VERSION ""

NS_ :

BS_:

BU_: Tester GW APA LCDAR LAS FC BDC ADS ACC FR LCDAL FLC FRC HPP

BO_ 3221225472 VECTOR__INDEPENDENT_SIG_MSG: 0 Vector__XXX
 SG_ HU_CRCCheck_3C4 : 0|8@0+ (1,0) [0|255] "" Vector__XXX
 SG_ HU_RollingCounter_3C4 : 0|4@0+ (1,0) [0|15] "" Vector__XXX
 SG_ HU_RoadCurvature_40m : 0|10@0+ (1,0) [0|1023] "1/m" Vector__XXX
 SG_ HU_RoadCurvature_30m : 0|10@0+ (1,0) [0|1023] "1/m" Vector__XXX
 SG_ HU_RoadCurvature_20m : 0|10@0+ (1,0) [0|1023] "1/m" Vector__XXX
 SG_ HU_RoadCurvature_10m : 0|10@0+ (1,0) [0|1023] "1/m" Vector__XXX
 SG_ HU_Lane_Changtype : 0|2@0+ (1,0) [0|3] "" Vector__XXX
 SG_ HU_To_NumchangeOfLanes_Dist : 0|6@0+ (10,0) [0|600] "m" Vector__XXX
 SG_ HU_CRCCheck_3C6 : 0|8@0+ (1,0) [0|255] "" Vector__XXX
 SG_ HU_RollingCounter_3C6 : 0|4@0+ (1,0) [0|15] "" Vector__XXX
 SG_ HU_RoadCurvature_90m : 0|10@0+ (1,0) [0|1023] "1/m" Vector__XXX
 SG_ HU_RoadCurvature_80m : 0|10@0+ (1,0) [0|1023] "1/m" Vector__XXX
 SG_ HU_RoadCurvature_70m : 0|10@0+ (1,0) [0|1023] "1/m" Vector__XXX
 SG_ HU_RoadCurvature_60m : 0|10@0+ (1,0) [0|1023] "1/m" Vector__XXX
 SG_ HU_RoadCurvature_50m : 0|10@0+ (1,0) [0|1023] "1/m" Vector__XXX
 SG_ HU_BranchInfo : 0|2@0+ (1,0) [0|3] "" Vector__XXX
 SG_ GW_MFS_HODCalibratedStatus : 0|1@0+ (1,0) [0|1] "" Vector__XXX
 SG_ GW_MFS_HODLinStatus : 0|1@0+ (1,0) [0|1] "" Vector__XXX
 SG_ GW_MFS_HODAppStatus : 0|1@0+ (1,0) [0|1] "" Vector__XXX
 SG_ GW_MFS_HODSenserStatus : 0|1@0+ (1,0) [0|1] "" Vector__XXX
 SG_ GW_MFS_HODSystemStatus : 0|3@0+ (1,0) [0|7] "" Vector__XXX
 SG_ GW_MFS_handsoffAbilityDetect : 0|3@0+ (1,0) [0|7] "" Vector__XXX
 SG_ GW_MFS_handsoffDetectResult : 0|3@0+ (1,0) [0|7] "" Vector__XXX
 SG_ GW_MFS_RollingCounter_28C : 0|4@0+ (1,0) [0|15] "" Vector__XXX
 SG_ GW_MFS_DiagInfoSW_28C : 0|3@0+ (1,0) [0|7] "" Vector__XXX
 SG_ HU_CRCCheck_3C7 : 0|8@0+ (1,0) [0|255] "" Vector__XXX
 SG_ HU_RollingCounter_3C7 : 0|4@0+ (1,0) [0|15] "" Vector__XXX
 SG_ HU_MapMatchStatus : 0|2@0+ (1,0) [0|3] "" Vector__XXX
 SG_ HU_SlopeGradient_300m : 0|10@0+ (0.1,-51.1) [-51.1|51.1] "%" Vector__XXX
 SG_ HU_RoadCurvature_600m : 0|10@0+ (1,0) [0|1023] "1/m" Vector__XXX
 SG_ HU_RoadCurvature_400m : 0|10@0+ (1,0) [0|1023] "1/m" Vector__XXX
 SG_ HU_RoadCurvature_300m : 0|10@0+ (1,0) [0|1023] "1/m" Vector__XXX
 SG_ HU_RoadCurvature_100m : 0|10@0+ (1,0) [0|1023] "1/m" Vector__XXX
 SG_ IMS_JawOffsetValue : 0|4@0+ (1,0) [0|15] "cm" Vector__XXX
 SG_ IMS_BrowOffsetValue : 0|4@0+ (1,0) [0|15] "cm" Vector__XXX
 SG_ IMS_RollingCounter_360 : 0|4@0+ (1,0) [0|15] "" Vector__XXX
 SG_ IMS_CRCCheck_360 : 0|8@0+ (1,0) [0|255] "" Vector__XXX
 SG_ IMS_HeadDetectSts_Yaw : 0|8@0+ (1,-75) [-75|75] "deg" Vector__XXX
 SG_ IMS_HeadDetectSts_Roll : 0|8@0+ (1,-45) [-45|45] "deg" Vector__XXX
 SG_ IMS_HeadDetectSts_Pitch : 0|8@0+ (1,-25) [-25|45] "deg" Vector__XXX
 SG_ IMS_PhoneCallSts : 0|1@0+ (1,0) [0|1] "" Vector__XXX
 SG_ IMS_DriverEyesFovArea : 0|4@0+ (1,0) [0|15] "" Vector__XXX
 SG_ IMS_DriverEyeClosestatus : 0|3@0+ (1,0) [0|7] "" Vector__XXX
 SG_ IMS_DriverEyeConfidence : 0|8@0+ (1,0) [0|255] "%" Vector__XXX
 SG_ IMS_DriverEyeDetect : 0|2@0+ (1,0) [0|3] "" Vector__XXX
 SG_ IMS_RollingCounter_356 : 0|4@0+ (1,0) [0|15] "" Vector__XXX
 SG_ IMS_CRCCheck_356 : 0|8@0+ (1,0) [0|255] "" Vector__XXX
 SG_ IMS_IMSStatus : 0|3@0+ (1,0) [0|7] "" Vector__XXX
 SG_ IMS_EyeGazeStatus : 0|8@0+ (1,-75) [-75|75] "deg" Vector__XXX
 SG_ IMS_EyeDetectSatus : 0|8@0+ (1,0) [0|100] "%" Vector__XXX
 SG_ IMS_DrowsinessStatus : 0|3@0+ (1,0) [0|7] "" Vector__XXX
 SG_ IMS_DriverHeadDetect : 0|2@0+ (1,0) [0|3] "" Vector__XXX
 SG_ IMS_DistractionStatus : 0|2@0+ (1,0) [0|3] "" Vector__XXX
 SG_ HU_NavSpeedLimitType : 0|2@0+ (1,0) [0|3] "" Vector__XXX
 SG_ HU_CurveDistance : 0|6@0+ (10,0) [0|600] "m" Vector__XXX
 SG_ HU_EnterCurveInfo : 0|2@0+ (1,0) [0|3] "" Vector__XXX
 SG_ HU_EnterRampInfo : 0|2@0+ (1,0) [0|3] "" Vector__XXX
 SG_ HU_NavCountryCode : 0|8@0+ (1,0) [0|255] "" Vector__XXX
 SG_ HU_NavSpeedLimitUnits : 0|2@0+ (1,0) [0|3] "" Vector__XXX
 SG_ HU_SlopeDistance : 0|6@0+ (10,0) [0|600] "m" Vector__XXX
 SG_ HU_Byroad : 0|2@0+ (1,0) [0|3] "" Vector__XXX
 SG_ HU_RoadCurvatureFar : 0|10@0+ (1,0) [0|1023] "" Vector__XXX
 SG_ HU_RoadCurvature : 0|10@0+ (1,0) [0|1023] "" Vector__XXX
 SG_ HU_EnterSlopeInfo : 0|2@0+ (1,0) [0|3] "" Vector__XXX
 SG_ HU_SpeedLimitDistance : 0|6@0+ (10,0) [0|600] "m" Vector__XXX
 SG_ HU_CRCCheck_3C2 : 0|8@0+ (1,0) [0|255] "" Vector__XXX
 SG_ HU_RollingCounter_3C2 : 0|4@0+ (1,0) [0|15] "" Vector__XXX
 SG_ HU_MapDataUpdateStatus : 0|3@0+ (1,0) [0|7] "" Vector__XXX
 SG_ HU_Road_TrafficFlow : 0|3@0+ (1,0) [0|7] "" Vector__XXX
 SG_ HU_To_Branch_Dis : 0|6@0+ (10,0) [0|600] "m" Vector__XXX
 SG_ HU_To_TrafficAccident_Dis : 0|6@0+ (10,0) [0|600] "m" Vector__XXX
 SG_ HU_TrafficAccident_Info : 0|2@0+ (1,0) [0|3] "" Vector__XXX
 SG_ HU_To_Construction_Dis : 0|6@0+ (10,0) [0|600] "m" Vector__XXX
 SG_ HU_Construction_Info : 0|2@0+ (1,0) [0|3] "" Vector__XXX
 SG_ HU_FallingRockDi : 0|6@0+ (10,0) [0|600] "m" Vector__XXX
 SG_ HU_FallingRockInfo : 0|2@0+ (1,0) [0|3] "" Vector__XXX
 SG_ HU_LaneCnt : 0|3@0+ (1,0) [0|7] "" Vector__XXX
 SG_ HU_ForwardRoadType : 0|3@0+ (1,0) [0|7] "" Vector__XXX
 SG_ HU_RampSide : 0|2@0+ (1,0) [0|3] "" Vector__XXX

BO_ 775 ACC_307: 64 ACC
 SG_ ACC_CSLAEnableStatus : 245|2@0+ (1,0) [0|3] ""  LAS

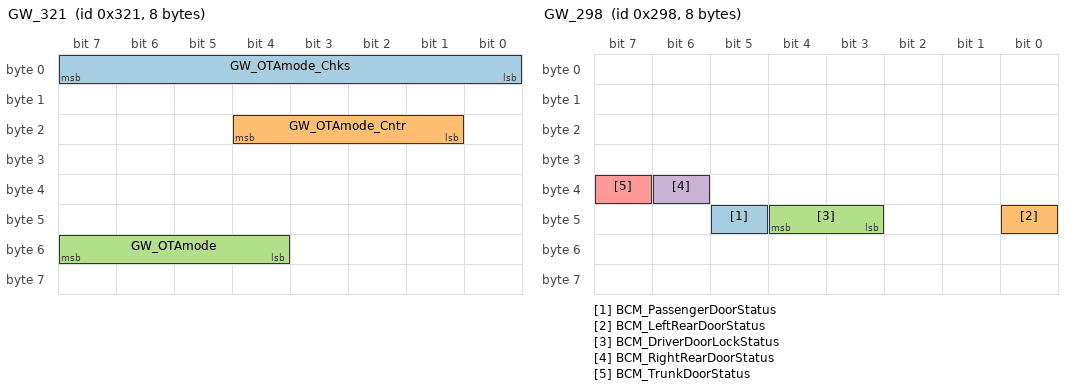
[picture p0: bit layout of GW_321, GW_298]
BO_ 801 GW_321: 8 GW
 SG_ GW_OTAmode_Chks : 7|8@0+ (1,0) [0|255] ""  LAS
 SG_ GW_OTAmode_Cntr : 20|4@0+ (1,0) [0|15] ""  LAS
 SG_ GW_OTAmode : 55|4@0+ (1,0) [0|15] ""  LAS

BO_ 664 GW_298: 8 GW
 SG_ BCM_PassengerDoorStatus : 45|1@0+ (1,0) [0|1] ""  LAS
 SG_ BCM_LeftRearDoorStatus : 40|1@0+ (1,0) [0|1] ""  LAS
 SG_ BCM_DriverDoorLockStatus : 44|2@0+ (1,0) [0|3] ""  LAS
 SG_ BCM_RightRearDoorStatus : 38|1@0+ (1,0) [0|1] ""  LAS
 SG_ BCM_TrunkDoorStatus : 39|1@0+ (1,0) [0|1] ""  LAS

BO_ 2015 DIAG_Function_Req: 8 Tester
 SG_ Functional_Diag_Rx : 7|8@0+ (1,0) [0|0] ""  LAS

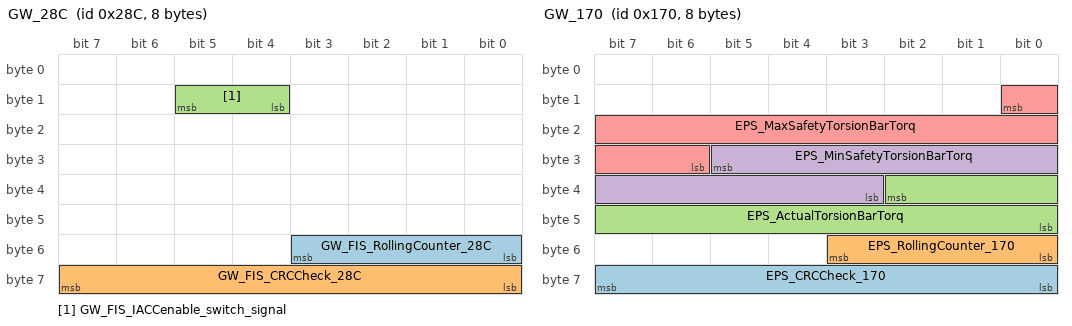
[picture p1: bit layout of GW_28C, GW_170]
BO_ 652 GW_28C: 8 GW
 SG_ GW_FIS_RollingCounter_28C : 51|4@0+ (1,0) [0|15] "0"  LAS
 SG_ GW_FIS_CRCCheck_28C : 63|8@0+ (1,0) [0|255] ""  LAS
 SG_ GW_FIS_IACCenable_switch_signal : 13|2@0+ (1,0) [0|3] ""  GW,BDC,ACC,FR,ADS,LAS

BO_ 864 GW_360: 0 GW

BO_ 854 GW_356: 0 GW

BO_ 368 GW_170: 8 GW
 SG_ EPS_CRCCheck_170 : 63|8@0+ (1,0) [0|255] ""  GW,BDC,ADS,ACC,FR,LAS
 SG_ EPS_RollingCounter_170 : 51|4@0+ (1,0) [0|15] ""  GW,BDC,ADS,ACC,FR,LAS
 SG_ EPS_ActualTorsionBarTorq : 34|11@0+ (0.02,-20.48) [-20.48|20.44] "Nm"  GW,BDC,ADS,ACC,FR,LAS
 SG_ EPS_MinSafetyTorsionBarTorq : 29|11@0+ (0.02,-20.48) [-20.48|20.44] "Nm"  GW,BDC,ADS,ACC,FR,LAS
 SG_ EPS_MaxSafetyTorsionBarTorq : 8|11@0+ (0.02,-20.48) [-20.48|20.44] "Nm"  GW,BDC,ADS,ACC,FR,LAS

BO_ 916 GW_394: 8 GW
 SG_ HU_ELKEnable : 1|2@0+ (1,0) [0|1] ""  GW,BDC,ADS,ACC,FR,LAS
 SG_ HU_TLAEnable : 9|2@0+ (1,0) [0|3] ""  GW,BDC,ADS,ACC,FR,LAS

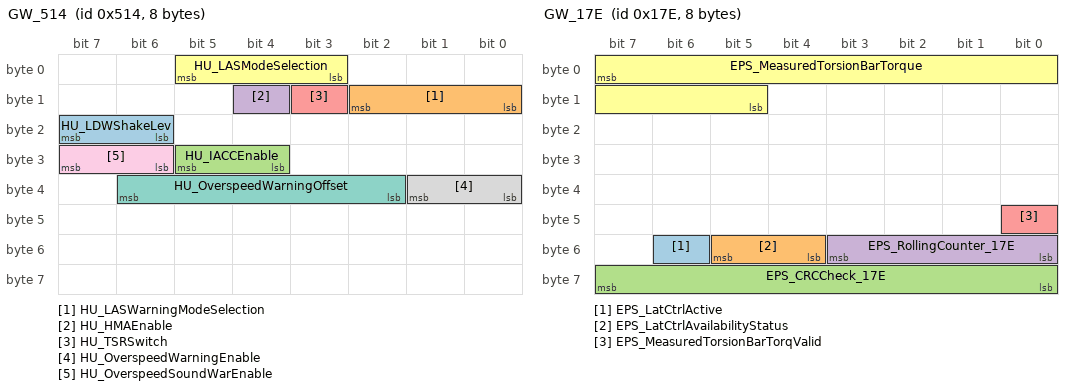
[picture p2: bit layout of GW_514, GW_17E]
BO_ 1300 GW_514: 8 GW
 SG_ HU_LDWShakeLev : 23|2@0+ (1,0) [0|3] ""  GW,BDC,ADS,ACC,FR,LAS
 SG_ HU_LASWarningModeSelection : 10|3@0+ (1,0) [0|7] ""  GW,BDC,APA,ADS,ACC,FR,LAS
 SG_ HU_IACCEnable : 29|2@0+ (1,0) [0|3] ""  GW,BDC,ADS,LAS,ACC,FR
 SG_ HU_HMAEnable : 12|1@0+ (1,0) [0|1] ""  GW,BDC,ADS,ACC,FR,LAS
 SG_ HU_TSRSwitch : 11|1@0+ (1,0) [0|1] ""  GW,BDC,LAS,ADS
 SG_ HU_LASModeSelection : 5|3@0+ (1,0) [0|7] ""  GW,BDC,ADS,ACC,FR,LAS
 SG_ HU_OverspeedWarningOffset : 38|5@0+ (1,-10) [-10|10] ""  GW,BDC,LAS,ADS
 SG_ HU_OverspeedWarningEnable : 33|2@0+ (1,0) [0|3] ""  GW,BDC,LAS
 SG_ HU_OverspeedSoundWarEnable : 31|2@0+ (1,0) [0|3] ""  GW,BDC,LAS,ADS

BO_ 382 GW_17E: 8 GW
 SG_ EPS_LatCtrlActive : 54|1@0+ (1,0) [0|1] ""  GW,BDC,ADS,ACC,FR,LAS
 SG_ EPS_LatCtrlAvailabilityStatus : 53|2@0+ (1,0) [0|3] ""  GW,BDC,ADS,ACC,FR,LAS
 SG_ EPS_CRCCheck_17E : 63|8@0+ (1,0) [0|255] ""  GW,BDC,ADS,ACC,FR,LAS
 SG_ EPS_RollingCounter_17E : 51|4@0+ (1,0) [0|15] ""  GW,BDC,ADS,ACC,FR,LAS
 SG_ EPS_MeasuredTorsionBarTorqValid : 40|1@0+ (1,0) [0|1] ""  GW,BDC,ADS,ACC,FR,LAS
 SG_ EPS_MeasuredTorsionBarTorque : 7|11@0+ (0.01,-10.23) [-10.23|10.23] "Nm"  GW,BDC,ADS,ACC,FR,LAS

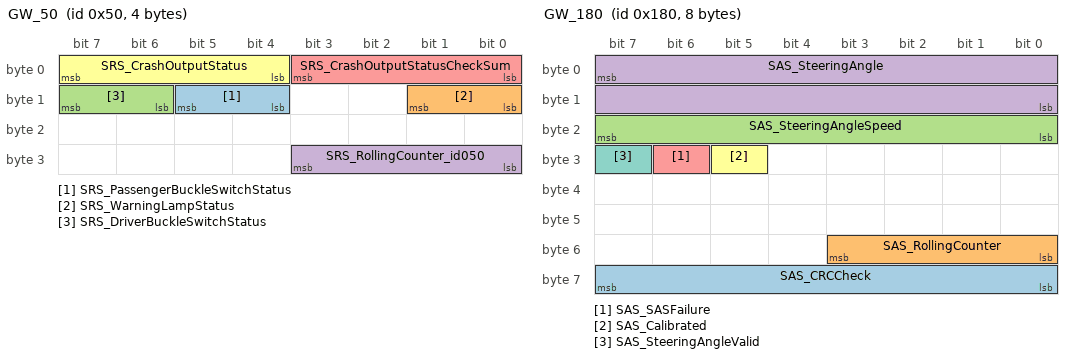
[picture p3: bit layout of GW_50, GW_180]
BO_ 80 GW_50: 4 GW
 SG_ SRS_PassengerBuckleSwitchStatus : 13|2@0+ (1,0) [0|3] ""  GW,BDC,APA,ADS,LAS,LCDAL,LCDAR
 SG_ SRS_WarningLampStatus : 9|2@0+ (1,0) [0|3] ""  GW,BDC,APA,ACC,FR,LAS,LCDAL,LCDAR,FLC,FRC,ADS
 SG_ SRS_DriverBuckleSwitchStatus : 15|2@0+ (1,0) [0|3] ""  GW,BDC,APA,ACC,FR,LAS,LCDAL,LCDAR,FLC,FRC,ADS
 SG_ SRS_RollingCounter_id050 : 27|4@0+ (1,0) [0|15] ""  GW,BDC,APA,ACC,FR,LAS,LCDAL,LCDAR,FLC,FRC,ADS
 SG_ SRS_CrashOutputStatusCheckSum : 3|4@0+ (1,0) [0|15] ""  GW,BDC,APA,ACC,FR,LAS,ADS
 SG_ SRS_CrashOutputStatus : 7|4@0+ (1,0) [0|15] ""  GW,BDC,APA,ACC,FR,LAS,ADS

BO_ 384 GW_180: 8 GW
 SG_ SAS_CRCCheck : 63|8@0+ (1,0) [0|255] ""  GW,BDC,APA,LCDAL,LCDAR,ADS,ACC,FR,LAS,HPP
 SG_ SAS_RollingCounter : 51|4@0+ (1,0) [0|15] ""  GW,BDC,APA,LCDAL,LCDAR,ADS,ACC,FR,LAS,HPP
 SG_ SAS_SteeringAngleSpeed : 23|8@0+ (4,0) [0|1016] "deg/s"  GW,BDC,APA,LCDAL,LCDAR,ADS,ACC,FR,LAS,HPP
 SG_ SAS_SteeringAngle : 7|16@0- (0.1,0) [-780|780] "degree"  GW,BDC,APA,LCDAL,LCDAR,ADS,ACC,FR,LAS,HPP
 SG_ SAS_SASFailure : 30|1@0+ (1,0) [0|1] ""  GW,BDC,APA,LCDAL,LCDAR,ADS,ACC,FR,LAS
 SG_ SAS_Calibrated : 29|1@0+ (1,0) [0|1] ""  GW,BDC,APA,LCDAL,LCDAR,ADS,ACC,FR,LAS
 SG_ SAS_SteeringAngleValid : 31|1@0+ (1,0) [0|1] ""  GW,BDC,APA,LCDAL,LCDAR,ADS,ACC,FR,LAS

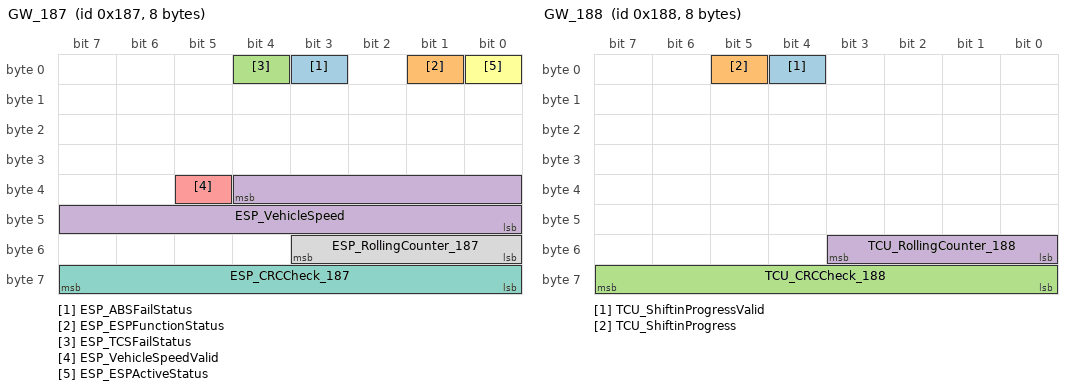
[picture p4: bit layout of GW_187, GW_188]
BO_ 391 GW_187: 8 GW
 SG_ ESP_ABSFailStatus : 3|1@0+ (1,0) [0|1] ""  GW,BDC,APA,ACC,FR,LAS,LCDAL,LCDAR,FLC,FRC,ADS
 SG_ ESP_ESPFunctionStatus : 1|1@0+ (1,0) [0|1] ""  GW,BDC,APA,ACC,FR,LAS,LCDAL,LCDAR,FLC,FRC,ADS
 SG_ ESP_TCSFailStatus : 4|1@0+ (1,0) [0|1] ""  GW,BDC,APA,ACC,FR,LAS,LCDAL,LCDAR,FLC,FRC,ADS
 SG_ ESP_VehicleSpeed : 36|13@0+ (0.05625,0) [0|360] "km/h"  GW,BDC,APA,ACC,FR,LAS,LCDAL,LCDAR,FLC,FRC,ADS,HPP
 SG_ ESP_VehicleSpeedValid : 37|1@0+ (1,0) [0|1] ""  GW,BDC,APA,ACC,FR,LAS,LCDAL,LCDAR,FLC,FRC,ADS,HPP
 SG_ ESP_ESPActiveStatus : 0|1@0+ (1,0) [0|1] ""  GW,BDC,APA,ACC,FR,LAS,LCDAL,LCDAR,FLC,FRC,ADS
 SG_ ESP_CRCCheck_187 : 63|8@0+ (1,0) [0|255] ""  GW,BDC,APA,ACC,FR,LAS,LCDAL,LCDAR,FLC,FRC,ADS,HPP
 SG_ ESP_RollingCounter_187 : 51|4@0+ (1,0) [0|15] ""  GW,BDC,APA,ACC,FR,LAS,LCDAL,LCDAR,FLC,FRC,ADS,HPP

BO_ 392 GW_188: 8 GW
 SG_ TCU_ShiftinProgressValid : 4|1@0+ (1,0) [0|1] ""  GW,BDC,ADS,ACC,FR,LAS
 SG_ TCU_ShiftinProgress : 5|1@0+ (1,0) [0|1] ""  GW,BDC,ADS,ACC,FR,LAS
 SG_ TCU_CRCCheck_188 : 63|8@0+ (1,0) [0|255] ""  GW,BDC,ADS,ACC,FR,LAS
 SG_ TCU_RollingCounter_188 : 51|4@0+ (1,0) [0|15] ""  GW,BDC,ADS,ACC,FR,LAS

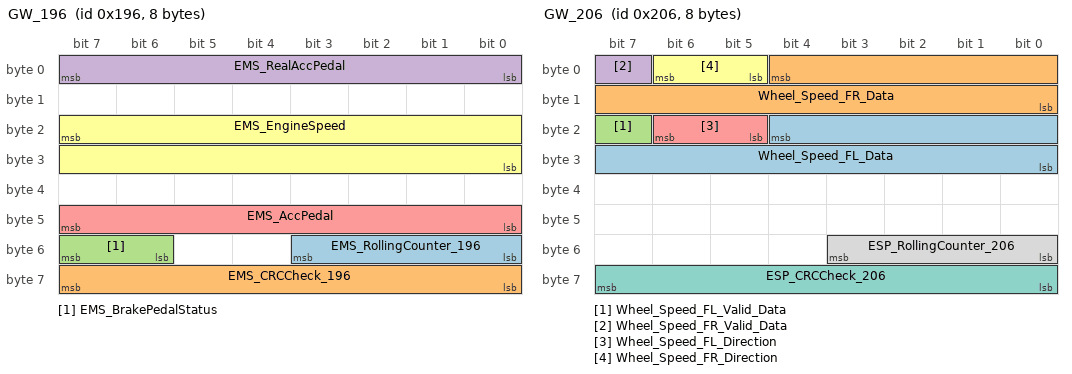
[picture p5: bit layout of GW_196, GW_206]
BO_ 406 GW_196: 8 GW
 SG_ EMS_RollingCounter_196 : 51|4@0+ (1,0) [0|15] ""  GW,BDC,APA,LCDAL,LCDAR,ADS,ACC,FR,FLC,FRC,LAS
 SG_ EMS_CRCCheck_196 : 63|8@0+ (1,0) [0|255] ""  GW,BDC,APA,LCDAL,LCDAR,ADS,ACC,FR,FLC,FRC,LAS
 SG_ EMS_BrakePedalStatus : 55|2@0+ (1,0) [0|3] ""  GW,BDC,APA,LCDAL,LCDAR,ADS,ACC,FR,FLC,FRC,LAS
 SG_ EMS_RealAccPedal : 7|8@0+ (0.392,0) [0|99.568] "%"  GW,BDC,APA,LCDAL,LCDAR,ADS,ACC,FR,FLC,FRC,LAS
 SG_ EMS_AccPedal : 47|8@0+ (0.392,0) [0|99.568] "%"  GW,BDC,APA,ADS,ACC,FR,LAS
 SG_ EMS_EngineSpeed : 23|16@0+ (0.25,0) [0|16383.5] "Rpm"  GW,BDC,APA,ADS,ACC,FR,LAS

BO_ 518 GW_206: 8 GW
 SG_ Wheel_Speed_FL_Data : 20|13@0+ (0.05625,0) [0|360] "km/h"  GW,BDC,APA,ACC,FR,LAS,LCDAL,LCDAR,FLC,FRC,ADS,HPP
 SG_ Wheel_Speed_FR_Data : 4|13@0+ (0.05625,0) [0|360] "km/h"  GW,BDC,APA,ACC,FR,LAS,LCDAL,LCDAR,FLC,FRC,ADS,HPP
 SG_ Wheel_Speed_FL_Valid_Data : 23|1@0+ (1,0) [0|1] ""  GW,BDC,APA,ACC,FR,LAS,LCDAL,LCDAR,FLC,FRC,ADS,HPP
 SG_ Wheel_Speed_FR_Valid_Data : 7|1@0+ (1,0) [0|1] ""  GW,BDC,APA,ACC,FR,LAS,LCDAL,LCDAR,FLC,FRC,ADS,HPP
 SG_ Wheel_Speed_FL_Direction : 22|2@0+ (1,0) [0|3] ""  GW,BDC,APA,ACC,FR,LAS,LCDAL,LCDAR,FLC,FRC,ADS
 SG_ Wheel_Speed_FR_Direction : 6|2@0+ (1,0) [0|3] ""  GW,BDC,APA,ACC,FR,LAS,LCDAL,LCDAR,FLC,FRC,ADS
 SG_ ESP_CRCCheck_206 : 63|8@0+ (1,0) [0|255] ""  GW,BDC,APA,ACC,FR,LAS,LCDAL,LCDAR,FLC,FRC,ADS,HPP
 SG_ ESP_RollingCounter_206 : 51|4@0+ (1,0) [0|15] ""  GW,BDC,APA,ACC,FR,LAS,LCDAL,LCDAR,FLC,FRC,ADS,HPP

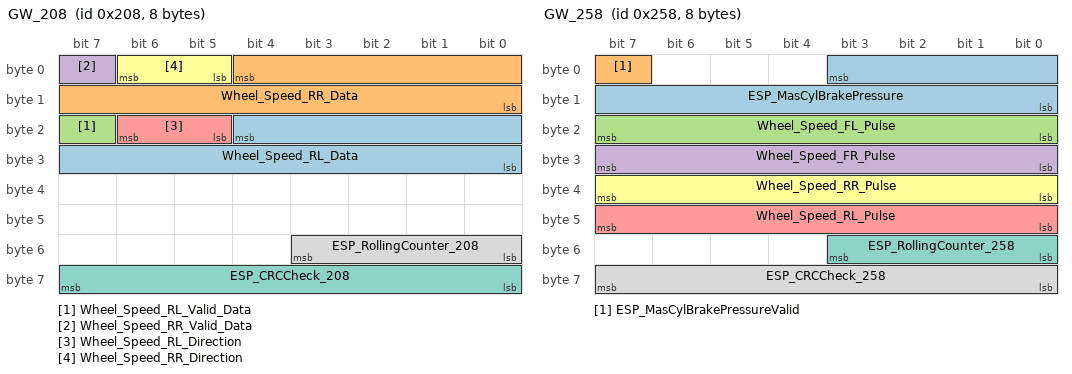
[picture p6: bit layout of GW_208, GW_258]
BO_ 520 GW_208: 8 GW
 SG_ Wheel_Speed_RL_Data : 20|13@0+ (0.05625,0) [0|360] "km/h"  GW,BDC,APA,ACC,FR,LAS,LCDAL,LCDAR,FLC,FRC,ADS,HPP
 SG_ Wheel_Speed_RR_Data : 4|13@0+ (0.05625,0) [0|360] "km/h"  GW,BDC,APA,ACC,FR,LAS,LCDAL,LCDAR,FLC,FRC,ADS,HPP
 SG_ Wheel_Speed_RL_Valid_Data : 23|1@0+ (1,0) [0|1] ""  GW,BDC,APA,ACC,FR,LAS,LCDAL,LCDAR,FLC,FRC,ADS,HPP
 SG_ Wheel_Speed_RR_Valid_Data : 7|1@0+ (1,0) [0|1] ""  GW,BDC,APA,ACC,FR,LAS,LCDAL,LCDAR,FLC,FRC,ADS,HPP
 SG_ Wheel_Speed_RL_Direction : 22|2@0+ (1,0) [0|3] ""  GW,BDC,APA,ACC,FR,LAS,LCDAL,LCDAR,FLC,FRC,ADS
 SG_ Wheel_Speed_RR_Direction : 6|2@0+ (1,0) [0|3] ""  GW,BDC,APA,ACC,FR,LAS,LCDAL,LCDAR,FLC,FRC,ADS
 SG_ ESP_CRCCheck_208 : 63|8@0+ (1,0) [0|255] ""  GW,BDC,APA,ACC,FR,LAS,LCDAL,LCDAR,FLC,FRC,ADS,HPP
 SG_ ESP_RollingCounter_208 : 51|4@0+ (1,0) [0|15] ""  GW,BDC,APA,ACC,FR,LAS,LCDAL,LCDAR,FLC,FRC,ADS,HPP

BO_ 600 GW_258: 8 GW
 SG_ ESP_MasCylBrakePressure : 3|12@0+ (0.1,0) [0|250] "Bar"  GW,BDC,APA,ACC,FR,LAS,LCDAL,LCDAR,FLC,FRC,ADS
 SG_ ESP_MasCylBrakePressureValid : 7|1@0+ (1,0) [0|1] ""  GW,BDC,APA,ACC,FR,LAS,LCDAL,LCDAR,FLC,FRC,ADS
 SG_ Wheel_Speed_FL_Pulse : 23|8@0+ (1,0) [0|254] ""  GW,BDC,APA,ACC,FR,LAS,LCDAL,LCDAR,FLC,FRC,ADS,HPP
 SG_ Wheel_Speed_FR_Pulse : 31|8@0+ (1,0) [0|254] ""  GW,BDC,APA,ACC,FR,LAS,LCDAL,LCDAR,FLC,FRC,ADS,HPP
 SG_ Wheel_Speed_RL_Pulse : 47|8@0+ (1,0) [0|254] ""  GW,BDC,APA,ACC,FR,LAS,LCDAL,LCDAR,FLC,FRC,ADS,HPP
 SG_ Wheel_Speed_RR_Pulse : 39|8@0+ (1,0) [0|254] ""  GW,BDC,APA,ACC,FR,LAS,LCDAL,LCDAR,FLC,FRC,ADS,HPP
 SG_ ESP_RollingCounter_258 : 51|4@0+ (1,0) [0|15] ""  GW,BDC,APA,ACC,FR,LAS,LCDAL,LCDAR,FLC,FRC,ADS,HPP
 SG_ ESP_CRCCheck_258 : 63|8@0+ (1,0) [0|255] ""  GW,BDC,APA,ACC,FR,LAS,LCDAL,LCDAR,FLC,FRC,ADS,HPP

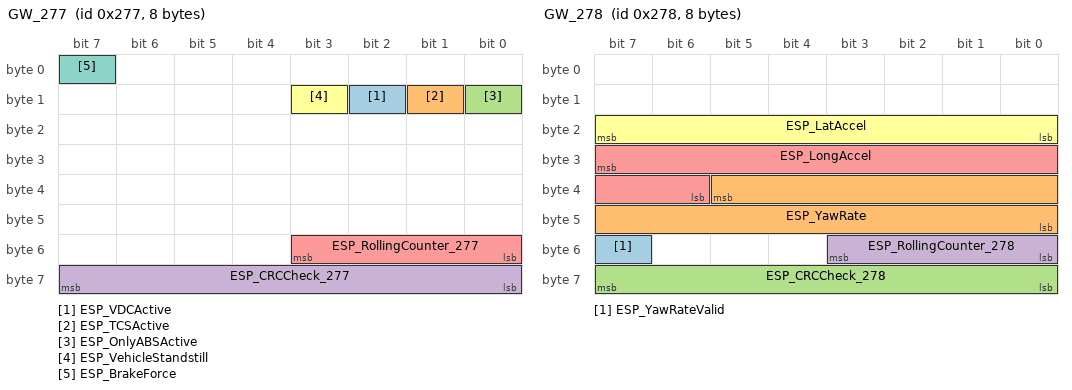
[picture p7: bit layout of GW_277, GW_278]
BO_ 631 GW_277: 8 GW
 SG_ ESP_VDCActive : 10|1@0+ (1,0) [0|1] ""  GW,BDC,ADS,ACC,FR,LCDAL,LCDAR,FLC,FRC,LAS
 SG_ ESP_TCSActive : 9|1@0+ (1,0) [0|1] ""  GW,BDC,ADS,ACC,FR,LCDAL,LCDAR,FLC,FRC,LAS
 SG_ ESP_OnlyABSActive : 8|1@0+ (1,0) [0|1] ""  GW,BDC,ADS,ACC,FR,LCDAL,LCDAR,FLC,FRC,LAS
 SG_ ESP_CRCCheck_277 : 63|8@0+ (1,0) [0|255] ""  GW,BDC,APA,ADS,ACC,FR,LAS,LCDAL,LCDAR,FLC,FRC
 SG_ ESP_RollingCounter_277 : 51|4@0+ (1,0) [0|15] ""  GW,BDC,APA,ADS,ACC,FR,LAS,LCDAL,LCDAR,FLC,FRC
 SG_ ESP_VehicleStandstill : 11|1@0+ (1,0) [0|1] ""  GW,BDC,APA,ADS,ACC,FR,LAS,LCDAL,LCDAR,FLC,FRC
 SG_ ESP_BrakeForce : 7|1@0+ (1,0) [0|1] ""  GW,BDC,ADS,ACC,FR,LCDAL,LCDAR,FLC,FRC,LAS,APA

BO_ 632 GW_278: 8 GW
 SG_ ESP_YawRateValid : 55|1@0+ (1,0) [0|1] ""  GW,BDC,APA,ACC,FR,LAS,LCDAL,LCDAR,FLC,FRC,ADS,HPP
 SG_ ESP_YawRate : 37|14@0+ (0.01,-81.91) [-81.91|81.91] "degree/s"  GW,BDC,APA,ACC,FR,LAS,LCDAL,LCDAR,FLC,FRC,ADS,HPP
 SG_ ESP_CRCCheck_278 : 63|8@0+ (1,0) [0|255] ""  GW,BDC,APA,ACC,FR,LAS,LCDAL,LCDAR,FLC,FRC,ADS,HPP
 SG_ ESP_RollingCounter_278 : 51|4@0+ (1,0) [0|15] ""  GW,BDC,APA,ACC,FR,LAS,LCDAL,LCDAR,FLC,FRC,ADS,HPP
 SG_ ESP_LongAccel : 31|10@0+ (0.03125,-16) [-16|15.90625] "m/s2"  GW,BDC,APA,ACC,FR,LAS,LCDAL,LCDAR,FLC,FRC,ADS,HPP
 SG_ ESP_LatAccel : 23|8@0+ (0.1,-12.7) [-12.7|12.7] "m/s2"  GW,BDC,APA,ACC,FR,LAS,LCDAL,LCDAR,FLC,FRC,ADS,HPP

BO_ 832 GW_340: 8 GW
 SG_ AC_FrBlowType : 2|3@0+ (1,0) [0|7] ""  GW,BDC,ADS,ACC,FR,LAS

BO_ 870 GW_366: 8 GW
 SG_ AC_EnvironmentalTemp : 23|8@0+ (0.5,-40) [-40|87] "degreeC"  GW,BDC,APA,ACC,FR,LAS,LCDAL,LCDAR,FLC,FRC,ADS
 SG_ AC_EnvironmentalTempVD : 8|1@0+ (1,0) [0|1] ""  GW,BDC,APA,ACC,FR,LAS,LCDAL,LCDAR,FLC,FRC,ADS

BO_ 903 GW_387: 8 GW
 SG_ BCM_RainfallLevel : 19|4@0+ (1,0) [0|15] ""  GW,BDC,ADS,ACC,FR,LAS,LCDAL,LCDAR,APA
 SG_ BCM_FrontWiperStatus : 25|2@0+ (1,0) [0|3] ""  GW,BDC,APA,ACC,FR,LAS,LCDAL,LCDAR,FLC,FRC,ADS

BO_ 912 GW_390: 8 GW
 SG_ BCM_SOH_LifePercent : 15|8@0+ (1,0) [0|100] "%"  GW,BDC,ADS,ACC,FR,LAS,LCDAL,LCDAR
 SG_ BCM_PMSLevel : 5|3@0+ (1,0) [0|7] ""  GW,BDC,ADS,ACC,FR,LAS,LCDAL,LCDAR

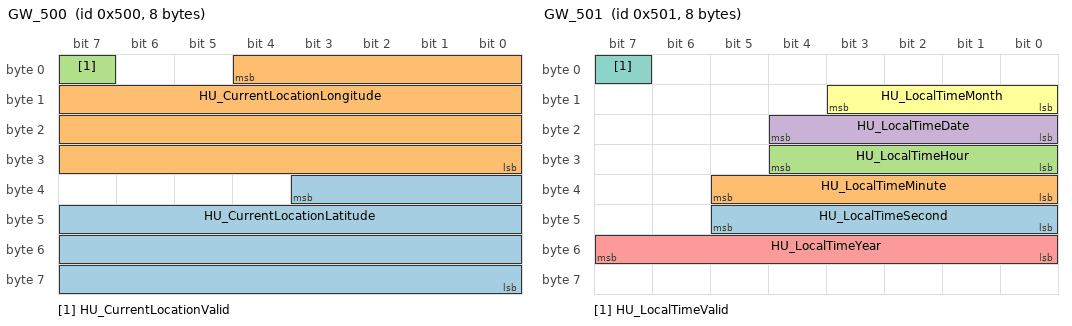
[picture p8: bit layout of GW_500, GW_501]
BO_ 1280 GW_500: 8 GW
 SG_ HU_CurrentLocationLatitude : 35|28@0+ (1E-006,-134.217727) [-90|90] "degree"  GW,BDC,APA,ADS,ACC,FR,LAS,LCDAL,LCDAR
 SG_ HU_CurrentLocationLongitude : 4|29@0+ (1E-006,-268.435455) [-180|180] "degree"  GW,BDC,APA,ADS,ACC,FR,LAS,LCDAL,LCDAR
 SG_ HU_CurrentLocationValid : 7|1@0+ (1,0) [0|1] ""  GW,BDC,APA,ADS,ACC,FR,LAS,LCDAL,LCDAR

BO_ 1281 GW_501: 8 GW
 SG_ HU_LocalTimeSecond : 45|6@0+ (1,0) [0|59] "second"  GW,BDC,APA,ACC,FR,LAS,LCDAL,LCDAR,FLC,FRC,ADS
 SG_ HU_LocalTimeMinute : 37|6@0+ (1,0) [0|59] "minute"  GW,BDC,APA,ACC,FR,LAS,LCDAL,LCDAR,FLC,FRC,ADS
 SG_ HU_LocalTimeHour : 28|5@0+ (1,0) [0|23] "hour"  GW,BDC,APA,ACC,FR,LAS,LCDAL,LCDAR,FLC,FRC,ADS
 SG_ HU_LocalTimeDate : 20|5@0+ (1,0) [1|31] "day"  GW,BDC,APA,ACC,FR,LAS,LCDAL,LCDAR,FLC,FRC,ADS
 SG_ HU_LocalTimeYear : 55|8@0+ (1,2013) [2013|2268] "year"  GW,BDC,APA,ACC,FR,LAS,LCDAL,LCDAR,FLC,FRC,ADS
 SG_ HU_LocalTimeMonth : 11|4@0+ (1,0) [1|12] "month"  GW,BDC,APA,ACC,FR,LAS,LCDAL,LCDAR,FLC,FRC,ADS
 SG_ HU_LocalTimeValid : 7|1@0+ (1,0) [0|1] ""  GW,BDC,APA,ACC,FR,LAS,LCDAL,LCDAR,FLC,FRC,ADS

BO_ 1328 GW_530: 8 GW
 SG_ IP_TotalOdometer : 23|24@0+ (0.1,0) [0|999999] "Km"  GW,BDC,ADS,LAS,ACC,FR,LCDAL,LCDAR,HPP,APA

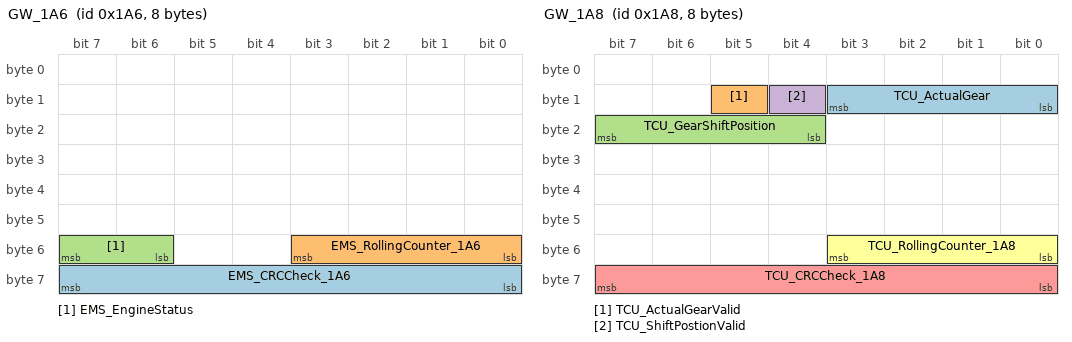
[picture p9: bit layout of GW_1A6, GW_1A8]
BO_ 422 GW_1A6: 8 GW
 SG_ EMS_CRCCheck_1A6 : 63|8@0+ (1,0) [0|255] ""  GW,BDC,APA,ADS,ACC,FR,LAS,LCDAL,LCDAR,FLC,FRC
 SG_ EMS_RollingCounter_1A6 : 51|4@0+ (1,0) [0|15] ""  GW,BDC,APA,ADS,ACC,FR,LAS,LCDAL,LCDAR,FLC,FRC
 SG_ EMS_EngineStatus : 55|2@0+ (1,0) [0|3] ""  GW,BDC,APA,ADS,ACC,FR,LAS,LCDAL,LCDAR,FLC,FRC

BO_ 424 GW_1A8: 8 GW
 SG_ TCU_ActualGear : 11|4@0+ (1,0) [0|15] ""  GW,BDC,APA,ADS,ACC,FR,LAS,LCDAL,LCDAR,FLC,FRC,HPP
 SG_ TCU_ActualGearValid : 13|1@0+ (1,0) [0|1] ""  GW,BDC,APA,ADS,ACC,FR,LAS,LCDAL,LCDAR,FLC,FRC,HPP
 SG_ TCU_GearShiftPosition : 23|4@0+ (1,0) [0|15] ""  GW,BDC,APA,ADS,ACC,FR,LAS,LCDAL,LCDAR,FLC,FRC,HPP
 SG_ TCU_ShiftPostionValid : 12|1@0+ (1,0) [0|1] ""  GW,BDC,APA,ADS,ACC,FR,LAS,LCDAL,LCDAR,FLC,FRC,HPP
 SG_ TCU_CRCCheck_1A8 : 63|8@0+ (1,0) [0|255] ""  GW,BDC,APA,ADS,ACC,FR,LAS,LCDAL,LCDAR,FLC,FRC,HPP
 SG_ TCU_RollingCounter_1A8 : 51|4@0+ (1,0) [0|15] ""  GW,BDC,APA,ADS,ACC,FR,LAS,LCDAL,LCDAR,FLC,FRC,HPP

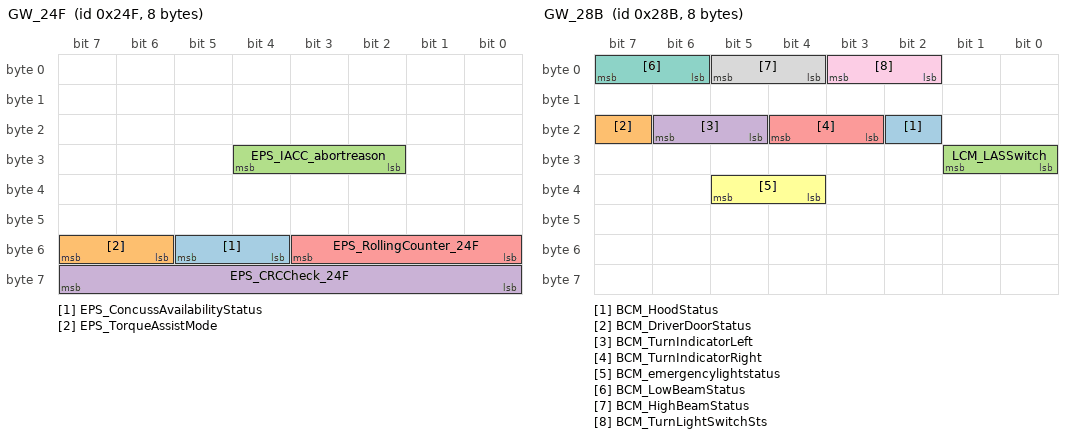
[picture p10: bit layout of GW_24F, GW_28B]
BO_ 591 GW_24F: 8 GW
 SG_ EPS_ConcussAvailabilityStatus : 53|2@0+ (1,0) [0|3] ""  GW,BDC,ADS,ACC,FR,LAS
 SG_ EPS_TorqueAssistMode : 55|2@0+ (1,0) [0|3] ""  GW,BDC,ADS,ACC,FR,LAS
 SG_ EPS_IACC_abortreason : 28|3@0+ (1,0) [0|7] ""  GW,BDC,APA,ADS,ACC,FR,LAS
 SG_ EPS_CRCCheck_24F : 63|8@0+ (1,0) [0|255] ""  GW,BDC,ADS,ACC,FR,LAS,APA
 SG_ EPS_RollingCounter_24F : 51|4@0+ (1,0) [0|15] ""  GW,BDC,ADS,ACC,FR,LAS,APA

BO_ 651 GW_28B: 8 GW
 SG_ BCM_HoodStatus : 18|1@0+ (1,0) [0|1] ""  LAS
 SG_ BCM_DriverDoorStatus : 23|1@0+ (1,0) [0|1] ""  LAS
 SG_ LCM_LASSwitch : 25|2@0+ (1,0) [0|3] ""  GW,BDC,APA,ADS,LAS
 SG_ BCM_TurnIndicatorLeft : 22|2@0+ (1,0) [0|3] ""  GW,BDC,APA,ADS,ACC,FR,LAS
 SG_ BCM_TurnIndicatorRight : 20|2@0+ (1,0) [0|3] ""  GW,BDC,APA,ADS,ACC,FR,LAS
 SG_ BCM_emergencylightstatus : 37|2@0+ (1,0) [0|3] ""  GW,BDC,APA,ADS,LAS,ACC
 SG_ BCM_LowBeamStatus : 7|2@0+ (1,0) [0|3] ""  GW,BDC,ADS,LAS,APA
 SG_ BCM_HighBeamStatus : 5|2@0+ (1,0) [0|3] ""  GW,BDC,ADS,LAS,APA
 SG_ BCM_TurnLightSwitchSts : 3|2@0+ (1,0) [0|3] ""  GW,BDC,APA,LCDAL,LCDAR,ADS,LAS,ACC,FR

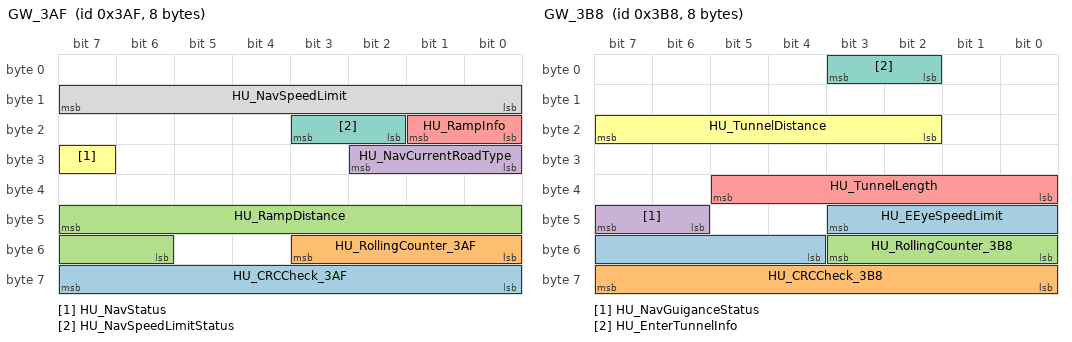
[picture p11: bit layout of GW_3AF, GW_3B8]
BO_ 943 GW_3AF: 8 GW
 SG_ HU_CRCCheck_3AF : 63|8@0+ (1,0) [0|255] ""  GW,BDC,ADS,LAS,ACC,FR
 SG_ HU_RollingCounter_3AF : 51|4@0+ (1,0) [0|15] ""  GW,BDC,ADS,LAS,ACC,FR
 SG_ HU_RampDistance : 47|10@0+ (10,0) [0|3000] "m"  GW,BDC,ADS,LAS,ACC,FR
 SG_ HU_NavCurrentRoadType : 26|3@0+ (1,0) [0|7] ""  GW,BDC,ADS,LAS,ACC,FR
 SG_ HU_RampInfo : 17|2@0+ (1,0) [0|3] ""  GW,BDC,ADS,LAS,ACC,FR
 SG_ HU_NavStatus : 31|1@0+ (1,0) [0|1] ""  GW,BDC,ADS,LAS,ACC,FR
 SG_ HU_NavSpeedLimitStatus : 19|2@0+ (1,0) [0|3] ""  GW,BDC,ADS,LAS
 SG_ HU_NavSpeedLimit : 15|8@0+ (1,0) [0|255] ""  GW,BDC,ADS,LAS,ACC,FR

BO_ 952 GW_3B8: 8 GW
 SG_ HU_EEyeSpeedLimit : 43|8@0+ (1,0) [0|255] ""  LAS
 SG_ HU_CRCCheck_3B8 : 63|8@0+ (1,0) [0|255] ""  GW,BDC,ADS,LAS,ACC,FR
 SG_ HU_RollingCounter_3B8 : 51|4@0+ (1,0) [0|15] ""  GW,BDC,ADS,LAS,ACC,FR
 SG_ HU_NavGuiganceStatus : 47|2@0+ (1,0) [0|3] ""  GW,BDC,ADS,LAS,ACC,FR
 SG_ HU_TunnelLength : 37|6@0+ (1,0) [0|63] "m"  GW,BDC,ADS,LAS,ACC,FR
 SG_ HU_TunnelDistance : 23|6@0+ (10,0) [0|600] "m"  GW,BDC,ADS,LAS,ACC,FR
 SG_ HU_EnterTunnelInfo : 3|2@0+ (1,0) [0|3] ""  GW,BDC,ADS,LAS,ACC,FR

BO_ 955 GW_3BB: 0 GW

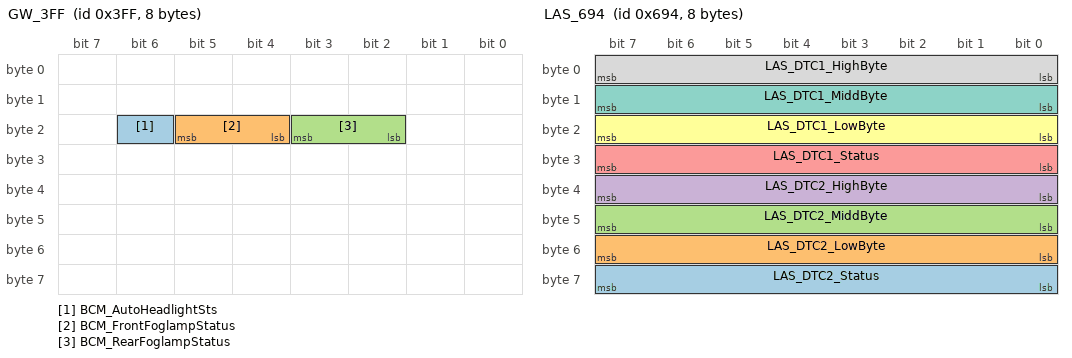
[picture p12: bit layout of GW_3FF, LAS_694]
BO_ 1023 GW_3FF: 8 GW
 SG_ BCM_AutoHeadlightSts : 22|1@0+ (1,0) [0|1] ""  GW,BDC,LAS,ADS
 SG_ BCM_FrontFoglampStatus : 21|2@0+ (1,0) [0|3] ""  GW,BDC,ADS,ACC,FR,LAS,APA
 SG_ BCM_RearFoglampStatus : 19|2@0+ (1,0) [0|3] ""  GW,BDC,ADS,ACC,FR,LAS,APA

BO_ 583 APA_247: 32 APA
 SG_ APA_APAOnOff : 6|1@0+ (1,0) [0|1] ""  APA,GW,BDC,ADS,ACC,LAS

BO_ 676 LCDAR_2A4: 64 LCDAR
 SG_ LCDAR_CRCCheck_2AF : 63|8@0+ (1,0) [0|255] ""  ADS,LCDAR,GW,BDC,LAS,FR,ACC
 SG_ LCDAR_RollingCounter_2AF : 51|4@0+ (1,0) [0|15] ""  ADS,LCDAR,GW,BDC,LAS,FR,ACC
 SG_ LCDAR_ELK_oAlert : 25|2@0+ (1,0) [0|3] ""  LCDAR,GW,BDC,ADS,LAS,FR,ACC
 SG_ LCDAR_ELK_oStatus : 27|2@0+ (1,0) [0|3] ""  LCDAL,LCDAR,ADS,GW,LAS,FR,ACC
 SG_ LCDAR_Left_ELK_oAlert : 29|2@0+ (1,0) [0|3] ""  LCDAL,LCDAR,ADS,GW,LAS,FR,ACC
 SG_ LCDAR_BSD_LCAStatus : 23|2@0+ (1,0) [0|3] ""  ADS,LCDAR,GW,BDC,LAS

BO_ 922 LAS_39A: 32 LAS
 SG_ LAS_TLAObjectType_HostLane : 212|3@0+ (1,0) [0|7] ""  ADS,BDC,GW
 SG_ LAS_TSRRightLaneStatus : 55|3@0+ (1,0) [0|7] ""  ADS,GW,BDC
 SG_ LAS_TSRLeftLaneStatus : 47|3@0+ (1,0) [0|7] ""  ADS,GW,BDC
 SG_ LAS_CRCCheck_3C0 : 191|8@0+ (1,0) [0|255] ""  ADS,GW,BDC
 SG_ LAS_RollingCounter_3C0 : 179|4@0+ (1,0) [0|15] ""  ADS,GW,BDC
 SG_ LAS_TSRRightLaneSpdLimit : 143|8@0+ (1,0) [0|255] ""  ADS,GW,BDC
 SG_ LAS_TSRLeftLaneSpdLimit : 135|8@0+ (1,0) [0|255] ""  ADS,GW,BDC
 SG_ LAS_CRCCheck_3D4 : 127|8@0+ (1,0) [0|255] ""  ADS,GW,BDC
 SG_ LAS_RollingCounter_3D4 : 115|4@0+ (1,0) [0|15] ""  ADS,GW,BDC
 SG_ LAS_TLAStopLine_HostLane : 111|8@0+ (1,0) [0|255] ""  ADS,GW,BDC
 SG_ LAS_TLADistance_HostLane : 103|8@0+ (1,0) [0|255] ""  ADS,GW,BDC
 SG_ LAS_TLACountDownTime_HostLane : 94|7@0+ (1,0) [0|127] ""  ADS,GW,BDC
 SG_ LAS_TSRMandatorySign : 70|4@0+ (1,0) [0|15] ""  ADS,ACC,GW,BDC
 SG_ LAS_TSRWarningSign : 83|4@0+ (1,0) [0|15] ""  ADS,ACC,GW,BDC
 SG_ LAS_TSRProhibitionSign : 66|5@0+ (1,0) [0|31] ""  ADS,ACC,GW,BDC
 SG_ LAS_CRCCheck_332 : 63|8@0+ (1,0) [0|255] ""  GW,BDC,ADS
 SG_ LAS_RollingCounter_332 : 51|4@0+ (1,0) [0|15] ""  GW,BDC,ADS
 SG_ LAS_OverspeedSoundWarningEnSt : 27|1@0+ (1,0) [0|1] ""  ADS,GW,BDC
 SG_ LAS_TSREnable : 30|1@0+ (1,0) [0|1] ""  ADS,GW,BDC
 SG_ LAS_HMAEnableStatus : 22|1@0+ (1,0) [0|1] ""  ADS,GW,BDC
 SG_ LAS_HMALightDistribution : 8|1@0+ (1,0) [0|1] ""  ADS,GW,BDC
 SG_ LAS_HMAStatus : 44|2@0+ (1,0) [0|3] ""  ADS,GW,BDC
 SG_ LAS_TSRHostSpdLimitUnits : 41|2@0+ (1,0) [0|3] ""  ADS,GW,BDC
 SG_ LAS_TSRHostSpdLimit : 39|8@0+ (1,0) [0|255] ""  ADS,GW,BDC
 SG_ LAS_TSRStatus : 26|3@0+ (1,0) [0|7] ""  ADS,GW,BDC
 SG_ LAS_FrontCameraCalibrationStatus : 20|2@0+ (1,0) [0|3] ""  ADS,GW,BDC
 SG_ LAS_FrontCameraFailureStatus : 17|2@0+ (1,0) [0|3] ""  ADS,GW,BDC
 SG_ LAS_OverspeedWarningOffset : 14|5@0+ (1,-10) [-10|10] "km/h"  ADS,GW,BDC
 SG_ LAS_OverspeedWarningEnableStatus : 15|1@0+ (1,0) [0|1] ""  ADS,GW,BDC
 SG_ LAS_OverspeedSoundWarning : 2|1@0+ (1,0) [0|1] ""  ADS,GW,BDC
 SG_ LAS_OverspeedVisualWarning : 5|1@0+ (1,0) [0|1] ""  ADS,GW,BDC
 SG_ LAS_CRCCheck_37D : 255|8@0+ (1,0) [0|255] ""  ADS,GW,BDC
 SG_ LAS_RollingCounter_37D : 243|4@0+ (1,0) [0|15] ""  ADS,GW,BDC
 SG_ LAS_TLAArrowDirection_RightLane : 236|3@0+ (1,0) [0|7] ""  ADS,GW,BDC
 SG_ LAS_TLAObjectType_RightLane : 239|3@0+ (1,0) [0|7] ""  ADS,GW,BDC
 SG_ LAS_TLAObjectStatus_RightLane : 247|2@0+ (1,0) [0|3] ""  ADS,GW,BDC
 SG_ LAS_TLAObjectColour_RightLane : 225|2@0+ (1,0) [0|3] ""  ADS,GW,BDC
 SG_ LAS_TLAObjectDetection_RightLane : 227|1@0+ (1,0) [0|1] ""  ADS,GW,BDC
 SG_ LAS_TLAArrowDirection_LeftLane : 216|3@0+ (1,0) [0|7] ""  ADS,GW,BDC
 SG_ LAS_TLAObjectType_LeftLane : 219|3@0+ (1,0) [0|7] ""  ADS,GW,BDC
 SG_ LAS_TLAObjectStatus_LeftLane : 245|2@0+ (1,0) [0|3] ""  ADS,GW,BDC
 SG_ LAS_TLAObjectColour_LeftLane : 221|2@0+ (1,0) [0|3] ""  ADS,GW,BDC
 SG_ LAS_TLAObjectDetection_LeftLane : 223|1@0+ (1,0) [0|1] ""  ADS,GW,BDC
 SG_ LAS_TLAArrowDirection_HostLane : 215|3@0+ (1,0) [0|7] ""  ADS,GW,BDC
 SG_ LAS_TLAObjectStatus_HostLane : 199|2@0+ (1,0) [0|3] ""  ADS,GW,BDC
 SG_ LAS_TLAObjectColour_HostLane : 204|2@0+ (1,0) [0|3] ""  ADS,GW,BDC
 SG_ LAS_TLAObjectDetection_HostLane : 200|1@0+ (1,0) [0|1] ""  ADS,GW,BDC
 SG_ LAS_TLAWarninglevel : 197|2@0+ (1,0) [0|3] ""  ADS,GW,BDC
 SG_ LAS_TLAStatus : 193|2@0+ (1,0) [0|3] ""  ADS,GW,BDC
 SG_ LAS_TLAEnable : 194|1@0+ (1,0) [0|1] ""  ADS,GW,BDC

BO_ 1684 LAS_694: 8 LAS
 SG_ LAS_DTC2_Status : 63|8@0+ (1,0) [0|255] ""  GW,BDC,ADS
 SG_ LAS_DTC2_LowByte : 55|8@0+ (1,0) [0|255] ""  GW,BDC,ADS
 SG_ LAS_DTC2_MiddByte : 47|8@0+ (1,0) [0|255] ""  GW,BDC,ADS
 SG_ LAS_DTC2_HighByte : 39|8@0+ (1,0) [0|255] ""  GW,BDC,ADS
 SG_ LAS_DTC1_Status : 31|8@0+ (1,0) [0|255] ""  GW,BDC,ADS
 SG_ LAS_DTC1_LowByte : 23|8@0+ (1,0) [0|255] ""  GW,BDC,ADS
 SG_ LAS_DTC1_MiddByte : 15|8@0+ (1,0) [0|255] ""  GW,BDC,ADS
 SG_ LAS_DTC1_HighByte : 7|8@0+ (1,0) [0|255] ""  GW,BDC,ADS

BO_ 999 GW_3E7: 8 GW
 SG_ BCM_Status_Temp : 51|2@0+ (1,0) [0|3] ""  GW,BDC,ADS,ACC,FR,LAS,LCDAL,LCDAR
 SG_ BCM_T_BATT : 39|8@0+ (1,-40) [-40|105] "C"  GW,BDC,ADS,ACC,FR,LAS,LCDAL,LCDAR

BO_ 1000 GW_3E8: 8 GW
 SG_ BCM_SOF_Q_STATE : 51|2@0+ (1,0) [0|3] ""  GW,BDC,ADS,ACC,FR,LAS,LCDAL,LCDAR
 SG_ BCM_SOF_Q : 15|8@0+ (0.5,0) [0|127] "Ah"  GW,BDC,ADS,ACC,FR,LAS,LCDAL,LCDAR

BO_ 790 FC_316: 64 FC
 SG_ LAS_RollingCounter_316 : 491|4@0+ (1,0) [0|15] ""  ADS
 SG_ LAS_CRCCheck_316 : 503|16@0+ (1,0) [0|65535] ""  ADS
 SG_ LAS_Line_03_MeasureType : 465|2@0+ (1,0) [0|2] ""  ADS
 SG_ LAS_Line_03_curvature_alteration : 371|12@0+ (3.8147E-006,-0.0078125) [-0.0078125|0.0078086965] "1/m2"  ADS
 SG_ LAS_Line_03__curve : 479|13@0+ (3.8147E-006,-0.015625) [-0.015625|0.0156212077] "1/m"  ADS
 SG_ LAS_Line_03_HeadingAngle : 351|13@0+ (0.000488281,-1.6) [-1.6|1.6] "rad"  ADS
 SG_ LAS_Line_03_dy : 462|12@0+ (0.015625,-32) [-32|31.984375] "m"  ADS
 SG_ LAS_Line_03_dx_End_std : 455|9@0+ (0.0078125,0) [0|3.992187] "m"  ADS
 SG_ LAS_Line_03__dx_End : 433|10@0+ (0.25,0) [0|255.75] "m"  ADS
 SG_ LAS_Line_03_dx_Start_std : 426|9@0+ (0.0078125,0) [0|3.9921875] "m"  ADS
 SG_ LAS_Line_03_dx_Start : 423|13@0+ (0.025,0) [0|204.775] "m"  ADS
 SG_ LAS_Line_03_Width : 415|8@0+ (0.01,0) [0|2.55] "m"  ADS
 SG_ LAS_Line_03_color : 402|3@0+ (1,0) [0|7] ""  ADS
 SG_ LAS_Line_03_Id : 399|8@0+ (1,0) [1|255] ""  ADS
 SG_ LAS_Line_03_TypeConfidence : 391|6@0+ (2,0) [0|100] "%"  ADS
 SG_ LAS_Line_03_Type : 407|5@0+ (1,0) [0|31] ""  ADS
 SG_ LAS_Line_02__exist_prob : 325|6@0+ (2,0) [0|100] "%"  ADS
 SG_ LAS_Line_02_MeasureType : 310|2@0+ (1,0) [0|2] ""  ADS
 SG_ LAS_Line_02_curvature_alteration : 307|12@0+ (3.8147E-006,-0.0078125) [-0.0078125|0.0078086965] "1/m2"  ADS
 SG_ LAS_Line_02__curve : 292|13@0+ (3.8147E-006,-0.015625) [-0.015625|0.0156212077] "1/m"  ADS
 SG_ LAS_Line_02_HeadingAngle : 335|13@0+ (0.000488281,-1.6) [-1.6|1.6] "rad"  ADS
 SG_ LAS_Line_02_dy : 270|12@0+ (0.015625,-32) [-32|31.984375] "m"  ADS
 SG_ LAS_Line_02_dx_End_std : 263|9@0+ (0.0078125,0) [0|3.992187] "m"  ADS
 SG_ LAS_Line_02__dx_End : 241|10@0+ (0.25,0) [0|255.75] "m"  ADS
 SG_ LAS_Line_02_dx_Start_std : 234|9@0+ (0.0078125,0) [0|3.9921875] "m"  ADS
 SG_ LAS_Line_02_dx_Start : 231|13@0+ (0.025,0) [0|204.775] "m"  ADS
 SG_ LAS_Line_02_Width : 223|8@0+ (0.01,0) [0|2.55] "m"  ADS
 SG_ LAS_Line_02_color : 210|3@0+ (1,0) [0|7] ""  ADS
 SG_ LAS_Line_02_Id : 207|8@0+ (1,0) [1|255] ""  ADS
 SG_ LAS_Line_02_TypeConfidence : 199|6@0+ (2,0) [0|100] "%"  ADS
 SG_ LAS_Line_02_Type : 215|5@0+ (1,0) [0|31] ""  ADS
 SG_ LAS_Line_01__exist_prob : 133|6@0+ (2,0) [0|100] "%"  ADS
 SG_ LAS_Line_01_MeasureType : 118|2@0+ (1,0) [0|2] ""  ADS
 SG_ LAS_Line_01_curvature_alteration : 115|12@0+ (3.8147E-006,-0.0078125) [-0.0078125|0.0078086965] "1/m2"  ADS
 SG_ LAS_Line_01__curve : 100|13@0+ (3.8147E-006,-0.015625) [-0.015625|0.0156212077] "1/m"  ADS
 SG_ LAS_Line_01_HeadingAngle : 143|13@0+ (0.000488281,-1.6) [-1.6|1.6] "rad"  ADS
 SG_ LAS_Line_01_dy : 78|12@0+ (0.015625,-32) [-32|31.984375] "m"  ADS
 SG_ LAS_Line_01_dx_End_std : 71|9@0+ (0.0078125,0) [0|3.992187] "m"  ADS
 SG_ LAS_Line_01__dx_End : 49|10@0+ (0.25,0) [0|255.75] "m"  ADS
 SG_ LAS_Line_01_dx_Start_std : 42|9@0+ (0.0078125,0) [0|3.9921875] "m"  ADS
 SG_ LAS_Line_01_dx_Start : 39|13@0+ (0.025,0) [0|204.775] "m"  ADS
 SG_ LAS_Line_01_Width : 31|8@0+ (0.01,0) [0|2.55] "m"  ADS
 SG_ LAS_Line_01_color : 18|3@0+ (1,0) [0|7] ""  ADS
 SG_ LAS_Line_01_Id : 15|8@0+ (1,0) [1|255] ""  ADS
 SG_ LAS_Line_01_TypeConfidence : 7|6@0+ (2,0) [0|100] "%"  ADS
 SG_ LAS_Line_01_Type : 23|5@0+ (1,0) [0|31] ""  ADS

BO_ 822 FC_336: 64 FC
 SG_ LAS_RollingCounter_336 : 491|4@0+ (1,0) [0|15] ""  ADS
 SG_ LAS_CRCCheck_336 : 503|16@0+ (1,0) [0|65535] ""  ADS
 SG_ LAS_Line_06__exist_prob : 333|6@0+ (2,0) [0|100] "%"  ADS
 SG_ LAS_Line_06_MeasureType : 465|2@0+ (1,0) [0|2] ""  ADS
 SG_ LAS_Line_06_curvature_alteration : 371|12@0+ (3.8147E-006,-0.0078125) [-0.0078125|0.0078086965] "1/m2"  ADS
 SG_ LAS_Line_06__curve : 479|13@0+ (3.8147E-006,-0.015625) [-0.015625|0.0156212077] "1/m"  ADS
 SG_ LAS_Line_06_HeadingAngle : 343|13@0+ (0.000488281,-1.6) [-1.6|1.6] "rad"  ADS
 SG_ LAS_Line_06_dy : 462|12@0+ (0.015625,-32) [-32|31.984375] "m"  ADS
 SG_ LAS_Line_06_dx_End_std : 455|9@0+ (0.0078125,0) [0|3.992187] "m"  ADS
 SG_ LAS_Line_06__dx_End : 433|10@0+ (0.25,0) [0|255.75] "m"  ADS
 SG_ LAS_Line_06_dx_Start_std : 426|9@0+ (0.0078125,0) [0|3.9921875] "m"  ADS
 SG_ LAS_Line_06_dx_Start : 423|13@0+ (0.025,0) [0|204.775] "m"  ADS
 SG_ LAS_Line_06_Width : 415|8@0+ (0.01,0) [0|2.55] "m"  ADS
 SG_ LAS_Line_06_color : 402|3@0+ (1,0) [0|7] ""  ADS
 SG_ LAS_Line_06_Id : 399|8@0+ (1,0) [1|255] ""  ADS
 SG_ LAS_Line_06_TypeConfidence : 391|6@0+ (2,0) [0|100] "%"  ADS
 SG_ LAS_Line_06_Type : 407|5@0+ (1,0) [0|31] ""  ADS
 SG_ LAS_Line_05__exist_prob : 325|6@0+ (2,0) [0|100] "%"  ADS
 SG_ LAS_Line_05_MeasureType : 310|2@0+ (1,0) [0|2] ""  ADS
 SG_ LAS_Line_05_curvature_alteration : 307|12@0+ (3.8147E-006,-0.0078125) [-0.0078125|0.0078086965] "1/m2"  ADS
 SG_ LAS_Line_05__curve : 292|13@0+ (3.8147E-006,-0.015625) [-0.015625|0.0156212077] "1/m"  ADS
 SG_ LAS_Line_05_HeadingAngle : 167|13@0+ (0.000488281,-1.6) [-1.6|1.6] "rad"  ADS
 SG_ LAS_Line_05_dy : 270|12@0+ (0.015625,-32) [-32|31.984375] "m"  ADS
 SG_ LAS_Line_05_dx_End_std : 263|9@0+ (0.0078125,0) [0|3.992187] "m"  ADS
 SG_ LAS_Line_05__dx_End : 241|10@0+ (0.25,0) [0|255.75] "m"  ADS
 SG_ LAS_Line_05_dx_Start_std : 234|9@0+ (0.0078125,0) [0|3.9921875] "m"  ADS
 SG_ LAS_Line_05_dx_Start : 231|13@0+ (0.025,0) [0|204.775] "m"  ADS
 SG_ LAS_Line_05_Width : 223|8@0+ (0.01,0) [0|2.55] "m"  ADS
 SG_ LAS_Line_05_color : 210|3@0+ (1,0) [0|7] ""  ADS
 SG_ LAS_Line_05_Id : 207|8@0+ (1,0) [1|255] ""  ADS
 SG_ LAS_Line_05_TypeConfidence : 199|6@0+ (2,0) [0|100] "%"  ADS
 SG_ LAS_Line_05_Type : 215|5@0+ (1,0) [0|31] ""  ADS
 SG_ LAS_Line_04__exist_prob : 133|6@0+ (2,0) [0|100] "%"  ADS
 SG_ LAS_Line_04_MeasureType : 118|2@0+ (1,0) [0|2] ""  ADS
 SG_ LAS_Line_04_curvature_alteration : 115|12@0+ (3.8147E-006,-0.0078125) [-0.0078125|0.0078086965] "1/m2"  ADS
 SG_ LAS_Line_04__curve : 100|13@0+ (3.8147E-006,-0.015625) [-0.015625|0.0156212077] "1/m"  ADS
 SG_ LAS_Line_04_HeadingAngle : 151|13@0+ (0.000488281,-1.6) [-1.6|1.6] "rad"  ADS
 SG_ LAS_Line_04_dy : 78|12@0+ (0.015625,-32) [-32|31.984375] "m"  ADS
 SG_ LAS_Line_04_dx_End_std : 71|9@0+ (0.0078125,0) [0|3.992187] "m"  ADS
 SG_ LAS_Line_04__dx_End : 49|10@0+ (0.25,0) [0|255.75] "m"  ADS
 SG_ LAS_Line_04_dx_Start_std : 42|9@0+ (0.0078125,0) [0|3.9921875] "m"  ADS
 SG_ LAS_Line_04_dx_Start : 39|13@0+ (0.025,0) [0|204.775] "m"  ADS
 SG_ LAS_Line_04_Width : 31|8@0+ (0.01,0) [0|2.55] "m"  ADS
 SG_ LAS_Line_04_color : 18|3@0+ (1,0) [0|7] ""  ADS
 SG_ LAS_Line_04_Id : 15|8@0+ (1,0) [1|255] ""  ADS
 SG_ LAS_Line_04_TypeConfidence : 7|6@0+ (2,0) [0|100] "%"  ADS
 SG_ LAS_Line_04_Type : 23|5@0+ (1,0) [0|31] ""  ADS
 SG_ LAS_Line_03__exist_prob : 141|6@0+ (2,0) [0|100] "%"  ADS

BO_ 962 GW_3C2: 8 GW
 SG_ HU_TollDis : 21|6@0+ (10,0) [0|600] "m"  GW,BDC,ADS,ACC,FR,LAS
 SG_ HU_TollInfo : 23|2@0+ (1,0) [0|3] ""  GW,BDC,ADS,ACC,FR,LAS

BO_ 1874 DIAG_Phy_Req: 64 Tester
 SG_ Phys_Diag_Rx : 7|64@0+ (1,0) [0|0] ""  LAS

BO_ 1882 DIAG_Response: 64 LAS
 SG_ Diag_Response : 7|64@0+ (1,0) [0|0] ""  Tester

BO_ 1891 DIAG_Phy_Req_CAN: 8 Tester
 SG_ Phys_Diag_Rx_CAN : 7|8@0+ (1,0) [0|0] ""  LAS

BO_ 1899 DIAG_Response_CAN: 8 LAS
 SG_ Diag_Response_CAN : 7|8@0+ (1,0) [0|0] ""  Tester

CM_ BO_ 3221225472 "This is a message for not used signals, created by Vector CANdb++ DBC OLE DB Provider.";
CM_ SG_ 3221225472 HU_CRCCheck_3C4 " ";
CM_ SG_ 3221225472 HU_RollingCounter_3C4 " ";
CM_ SG_ 3221225472 HU_RoadCurvature_40m " ";
CM_ SG_ 3221225472 HU_RoadCurvature_30m " ";
CM_ SG_ 3221225472 HU_RoadCurvature_20m " ";
CM_ SG_ 3221225472 HU_RoadCurvature_10m " ";
CM_ SG_ 3221225472 HU_Lane_Changtype " ";
CM_ SG_ 3221225472 HU_To_NumchangeOfLanes_Dist " ";
CM_ SG_ 3221225472 HU_CRCCheck_3C6 " ";
CM_ SG_ 3221225472 HU_RollingCounter_3C6 " ";
CM_ SG_ 3221225472 HU_RoadCurvature_90m " ";
CM_ SG_ 3221225472 HU_RoadCurvature_80m " ";
CM_ SG_ 3221225472 HU_RoadCurvature_70m " ";
CM_ SG_ 3221225472 HU_RoadCurvature_60m " ";
CM_ SG_ 3221225472 HU_RoadCurvature_50m " ";
CM_ SG_ 3221225472 HU_BranchInfo " ";
CM_ SG_ 3221225472 HU_CRCCheck_3C7 " ";
CM_ SG_ 3221225472 HU_RollingCounter_3C7 " ";
CM_ SG_ 3221225472 HU_MapMatchStatus " ";
CM_ SG_ 3221225472 HU_SlopeGradient_300m " ";
CM_ SG_ 3221225472 HU_RoadCurvature_600m " ";
CM_ SG_ 3221225472 HU_RoadCurvature_400m " ";
CM_ SG_ 3221225472 HU_RoadCurvature_300m " ";
CM_ SG_ 3221225472 HU_RoadCurvature_100m " ";
CM_ SG_ 3221225472 IMS_JawOffsetValue " ";
CM_ SG_ 3221225472 IMS_BrowOffsetValue " ";
CM_ SG_ 3221225472 IMS_HeadDetectSts_Yaw " ";
CM_ SG_ 3221225472 IMS_HeadDetectSts_Roll " ";
CM_ SG_ 3221225472 IMS_HeadDetectSts_Pitch " ";
CM_ SG_ 3221225472 IMS_PhoneCallSts " ";
CM_ SG_ 3221225472 IMS_IMSStatus " ";
CM_ SG_ 3221225472 IMS_EyeGazeStatus " ";
CM_ SG_ 3221225472 IMS_EyeDetectSatus "Below 10 is considered closed ";
CM_ SG_ 3221225472 IMS_DrowsinessStatus " ";
CM_ SG_ 3221225472 IMS_DriverHeadDetect " ";
CM_ SG_ 3221225472 IMS_DistractionStatus " ";
CM_ SG_ 3221225472 HU_CRCCheck_3C2 " ";
CM_ SG_ 3221225472 HU_RollingCounter_3C2 " ";
CM_ SG_ 3221225472 HU_MapDataUpdateStatus " ";
CM_ SG_ 3221225472 HU_Road_TrafficFlow " ";
CM_ SG_ 3221225472 HU_To_Branch_Dis " ";
CM_ SG_ 3221225472 HU_To_TrafficAccident_Dis " ";
CM_ SG_ 3221225472 HU_TrafficAccident_Info " ";
CM_ SG_ 3221225472 HU_To_Construction_Dis " ";
CM_ SG_ 3221225472 HU_Construction_Info " ";
CM_ SG_ 3221225472 HU_FallingRockDi " ";
CM_ SG_ 3221225472 HU_FallingRockInfo " ";
CM_ SG_ 3221225472 HU_LaneCnt " ";
CM_ SG_ 3221225472 HU_ForwardRoadType " ";
CM_ SG_ 3221225472 HU_RampSide " ";
CM_ BO_ 775 " ";
CM_ BO_ 801 " ";
CM_ BO_ 664 "The source end of L2 and above is EPSCAN, and the source end of L2 and below is PCAN ";
CM_ BO_ 2015 "DLC length is 8 to 64 CANFD message frame";
CM_ BO_ 652 "MFS_LIN_2 ";
CM_ BO_ 864 " ";
CM_ BO_ 854 " ";
CM_ BO_ 368 "The source end of L2 and above is EPSCAN, and the source end of L2 and below is PCAN ";
CM_ SG_ 368 EPS_CRCCheck_170 "10ms for platform, 8ms for CD569 special case ";
CM_ SG_ 368 EPS_RollingCounter_170 "10ms for platform, 8ms for CD569 special case ";
CM_ SG_ 368 EPS_ActualTorsionBarTorq "10ms for platform, 8ms for CD569 special case ";
CM_ SG_ 368 EPS_MinSafetyTorsionBarTorq "10ms for platform, 8ms for CD569 special case ";
CM_ SG_ 368 EPS_MaxSafetyTorsionBarTorq "10ms for platform, 8ms for CD569 special case ";
CM_ BO_ 916 " ";
CM_ SG_ 916 HU_ELKEnable " ";
CM_ SG_ 916 HU_TLAEnable " ";
CM_ BO_ 1300 " ";
CM_ SG_ 1300 HU_LDWShakeLev "513 (period) and 514 (event), most projects currently use 514 (event) message. ";
CM_ SG_ 1300 HU_LASWarningModeSelection "513 (period) and 514 (event), most projects currently use 514 (event) message. ";
CM_ SG_ 1300 HU_IACCEnable "513 (period) and 514 (event), most projects currently use 514 (event) message. ";
CM_ SG_ 1300 HU_HMAEnable "513 (period) and 514 (event), most projects currently use 514 (event) message. ";
CM_ SG_ 1300 HU_TSRSwitch "513 (period) and 514 (event), most projects currently use 514 (event) message. ";
CM_ SG_ 1300 HU_LASModeSelection "513 (period) and 514 (event), most projects currently use 514 (event) message. ";
CM_ SG_ 1300 HU_OverspeedWarningOffset "513 (period) and 514 (event), most projects currently use 514 (event) message. ";
CM_ SG_ 1300 HU_OverspeedWarningEnable "513 (period) and 514 (event), most projects currently use 514 (event) message. ";
CM_ SG_ 1300 HU_OverspeedSoundWarEnable "513 (period) and 514 (event), most projects currently use 514 (event) message. ";
CM_ BO_ 382 "The source end of L2 and above is EPSCAN, and the source end of L2 and below is PCAN";
CM_ SG_ 382 EPS_LatCtrlActive "Platform is 10ms, CD569 special case is 8ms";
CM_ SG_ 382 EPS_LatCtrlAvailabilityStatus "Platform is 10ms, CD569 special case is 8ms";
CM_ SG_ 382 EPS_CRCCheck_17E "Platform is 10ms, CD569 special case is 8ms";
CM_ SG_ 382 EPS_RollingCounter_17E "1.rolling counter 2.Platform is 10ms, CD569 special case is 8ms";
CM_ SG_ 382 EPS_MeasuredTorsionBarTorqValid "Platform is 10ms, CD569 special case is 8ms";
CM_ SG_ 382 EPS_MeasuredTorsionBarTorque "1. Formula: (Measured Torsion Bar Torque - 0x3FF)*0.01 2.Platform is 10ms, CD569 special case is 8ms";
CM_ BO_ 80 "Period when the collision output signal is triggered. Becomes 20ms, repeat 10 times";
CM_ SG_ 80 SRS_PassengerBuckleSwitchStatus "For PDM is configured projects:
(if PDM is configured, logical detection with PDM is required)
0x0: [Buckled] or [Unbuckled and passenger not occupied]
0x1: [Unbuckle and passenger occupied]
0x2: Not Used
0x3: Not Used
 ";
CM_ BO_ 391 " ";
CM_ SG_ 391 ESP_VehicleSpeed "TCU reception is dedicated to DCT ";
CM_ SG_ 391 ESP_VehicleSpeedValid "TCU reception is dedicated to DCT ";
CM_ SG_ 391 ESP_ESPActiveStatus "TCU reception is dedicated to DCT ";
CM_ SG_ 391 ESP_CRCCheck_187 "AT/DCT ";
CM_ SG_ 391 ESP_RollingCounter_187 "AT/DCT ";
CM_ BO_ 392 " ";
CM_ SG_ 392 TCU_ShiftinProgressValid "AT/DCT ";
CM_ SG_ 392 TCU_ShiftinProgress "AT/DCT ";
CM_ SG_ 392 TCU_CRCCheck_188 " ";
CM_ SG_ 392 TCU_RollingCounter_188 "AT/DCT
rollingcounter ";
CM_ BO_ 406 " ";
CM_ SG_ 406 EMS_CRCCheck_196 " ";
CM_ SG_ 406 EMS_BrakePedalStatus "Represents the true state of the driver depressing the brake pedal ";
CM_ BO_ 518 " ";
CM_ SG_ 518 ESP_CRCCheck_206 " ";
CM_ SG_ 518 ESP_RollingCounter_206 "rollingcounter ";
CM_ BO_ 520 " ";
CM_ SG_ 520 ESP_CRCCheck_208 " ";
CM_ SG_ 520 ESP_RollingCounter_208 "rollingcounter ";
CM_ BO_ 600 " ";
CM_ SG_ 600 ESP_MasCylBrakePressure "indicatedthepressureofbrakemastercylinder,butnotthepressureofbrake ";
CM_ SG_ 600 Wheel_Speed_FL_Pulse "All4wheelpulsesignalsaresentbyABSwithoutfiltering.Theriseedgeandfalledgearebothcountedinit,thewheelpulsemustbesequentialintheway0,1,2..254,0,4.. ";
CM_ SG_ 600 Wheel_Speed_FR_Pulse "All4wheelpulsesignalsaresentbyABSwithoutfiltering.Theriseedgeandfalledgearebothcountedinit,thewheelpulsemustbesequentialintheway0,1,2..254,0,3.. ";
CM_ SG_ 600 Wheel_Speed_RL_Pulse "All4wheelpulsesignalsaresentbyABSwithoutfiltering.Theriseedgeandfalledgearebothcountedinit,thewheelpulsemustbesequentialintheway0,1,2..254,0,2.. ";
CM_ SG_ 600 Wheel_Speed_RR_Pulse "All4wheelpulsesignalsaresentbyABSwithoutfiltering.Theriseedgeandfalledgearebothcountedinit,thewheelpulsemustbesequentialintheway0,1,2..254,0,1.. ";
CM_ SG_ 600 ESP_CRCCheck_258 " ";
CM_ BO_ 631 " ";
CM_ SG_ 631 ESP_CRCCheck_277 " ";
CM_ SG_ 631 ESP_RollingCounter_277 "rollingcounter ";
CM_ BO_ 632 " ";
CM_ SG_ 632 ESP_YawRate "Right positive left negative ";
CM_ SG_ 632 ESP_CRCCheck_278 " ";
CM_ SG_ 632 ESP_RollingCounter_278 "rollingcounter ";
CM_ SG_ 632 ESP_LongAccel "Right positive left negative ";
CM_ SG_ 632 ESP_LatAccel "Right positive left negative ";
CM_ BO_ 832 " ";
CM_ BO_ 870 " ";
CM_ BO_ 903 " ";
CM_ BO_ 912 " ";
CM_ SG_ 912 BCM_PMSLevel "Invalid value is DBC ";
CM_ BO_ 1280 " ";
CM_ BO_ 1281 " ";
CM_ BO_ 1328 " ";
CM_ SG_ 1328 IP_TotalOdometer "GW message forwarding ";
CM_ BO_ 422 " ";
CM_ SG_ 422 EMS_CRCCheck_1A6 " ";
CM_ BO_ 424 " ";
CM_ SG_ 424 TCU_ActualGear "AT/DCT ";
CM_ SG_ 424 TCU_ActualGearValid "AT/DCT ";
CM_ SG_ 424 TCU_GearShiftPosition "AT/DCT ";
CM_ SG_ 424 TCU_ShiftPostionValid "AT/DCT ";
CM_ SG_ 424 TCU_CRCCheck_1A8 " ";
CM_ SG_ 424 TCU_RollingCounter_1A8 "AT/DCT
rollingcounter ";
CM_ BO_ 591 "The source end of L2 and above is EPSCAN, and the source end of L2 and below is PCAN";
CM_ BO_ 651 " ";
CM_ BO_ 943 " ";
CM_ BO_ 952 " ";
CM_ BO_ 955 " ";
CM_ BO_ 1023 " ";
CM_ BO_ 583 " ";
CM_ BO_ 676 " ";
CM_ SG_ 676 LCDAR_CRCCheck_2AF " ";
CM_ SG_ 676 LCDAR_RollingCounter_2AF "rolling counter ";
CM_ SG_ 676 LCDAR_ELK_oAlert " ";
CM_ SG_ 676 LCDAR_ELK_oStatus " ";
CM_ SG_ 676 LCDAR_Left_ELK_oAlert " ";
CM_ BO_ 922 "The configuration of L2.9 and above is issued by ADS, and the configuration of L2.9 and below is issued by LAS";
CM_ SG_ 922 LAS_TLAObjectType_HostLane " ";
CM_ SG_ 922 LAS_TSRRightLaneStatus "GW message forwarding ";
CM_ SG_ 922 LAS_TSRLeftLaneStatus "GW message forwarding ";
CM_ SG_ 922 LAS_CRCCheck_3C0 "
 ";
CM_ SG_ 922 LAS_RollingCounter_3C0 "rolling counter ";
CM_ SG_ 922 LAS_TSRRightLaneSpdLimit "GW message forwarding
0x0=no speed limit detected;
0x1=SL5;
0x2=SL10;
..
0x32=SL160;
0x33~0x253= Reserved;
0x254=Unknown;
0x255=SLEND ";
CM_ SG_ 922 LAS_TSRLeftLaneSpdLimit "GW message forwarding
0x0=no speed limit detected;
0x1=SL5;
0x2=SL10;
..
0x32=SL160;
0x33~0x253= Reserved;
0x254=Unknown;
0x255=SLEND ";
CM_ SG_ 922 LAS_CRCCheck_3D4 "
 ";
CM_ SG_ 922 LAS_RollingCounter_3D4 "rolling counter ";
CM_ SG_ 922 LAS_TLAStopLine_HostLane " ";
CM_ SG_ 922 LAS_TLADistance_HostLane " ";
CM_ SG_ 922 LAS_TLACountDownTime_HostLane " ";
CM_ SG_ 922 LAS_TSRMandatorySign " ";
CM_ SG_ 922 LAS_TSRWarningSign " ";
CM_ SG_ 922 LAS_TSRProhibitionSign " ";
CM_ SG_ 922 LAS_CRCCheck_332 "
 ";
CM_ SG_ 922 LAS_RollingCounter_332 "rolling counter ";
CM_ SG_ 922 LAS_HMALightDistribution "GW message forwarding ";
CM_ SG_ 922 LAS_HMAStatus "GW message forwarding ";
CM_ SG_ 922 LAS_TSRHostSpdLimitUnits "GW message forwarding ";
CM_ SG_ 922 LAS_TSRStatus "GW message forwarding ";
CM_ SG_ 922 LAS_FrontCameraCalibrationStatus "When there is LAS, it is sent by LAS, and the rest is sent by APA or AVM.";
CM_ SG_ 922 LAS_FrontCameraFailureStatus "When there is LAS, it is sent by LAS, and the rest is sent by APA or AVM.";
CM_ SG_ 922 LAS_CRCCheck_37D " ";
CM_ SG_ 922 LAS_RollingCounter_37D "rolling counter ";
CM_ SG_ 922 LAS_TLAArrowDirection_RightLane " ";
CM_ SG_ 922 LAS_TLAObjectType_RightLane " ";
CM_ SG_ 922 LAS_TLAObjectStatus_RightLane " ";
CM_ SG_ 922 LAS_TLAObjectColour_RightLane " ";
CM_ SG_ 922 LAS_TLAObjectDetection_RightLane " ";
CM_ SG_ 922 LAS_TLAArrowDirection_LeftLane " ";
CM_ SG_ 922 LAS_TLAObjectType_LeftLane " ";
CM_ SG_ 922 LAS_TLAObjectStatus_LeftLane " ";
CM_ SG_ 922 LAS_TLAObjectColour_LeftLane " ";
CM_ SG_ 922 LAS_TLAObjectDetection_LeftLane " ";
CM_ SG_ 922 LAS_TLAArrowDirection_HostLane " ";
CM_ SG_ 922 LAS_TLAObjectStatus_HostLane " ";
CM_ SG_ 922 LAS_TLAObjectColour_HostLane " ";
CM_ SG_ 922 LAS_TLAObjectDetection_HostLane " ";
CM_ SG_ 922 LAS_TLAWarninglevel " ";
CM_ SG_ 922 LAS_TLAStatus " ";
CM_ SG_ 922 LAS_TLAEnable " ";
CM_ BO_ 1684 " ";
CM_ SG_ 1684 LAS_DTC2_Status "DTC upload ";
CM_ SG_ 1684 LAS_DTC2_LowByte "DTC upload ";
CM_ SG_ 1684 LAS_DTC2_MiddByte "DTC upload ";
CM_ SG_ 1684 LAS_DTC2_HighByte "DTC upload ";
CM_ SG_ 1684 LAS_DTC1_Status "DTC upload ";
CM_ SG_ 1684 LAS_DTC1_LowByte "DTC upload ";
CM_ SG_ 1684 LAS_DTC1_MiddByte "DTC upload ";
CM_ SG_ 1684 LAS_DTC1_HighByte "DTC upload ";
CM_ BO_ 999 " ";
CM_ SG_ 999 BCM_Status_Temp "GW message forwarding ";
CM_ SG_ 999 BCM_T_BATT "GW message forwarding ";
CM_ BO_ 1000 " ";
CM_ SG_ 1000 BCM_SOF_Q_STATE "GW message forwarding ";
CM_ SG_ 1000 BCM_SOF_Q "GW message forwarding ";
CM_ BO_ 790 " ";
CM_ SG_ 790 LAS_Line_03_curvature_alteration " ";
CM_ SG_ 790 LAS_Line_03__curve " ";
CM_ SG_ 790 LAS_Line_03_HeadingAngle " ";
CM_ SG_ 790 LAS_Line_03_dy " ";
CM_ SG_ 790 LAS_Line_03_dx_End_std " ";
CM_ SG_ 790 LAS_Line_03__dx_End " ";
CM_ SG_ 790 LAS_Line_03_dx_Start_std " ";
CM_ SG_ 790 LAS_Line_03_dx_Start " ";
CM_ SG_ 790 LAS_Line_03_Width " ";
CM_ SG_ 790 LAS_Line_03_color " ";
CM_ SG_ 790 LAS_Line_03_TypeConfidence " ";
CM_ SG_ 790 LAS_Line_03_Type " ";
CM_ SG_ 790 LAS_Line_02__exist_prob " ";
CM_ SG_ 790 LAS_Line_02_curvature_alteration " ";
CM_ SG_ 790 LAS_Line_02__curve " ";
CM_ SG_ 790 LAS_Line_02_HeadingAngle " ";
CM_ SG_ 790 LAS_Line_02_dy " ";
CM_ SG_ 790 LAS_Line_02_dx_End_std " ";
CM_ SG_ 790 LAS_Line_02__dx_End " ";
CM_ SG_ 790 LAS_Line_02_dx_Start_std " ";
CM_ SG_ 790 LAS_Line_02_dx_Start " ";
CM_ SG_ 790 LAS_Line_02_Width " ";
CM_ SG_ 790 LAS_Line_02_color " ";
CM_ SG_ 790 LAS_Line_02_TypeConfidence " ";
CM_ SG_ 790 LAS_Line_02_Type " ";
CM_ SG_ 790 LAS_Line_01__exist_prob " ";
CM_ SG_ 790 LAS_Line_01_curvature_alteration " ";
CM_ SG_ 790 LAS_Line_01__curve " ";
CM_ SG_ 790 LAS_Line_01_HeadingAngle " ";
CM_ SG_ 790 LAS_Line_01_dy " ";
CM_ SG_ 790 LAS_Line_01_dx_End_std " ";
CM_ SG_ 790 LAS_Line_01__dx_End " ";
CM_ SG_ 790 LAS_Line_01_dx_Start_std " ";
CM_ SG_ 790 LAS_Line_01_dx_Start " ";
CM_ SG_ 790 LAS_Line_01_Width " ";
CM_ SG_ 790 LAS_Line_01_color " ";
CM_ SG_ 790 LAS_Line_01_TypeConfidence " ";
CM_ SG_ 790 LAS_Line_01_Type " ";
CM_ BO_ 822 " ";
CM_ SG_ 822 LAS_Line_06__exist_prob " ";
CM_ SG_ 822 LAS_Line_06_curvature_alteration " ";
CM_ SG_ 822 LAS_Line_06__curve " ";
CM_ SG_ 822 LAS_Line_06_HeadingAngle " ";
CM_ SG_ 822 LAS_Line_06_dy " ";
CM_ SG_ 822 LAS_Line_06_dx_End_std " ";
CM_ SG_ 822 LAS_Line_06__dx_End " ";
CM_ SG_ 822 LAS_Line_06_dx_Start_std " ";
CM_ SG_ 822 LAS_Line_06_dx_Start " ";
CM_ SG_ 822 LAS_Line_06_Width " ";
CM_ SG_ 822 LAS_Line_06_color " ";
CM_ SG_ 822 LAS_Line_06_TypeConfidence " ";
CM_ SG_ 822 LAS_Line_06_Type " ";
CM_ SG_ 822 LAS_Line_05__exist_prob " ";
CM_ SG_ 822 LAS_Line_05_curvature_alteration " ";
CM_ SG_ 822 LAS_Line_05__curve " ";
CM_ SG_ 822 LAS_Line_05_HeadingAngle " ";
CM_ SG_ 822 LAS_Line_05_dy " ";
CM_ SG_ 822 LAS_Line_05_dx_End_std " ";
CM_ SG_ 822 LAS_Line_05__dx_End " ";
CM_ SG_ 822 LAS_Line_05_dx_Start_std " ";
CM_ SG_ 822 LAS_Line_05_dx_Start " ";
CM_ SG_ 822 LAS_Line_05_Width " ";
CM_ SG_ 822 LAS_Line_05_color " ";
CM_ SG_ 822 LAS_Line_05_TypeConfidence " ";
CM_ SG_ 822 LAS_Line_05_Type " ";
CM_ SG_ 822 LAS_Line_04__exist_prob " ";
CM_ SG_ 822 LAS_Line_04_curvature_alteration " ";
CM_ SG_ 822 LAS_Line_04__curve " ";
CM_ SG_ 822 LAS_Line_04_HeadingAngle " ";
CM_ SG_ 822 LAS_Line_04_dy " ";
CM_ SG_ 822 LAS_Line_04_dx_End_std " ";
CM_ SG_ 822 LAS_Line_04__dx_End " ";
CM_ SG_ 822 LAS_Line_04_dx_Start_std " ";
CM_ SG_ 822 LAS_Line_04_dx_Start " ";
CM_ SG_ 822 LAS_Line_04_Width " ";
CM_ SG_ 822 LAS_Line_04_color " ";
CM_ SG_ 822 LAS_Line_04_TypeConfidence " ";
CM_ SG_ 822 LAS_Line_04_Type " ";
CM_ SG_ 822 LAS_Line_03__exist_prob " ";
CM_ BO_ 962 " ";
CM_ SG_ 962 HU_TollDis " ";
CM_ SG_ 962 HU_TollInfo " ";
CM_ BO_ 1874 "DLC length is 8 to 64 CANFD message frame";
CM_ BO_ 1882 "DLC length is 8 to 64 CANFD message frame";
CM_ BO_ 1891 "CAN message frame ";
CM_ BO_ 1899 "CAN message frame ";
BA_DEF_ SG_  "GenSigStartValue" INT 0 0;
BA_DEF_ SG_  "GenSigInvalidValue" STRING ;
BA_DEF_ SG_  "GenSigCycleTime" INT 0 0;
BA_DEF_ SG_  "GenSigSendType" ENUM  "Cyclic","OnWrite","OnWriteWithRepetition","OnChange","OnChangeWithRepetition","IfActive","IfActiveWithRepetition","NoSigSendType","NotUsed","NotUsed","NotUsed","NotUsed","NotUsed";
BA_DEF_  "Baudrate" INT 0 1000000;
BA_DEF_  "NmType" STRING ;
BA_DEF_  "Manufacturer" STRING ;
BA_DEF_  "VersionYear" INT 2009 2210;
BA_DEF_  "VersionNumber" INT 0 65535;
BA_DEF_  "VersionMonth" INT 0 18;
BA_DEF_  "VersionDay" INT 0 49;
BA_DEF_ BU_  "NodeLayerModules" STRING ;
BA_DEF_ BU_  "ILUsed" ENUM  "No","Yes";
BA_DEF_  "GenNWMTalkNM" STRING ;
BA_DEF_  "GenNWMGotoMode_BusSleep" STRING ;
BA_DEF_  "GenNWMGotoMode_Awake" STRING ;
BA_DEF_  "GenNWMApCanWakeUp" STRING ;
BA_DEF_  "GenNWMApCanSleep" STRING ;
BA_DEF_  "GenNWMApCanOn" STRING ;
BA_DEF_  "GenNWMApCanOff" STRING ;
BA_DEF_  "GenNWMApCanNormal" STRING ;
BA_DEF_  "GenNWMApBusSleep" STRING ;
BA_DEF_ BO_  "GenMsgSendType" ENUM  "Cyclic","Event","NotUsed","NotUsed","NotUsed","Cyclic","NotUsed","IfActive","NoMsgSendType","NotUsed";
BA_DEF_ BO_  "GenMsgILSupport" ENUM  "No","Yes";
BA_DEF_ BO_  "GenMsgCycleTime" INT 0 65535;
BA_DEF_ BO_  "DiagState" ENUM  "No","Yes";
BA_DEF_ BO_  "DiagResponse" ENUM  "No","Yes";
BA_DEF_ BO_  "DiagRequest" ENUM  "No","Yes";
BA_DEF_ BO_  "CANFD_BRS" ENUM  "0","1";
BA_DEF_ BO_  "VFrameFormat" ENUM  "StandardCAN","ExtendedCAN","reserved","reserved","reserved","reserved","reserved","reserved","reserved","reserved","reserved","reserved","reserved","reserved","StandardCAN_FD","ExtendedCAN_FD";
BA_DEF_DEF_  "GenSigStartValue" 0;
BA_DEF_DEF_  "GenSigInvalidValue" "/";
BA_DEF_DEF_  "GenSigCycleTime" 0;
BA_DEF_DEF_  "GenSigSendType" "Cyclic";
BA_DEF_DEF_  "Baudrate" 500000;
BA_DEF_DEF_  "NmType" "";
BA_DEF_DEF_  "Manufacturer" "CHANA";
BA_DEF_DEF_  "VersionYear" 2010;
BA_DEF_DEF_  "VersionNumber" 0;
BA_DEF_DEF_  "VersionMonth" 11;
BA_DEF_DEF_  "VersionDay" 0;
BA_DEF_DEF_  "NodeLayerModules" "OSEKNM01.dll,CANoeILNLVector.dll";
BA_DEF_DEF_  "ILUsed" "Yes";
BA_DEF_DEF_  "GenNWMTalkNM" "TalkNM()";
BA_DEF_DEF_  "GenNWMGotoMode_BusSleep" "GotoMode_BusSleep()";
BA_DEF_DEF_  "GenNWMGotoMode_Awake" "GotoMode_Awake()";
BA_DEF_DEF_  "GenNWMApCanWakeUp" "apCanWakeUp()";
BA_DEF_DEF_  "GenNWMApCanSleep" "apCanSleep()";
BA_DEF_DEF_  "GenNWMApCanOn" "apCanOn()";
BA_DEF_DEF_  "GenNWMApCanOff" "apCanOff()";
BA_DEF_DEF_  "GenNWMApCanNormal" "apCanNormal()";
BA_DEF_DEF_  "GenNWMApBusSleep" "apBusSleep()";
BA_DEF_DEF_  "GenMsgSendType" "NoMsgSendType";
BA_DEF_DEF_  "GenMsgILSupport" "Yes";
BA_DEF_DEF_  "GenMsgCycleTime" 0;
BA_DEF_DEF_  "DiagState" "No";
BA_DEF_DEF_  "DiagResponse" "No";
BA_DEF_DEF_  "DiagRequest" "No";
BA_DEF_DEF_  "CANFD_BRS" "1";
BA_DEF_DEF_  "VFrameFormat" "StandardCAN";
BA_ "NmType" "OSEK";
BA_ "Baudrate" 2000000;
BA_ "VersionDay" 22;
BA_ "VersionMonth" 6;
BA_ "VersionNumber" 11;
BA_ "VersionYear" 2020;
BA_ "GenMsgSendType" BO_ 775 0;
BA_ "GenMsgCycleTime" BO_ 775 100;
BA_ "VFrameFormat" BO_ 775 14;
BA_ "GenMsgCycleTime" BO_ 801 100;
BA_ "GenMsgSendType" BO_ 801 0;
BA_ "VFrameFormat" BO_ 801 14;
BA_ "GenMsgSendType" BO_ 664 0;
BA_ "GenMsgCycleTime" BO_ 664 40;
BA_ "VFrameFormat" BO_ 664 14;
BA_ "DiagRequest" BO_ 2015 1;
BA_ "DiagState" BO_ 2015 1;
BA_ "GenMsgSendType" BO_ 652 0;
BA_ "GenMsgCycleTime" BO_ 652 40;
BA_ "VFrameFormat" BO_ 652 14;
BA_ "GenMsgSendType" BO_ 864 0;
BA_ "GenMsgCycleTime" BO_ 864 100;
BA_ "VFrameFormat" BO_ 864 14;
BA_ "GenMsgSendType" BO_ 854 0;
BA_ "GenMsgCycleTime" BO_ 854 100;
BA_ "VFrameFormat" BO_ 854 14;
BA_ "GenMsgSendType" BO_ 368 0;
BA_ "GenMsgCycleTime" BO_ 368 10;
BA_ "VFrameFormat" BO_ 368 14;
BA_ "GenMsgSendType" BO_ 916 0;
BA_ "GenMsgCycleTime" BO_ 916 100;
BA_ "VFrameFormat" BO_ 916 14;
BA_ "GenMsgSendType" BO_ 1300 1;
BA_ "VFrameFormat" BO_ 1300 14;
BA_ "GenMsgSendType" BO_ 382 0;
BA_ "GenMsgCycleTime" BO_ 382 10;
BA_ "VFrameFormat" BO_ 382 14;
BA_ "GenMsgSendType" BO_ 80 0;
BA_ "GenMsgCycleTime" BO_ 80 500;
BA_ "VFrameFormat" BO_ 80 14;
BA_ "GenMsgSendType" BO_ 384 0;
BA_ "GenMsgCycleTime" BO_ 384 10;
BA_ "VFrameFormat" BO_ 384 14;
BA_ "GenMsgSendType" BO_ 391 0;
BA_ "GenMsgCycleTime" BO_ 391 10;
BA_ "VFrameFormat" BO_ 391 14;
BA_ "GenMsgSendType" BO_ 392 0;
BA_ "GenMsgCycleTime" BO_ 392 10;
BA_ "VFrameFormat" BO_ 392 14;
BA_ "GenMsgSendType" BO_ 406 0;
BA_ "GenMsgCycleTime" BO_ 406 10;
BA_ "VFrameFormat" BO_ 406 14;
BA_ "GenMsgSendType" BO_ 518 0;
BA_ "GenMsgCycleTime" BO_ 518 20;
BA_ "VFrameFormat" BO_ 518 14;
BA_ "GenMsgSendType" BO_ 520 0;
BA_ "GenMsgCycleTime" BO_ 520 20;
BA_ "VFrameFormat" BO_ 520 14;
BA_ "GenMsgSendType" BO_ 600 0;
BA_ "GenMsgCycleTime" BO_ 600 20;
BA_ "VFrameFormat" BO_ 600 14;
BA_ "GenMsgSendType" BO_ 631 0;
BA_ "GenMsgCycleTime" BO_ 631 20;
BA_ "VFrameFormat" BO_ 631 14;
BA_ "GenMsgSendType" BO_ 632 0;
BA_ "GenMsgCycleTime" BO_ 632 20;
BA_ "VFrameFormat" BO_ 632 14;
BA_ "GenMsgSendType" BO_ 832 0;
BA_ "GenMsgCycleTime" BO_ 832 100;
BA_ "VFrameFormat" BO_ 832 14;
BA_ "GenMsgSendType" BO_ 870 0;
BA_ "GenMsgCycleTime" BO_ 870 100;
BA_ "VFrameFormat" BO_ 870 14;
BA_ "GenMsgSendType" BO_ 903 0;
BA_ "GenMsgCycleTime" BO_ 903 100;
BA_ "VFrameFormat" BO_ 903 14;
BA_ "GenMsgSendType" BO_ 912 0;
BA_ "GenMsgCycleTime" BO_ 912 500;
BA_ "VFrameFormat" BO_ 912 14;
BA_ "GenMsgSendType" BO_ 1280 0;
BA_ "GenMsgCycleTime" BO_ 1280 1000;
BA_ "VFrameFormat" BO_ 1280 14;
BA_ "GenMsgSendType" BO_ 1281 0;
BA_ "GenMsgCycleTime" BO_ 1281 1000;
BA_ "VFrameFormat" BO_ 1281 14;
BA_ "GenMsgSendType" BO_ 1328 0;
BA_ "GenMsgCycleTime" BO_ 1328 500;
BA_ "VFrameFormat" BO_ 1328 14;
BA_ "GenMsgSendType" BO_ 422 0;
BA_ "GenMsgCycleTime" BO_ 422 10;
BA_ "VFrameFormat" BO_ 422 14;
BA_ "GenMsgSendType" BO_ 424 0;
BA_ "GenMsgCycleTime" BO_ 424 10;
BA_ "VFrameFormat" BO_ 424 14;
BA_ "GenMsgSendType" BO_ 591 0;
BA_ "GenMsgCycleTime" BO_ 591 20;
BA_ "VFrameFormat" BO_ 591 14;
BA_ "GenMsgSendType" BO_ 651 0;
BA_ "GenMsgCycleTime" BO_ 651 40;
BA_ "VFrameFormat" BO_ 651 14;
BA_ "GenMsgSendType" BO_ 943 0;
BA_ "GenMsgCycleTime" BO_ 943 100;
BA_ "VFrameFormat" BO_ 943 14;
BA_ "GenMsgSendType" BO_ 952 0;
BA_ "GenMsgCycleTime" BO_ 952 100;
BA_ "VFrameFormat" BO_ 952 14;
BA_ "GenMsgSendType" BO_ 955 0;
BA_ "GenMsgCycleTime" BO_ 955 100;
BA_ "VFrameFormat" BO_ 955 14;
BA_ "GenMsgSendType" BO_ 1023 0;
BA_ "GenMsgCycleTime" BO_ 1023 100;
BA_ "VFrameFormat" BO_ 1023 14;
BA_ "GenMsgSendType" BO_ 583 0;
BA_ "GenMsgCycleTime" BO_ 583 20;
BA_ "VFrameFormat" BO_ 583 14;
BA_ "GenMsgSendType" BO_ 676 0;
BA_ "GenMsgCycleTime" BO_ 676 50;
BA_ "VFrameFormat" BO_ 676 14;
BA_ "GenMsgSendType" BO_ 922 0;
BA_ "GenMsgCycleTime" BO_ 922 100;
BA_ "VFrameFormat" BO_ 922 14;
BA_ "GenMsgSendType" BO_ 1684 0;
BA_ "GenMsgCycleTime" BO_ 1684 500;
BA_ "VFrameFormat" BO_ 1684 14;
BA_ "GenMsgSendType" BO_ 999 0;
BA_ "GenMsgCycleTime" BO_ 999 100;
BA_ "VFrameFormat" BO_ 999 14;
BA_ "GenMsgSendType" BO_ 1000 0;
BA_ "GenMsgCycleTime" BO_ 1000 100;
BA_ "VFrameFormat" BO_ 1000 14;
BA_ "GenMsgSendType" BO_ 790 0;
BA_ "GenMsgCycleTime" BO_ 790 100;
BA_ "VFrameFormat" BO_ 790 14;
BA_ "GenMsgSendType" BO_ 822 0;
BA_ "GenMsgCycleTime" BO_ 822 100;
BA_ "VFrameFormat" BO_ 822 14;
BA_ "GenMsgSendType" BO_ 962 0;
BA_ "GenMsgCycleTime" BO_ 962 100;
BA_ "VFrameFormat" BO_ 962 14;
BA_ "DiagRequest" BO_ 1874 1;
BA_ "DiagState" BO_ 1874 1;
BA_ "VFrameFormat" BO_ 1874 14;
BA_ "DiagResponse" BO_ 1882 1;
BA_ "DiagState" BO_ 1882 1;
BA_ "VFrameFormat" BO_ 1882 14;
BA_ "DiagRequest" BO_ 1891 1;
BA_ "DiagState" BO_ 1891 1;
BA_ "DiagResponse" BO_ 1899 1;
BA_ "DiagState" BO_ 1899 1;
BA_ "VFrameFormat" BO_ 1899 14;
BA_ "GenSigCycleTime" SG_ 3221225472 HU_CRCCheck_3C4 100;
BA_ "GenSigCycleTime" SG_ 3221225472 HU_RollingCounter_3C4 100;
BA_ "GenSigInvalidValue" SG_ 3221225472 HU_RoadCurvature_40m "1023";
BA_ "GenSigStartValue" SG_ 3221225472 HU_RoadCurvature_40m 511;
BA_ "GenSigCycleTime" SG_ 3221225472 HU_RoadCurvature_40m 100;
BA_ "GenSigInvalidValue" SG_ 3221225472 HU_RoadCurvature_30m "1023";
BA_ "GenSigStartValue" SG_ 3221225472 HU_RoadCurvature_30m 511;
BA_ "GenSigCycleTime" SG_ 3221225472 HU_RoadCurvature_30m 100;
BA_ "GenSigInvalidValue" SG_ 3221225472 HU_RoadCurvature_20m "1023";
BA_ "GenSigStartValue" SG_ 3221225472 HU_RoadCurvature_20m 511;
BA_ "GenSigCycleTime" SG_ 3221225472 HU_RoadCurvature_20m 100;
BA_ "GenSigInvalidValue" SG_ 3221225472 HU_RoadCurvature_10m "1023";
BA_ "GenSigStartValue" SG_ 3221225472 HU_RoadCurvature_10m 511;
BA_ "GenSigCycleTime" SG_ 3221225472 HU_RoadCurvature_10m 100;
BA_ "GenSigInvalidValue" SG_ 3221225472 HU_Lane_Changtype "3";
BA_ "GenSigStartValue" SG_ 3221225472 HU_Lane_Changtype 3;
BA_ "GenSigCycleTime" SG_ 3221225472 HU_Lane_Changtype 100;
BA_ "GenSigInvalidValue" SG_ 3221225472 HU_To_NumchangeOfLanes_Dist "63";
BA_ "GenSigStartValue" SG_ 3221225472 HU_To_NumchangeOfLanes_Dist 63;
BA_ "GenSigCycleTime" SG_ 3221225472 HU_To_NumchangeOfLanes_Dist 100;
BA_ "GenSigCycleTime" SG_ 3221225472 HU_CRCCheck_3C6 100;
BA_ "GenSigCycleTime" SG_ 3221225472 HU_RollingCounter_3C6 100;
BA_ "GenSigInvalidValue" SG_ 3221225472 HU_RoadCurvature_90m "1023";
BA_ "GenSigStartValue" SG_ 3221225472 HU_RoadCurvature_90m 511;
BA_ "GenSigCycleTime" SG_ 3221225472 HU_RoadCurvature_90m 100;
BA_ "GenSigInvalidValue" SG_ 3221225472 HU_RoadCurvature_80m "1023";
BA_ "GenSigStartValue" SG_ 3221225472 HU_RoadCurvature_80m 511;
BA_ "GenSigCycleTime" SG_ 3221225472 HU_RoadCurvature_80m 100;
BA_ "GenSigInvalidValue" SG_ 3221225472 HU_RoadCurvature_70m "1023";
BA_ "GenSigStartValue" SG_ 3221225472 HU_RoadCurvature_70m 511;
BA_ "GenSigCycleTime" SG_ 3221225472 HU_RoadCurvature_70m 100;
BA_ "GenSigInvalidValue" SG_ 3221225472 HU_RoadCurvature_60m "1023";
BA_ "GenSigStartValue" SG_ 3221225472 HU_RoadCurvature_60m 511;
BA_ "GenSigCycleTime" SG_ 3221225472 HU_RoadCurvature_60m 100;
BA_ "GenSigInvalidValue" SG_ 3221225472 HU_RoadCurvature_50m "1023";
BA_ "GenSigStartValue" SG_ 3221225472 HU_RoadCurvature_50m 511;
BA_ "GenSigCycleTime" SG_ 3221225472 HU_RoadCurvature_50m 100;
BA_ "GenSigInvalidValue" SG_ 3221225472 HU_BranchInfo "0";
BA_ "GenSigCycleTime" SG_ 3221225472 HU_BranchInfo 100;
BA_ "GenSigStartValue" SG_ 3221225472 GW_MFS_HODCalibratedStatus 1;
BA_ "GenSigCycleTime" SG_ 3221225472 GW_MFS_HODCalibratedStatus 40;
BA_ "GenSigCycleTime" SG_ 3221225472 GW_MFS_HODLinStatus 40;
BA_ "GenSigCycleTime" SG_ 3221225472 GW_MFS_HODAppStatus 40;
BA_ "GenSigCycleTime" SG_ 3221225472 GW_MFS_HODSenserStatus 40;
BA_ "GenSigCycleTime" SG_ 3221225472 GW_MFS_HODSystemStatus 40;
BA_ "GenSigCycleTime" SG_ 3221225472 GW_MFS_handsoffAbilityDetect 40;
BA_ "GenSigCycleTime" SG_ 3221225472 GW_MFS_handsoffDetectResult 40;
BA_ "GenSigCycleTime" SG_ 3221225472 GW_MFS_RollingCounter_28C 40;
BA_ "GenSigInvalidValue" SG_ 3221225472 GW_MFS_DiagInfoSW_28C "7";
BA_ "GenSigCycleTime" SG_ 3221225472 GW_MFS_DiagInfoSW_28C 40;
BA_ "GenSigCycleTime" SG_ 3221225472 HU_CRCCheck_3C7 100;
BA_ "GenSigCycleTime" SG_ 3221225472 HU_RollingCounter_3C7 100;
BA_ "GenSigInvalidValue" SG_ 3221225472 HU_MapMatchStatus "3";
BA_ "GenSigCycleTime" SG_ 3221225472 HU_MapMatchStatus 100;
BA_ "GenSigInvalidValue" SG_ 3221225472 HU_SlopeGradient_300m "1023";
BA_ "GenSigStartValue" SG_ 3221225472 HU_SlopeGradient_300m 1023;
BA_ "GenSigCycleTime" SG_ 3221225472 HU_SlopeGradient_300m 100;
BA_ "GenSigInvalidValue" SG_ 3221225472 HU_RoadCurvature_600m "1023";
BA_ "GenSigStartValue" SG_ 3221225472 HU_RoadCurvature_600m 511;
BA_ "GenSigCycleTime" SG_ 3221225472 HU_RoadCurvature_600m 100;
BA_ "GenSigInvalidValue" SG_ 3221225472 HU_RoadCurvature_400m "1023";
BA_ "GenSigStartValue" SG_ 3221225472 HU_RoadCurvature_400m 511;
BA_ "GenSigCycleTime" SG_ 3221225472 HU_RoadCurvature_400m 100;
BA_ "GenSigInvalidValue" SG_ 3221225472 HU_RoadCurvature_300m "1023";
BA_ "GenSigStartValue" SG_ 3221225472 HU_RoadCurvature_300m 511;
BA_ "GenSigCycleTime" SG_ 3221225472 HU_RoadCurvature_300m 100;
BA_ "GenSigInvalidValue" SG_ 3221225472 HU_RoadCurvature_100m "1023";
BA_ "GenSigStartValue" SG_ 3221225472 HU_RoadCurvature_100m 511;
BA_ "GenSigCycleTime" SG_ 3221225472 HU_RoadCurvature_100m 100;
BA_ "GenSigCycleTime" SG_ 3221225472 IMS_JawOffsetValue 100;
BA_ "GenSigCycleTime" SG_ 3221225472 IMS_BrowOffsetValue 100;
BA_ "GenSigCycleTime" SG_ 3221225472 IMS_RollingCounter_360 100;
BA_ "GenSigCycleTime" SG_ 3221225472 IMS_CRCCheck_360 100;
BA_ "GenSigInvalidValue" SG_ 3221225472 IMS_HeadDetectSts_Yaw "255";
BA_ "GenSigStartValue" SG_ 3221225472 IMS_HeadDetectSts_Yaw 255;
BA_ "GenSigCycleTime" SG_ 3221225472 IMS_HeadDetectSts_Yaw 100;
BA_ "GenSigInvalidValue" SG_ 3221225472 IMS_HeadDetectSts_Roll "255";
BA_ "GenSigStartValue" SG_ 3221225472 IMS_HeadDetectSts_Roll 255;
BA_ "GenSigCycleTime" SG_ 3221225472 IMS_HeadDetectSts_Roll 100;
BA_ "GenSigInvalidValue" SG_ 3221225472 IMS_HeadDetectSts_Pitch "255";
BA_ "GenSigStartValue" SG_ 3221225472 IMS_HeadDetectSts_Pitch 255;
BA_ "GenSigCycleTime" SG_ 3221225472 IMS_HeadDetectSts_Pitch 100;
BA_ "GenSigCycleTime" SG_ 3221225472 IMS_PhoneCallSts 100;
BA_ "GenSigInvalidValue" SG_ 3221225472 IMS_DriverEyesFovArea "15";
BA_ "GenSigCycleTime" SG_ 3221225472 IMS_DriverEyesFovArea 100;
BA_ "GenSigInvalidValue" SG_ 3221225472 IMS_DriverEyeClosestatus "7";
BA_ "GenSigStartValue" SG_ 3221225472 IMS_DriverEyeClosestatus 7;
BA_ "GenSigCycleTime" SG_ 3221225472 IMS_DriverEyeClosestatus 100;
BA_ "GenSigInvalidValue" SG_ 3221225472 IMS_DriverEyeConfidence "0";
BA_ "GenSigCycleTime" SG_ 3221225472 IMS_DriverEyeConfidence 100;
BA_ "GenSigInvalidValue" SG_ 3221225472 IMS_DriverEyeDetect "0";
BA_ "GenSigCycleTime" SG_ 3221225472 IMS_DriverEyeDetect 100;
BA_ "GenSigCycleTime" SG_ 3221225472 IMS_RollingCounter_356 100;
BA_ "GenSigCycleTime" SG_ 3221225472 IMS_CRCCheck_356 100;
BA_ "GenSigInvalidValue" SG_ 3221225472 IMS_IMSStatus "7";
BA_ "GenSigStartValue" SG_ 3221225472 IMS_IMSStatus 1;
BA_ "GenSigCycleTime" SG_ 3221225472 IMS_IMSStatus 100;
BA_ "GenSigInvalidValue" SG_ 3221225472 IMS_EyeGazeStatus "255";
BA_ "GenSigStartValue" SG_ 3221225472 IMS_EyeGazeStatus 255;
BA_ "GenSigCycleTime" SG_ 3221225472 IMS_EyeGazeStatus 100;
BA_ "GenSigInvalidValue" SG_ 3221225472 IMS_EyeDetectSatus "255";
BA_ "GenSigStartValue" SG_ 3221225472 IMS_EyeDetectSatus 255;
BA_ "GenSigCycleTime" SG_ 3221225472 IMS_EyeDetectSatus 100;
BA_ "GenSigInvalidValue" SG_ 3221225472 IMS_DrowsinessStatus "7";
BA_ "GenSigCycleTime" SG_ 3221225472 IMS_DrowsinessStatus 100;
BA_ "GenSigInvalidValue" SG_ 3221225472 IMS_DriverHeadDetect "0";
BA_ "GenSigCycleTime" SG_ 3221225472 IMS_DriverHeadDetect 100;
BA_ "GenSigInvalidValue" SG_ 3221225472 IMS_DistractionStatus "3";
BA_ "GenSigCycleTime" SG_ 3221225472 IMS_DistractionStatus 100;
BA_ "GenSigInvalidValue" SG_ 3221225472 HU_NavSpeedLimitType "0";
BA_ "GenSigCycleTime" SG_ 3221225472 HU_NavSpeedLimitType 100;
BA_ "GenSigInvalidValue" SG_ 3221225472 HU_CurveDistance "63";
BA_ "GenSigStartValue" SG_ 3221225472 HU_CurveDistance 63;
BA_ "GenSigCycleTime" SG_ 3221225472 HU_CurveDistance 100;
BA_ "GenSigInvalidValue" SG_ 3221225472 HU_EnterCurveInfo "0";
BA_ "GenSigCycleTime" SG_ 3221225472 HU_EnterCurveInfo 100;
BA_ "GenSigInvalidValue" SG_ 3221225472 HU_EnterRampInfo "0";
BA_ "GenSigCycleTime" SG_ 3221225472 HU_EnterRampInfo 100;
BA_ "GenSigInvalidValue" SG_ 3221225472 HU_NavCountryCode "0";
BA_ "GenSigCycleTime" SG_ 3221225472 HU_NavCountryCode 100;
BA_ "GenSigInvalidValue" SG_ 3221225472 HU_NavSpeedLimitUnits "0";
BA_ "GenSigCycleTime" SG_ 3221225472 HU_NavSpeedLimitUnits 100;
BA_ "GenSigInvalidValue" SG_ 3221225472 HU_SlopeDistance "63";
BA_ "GenSigStartValue" SG_ 3221225472 HU_SlopeDistance 63;
BA_ "GenSigCycleTime" SG_ 3221225472 HU_SlopeDistance 100;
BA_ "GenSigInvalidValue" SG_ 3221225472 HU_Byroad "3";
BA_ "GenSigCycleTime" SG_ 3221225472 HU_Byroad 100;
BA_ "GenSigInvalidValue" SG_ 3221225472 HU_RoadCurvatureFar "1023";
BA_ "GenSigStartValue" SG_ 3221225472 HU_RoadCurvatureFar 511;
BA_ "GenSigCycleTime" SG_ 3221225472 HU_RoadCurvatureFar 100;
BA_ "GenSigInvalidValue" SG_ 3221225472 HU_RoadCurvature "1023";
BA_ "GenSigStartValue" SG_ 3221225472 HU_RoadCurvature 511;
BA_ "GenSigCycleTime" SG_ 3221225472 HU_RoadCurvature 100;
BA_ "GenSigInvalidValue" SG_ 3221225472 HU_EnterSlopeInfo "0";
BA_ "GenSigCycleTime" SG_ 3221225472 HU_EnterSlopeInfo 100;
BA_ "GenSigInvalidValue" SG_ 3221225472 HU_SpeedLimitDistance "63";
BA_ "GenSigStartValue" SG_ 3221225472 HU_SpeedLimitDistance 63;
BA_ "GenSigCycleTime" SG_ 3221225472 HU_SpeedLimitDistance 100;
BA_ "GenSigCycleTime" SG_ 3221225472 HU_CRCCheck_3C2 100;
BA_ "GenSigCycleTime" SG_ 3221225472 HU_RollingCounter_3C2 100;
BA_ "GenSigInvalidValue" SG_ 3221225472 HU_MapDataUpdateStatus "7";
BA_ "GenSigCycleTime" SG_ 3221225472 HU_MapDataUpdateStatus 100;
BA_ "GenSigInvalidValue" SG_ 3221225472 HU_Road_TrafficFlow "7";
BA_ "GenSigCycleTime" SG_ 3221225472 HU_Road_TrafficFlow 100;
BA_ "GenSigInvalidValue" SG_ 3221225472 HU_To_Branch_Dis "63";
BA_ "GenSigStartValue" SG_ 3221225472 HU_To_Branch_Dis 63;
BA_ "GenSigCycleTime" SG_ 3221225472 HU_To_Branch_Dis 100;
BA_ "GenSigInvalidValue" SG_ 3221225472 HU_To_TrafficAccident_Dis "63";
BA_ "GenSigStartValue" SG_ 3221225472 HU_To_TrafficAccident_Dis 63;
BA_ "GenSigCycleTime" SG_ 3221225472 HU_To_TrafficAccident_Dis 100;
BA_ "GenSigInvalidValue" SG_ 3221225472 HU_TrafficAccident_Info "3";
BA_ "GenSigStartValue" SG_ 3221225472 HU_TrafficAccident_Info 3;
BA_ "GenSigCycleTime" SG_ 3221225472 HU_TrafficAccident_Info 100;
BA_ "GenSigInvalidValue" SG_ 3221225472 HU_To_Construction_Dis "63";
BA_ "GenSigStartValue" SG_ 3221225472 HU_To_Construction_Dis 63;
BA_ "GenSigCycleTime" SG_ 3221225472 HU_To_Construction_Dis 100;
BA_ "GenSigInvalidValue" SG_ 3221225472 HU_Construction_Info "3";
BA_ "GenSigStartValue" SG_ 3221225472 HU_Construction_Info 3;
BA_ "GenSigCycleTime" SG_ 3221225472 HU_Construction_Info 100;
BA_ "GenSigInvalidValue" SG_ 3221225472 HU_FallingRockDi "63";
BA_ "GenSigStartValue" SG_ 3221225472 HU_FallingRockDi 63;
BA_ "GenSigCycleTime" SG_ 3221225472 HU_FallingRockDi 100;
BA_ "GenSigInvalidValue" SG_ 3221225472 HU_FallingRockInfo "3";
BA_ "GenSigStartValue" SG_ 3221225472 HU_FallingRockInfo 3;
BA_ "GenSigCycleTime" SG_ 3221225472 HU_FallingRockInfo 100;
BA_ "GenSigInvalidValue" SG_ 3221225472 HU_LaneCnt "0";
BA_ "GenSigCycleTime" SG_ 3221225472 HU_LaneCnt 100;
BA_ "GenSigInvalidValue" SG_ 3221225472 HU_ForwardRoadType "0";
BA_ "GenSigCycleTime" SG_ 3221225472 HU_ForwardRoadType 100;
BA_ "GenSigInvalidValue" SG_ 3221225472 HU_RampSide "0";
BA_ "GenSigCycleTime" SG_ 3221225472 HU_RampSide 100;
BA_ "GenSigStartValue" SG_ 664 BCM_DriverDoorLockStatus 3;
BA_ "GenSigSendType" SG_ 2015 Functional_Diag_Rx 7;
BA_ "GenSigInvalidValue" SG_ 652 GW_FIS_IACCenable_switch_signal "3";
BA_ "GenSigCycleTime" SG_ 652 GW_FIS_IACCenable_switch_signal 40;
BA_ "GenSigCycleTime" SG_ 368 EPS_CRCCheck_170 10;
BA_ "GenSigCycleTime" SG_ 368 EPS_RollingCounter_170 10;
BA_ "GenSigInvalidValue" SG_ 368 EPS_ActualTorsionBarTorq "2047";
BA_ "GenSigStartValue" SG_ 368 EPS_ActualTorsionBarTorq 1024;
BA_ "GenSigCycleTime" SG_ 368 EPS_ActualTorsionBarTorq 10;
BA_ "GenSigInvalidValue" SG_ 368 EPS_MinSafetyTorsionBarTorq "2047";
BA_ "GenSigStartValue" SG_ 368 EPS_MinSafetyTorsionBarTorq 1024;
BA_ "GenSigCycleTime" SG_ 368 EPS_MinSafetyTorsionBarTorq 10;
BA_ "GenSigInvalidValue" SG_ 368 EPS_MaxSafetyTorsionBarTorq "2047";
BA_ "GenSigStartValue" SG_ 368 EPS_MaxSafetyTorsionBarTorq 1024;
BA_ "GenSigCycleTime" SG_ 368 EPS_MaxSafetyTorsionBarTorq 10;
BA_ "GenSigInvalidValue" SG_ 916 HU_ELKEnable "0";
BA_ "GenSigCycleTime" SG_ 916 HU_ELKEnable 100;
BA_ "GenSigInvalidValue" SG_ 916 HU_TLAEnable "0";
BA_ "GenSigCycleTime" SG_ 916 HU_TLAEnable 100;
BA_ "GenSigStartValue" SG_ 1300 HU_OverspeedWarningEnable 1;
BA_ "GenSigStartValue" SG_ 1300 HU_OverspeedSoundWarEnable 1;
BA_ "GenSigInvalidValue" SG_ 382 EPS_LatCtrlActive "0";
BA_ "GenSigCycleTime" SG_ 382 EPS_LatCtrlActive 10;
BA_ "GenSigInvalidValue" SG_ 382 EPS_LatCtrlAvailabilityStatus "2";
BA_ "GenSigCycleTime" SG_ 382 EPS_LatCtrlAvailabilityStatus 10;
BA_ "GenSigCycleTime" SG_ 382 EPS_CRCCheck_17E 10;
BA_ "GenSigCycleTime" SG_ 382 EPS_RollingCounter_17E 10;
BA_ "GenSigInvalidValue" SG_ 382 EPS_MeasuredTorsionBarTorqValid "1";
BA_ "GenSigCycleTime" SG_ 382 EPS_MeasuredTorsionBarTorqValid 10;
BA_ "GenSigInvalidValue" SG_ 382 EPS_MeasuredTorsionBarTorque "2047";
BA_ "GenSigCycleTime" SG_ 382 EPS_MeasuredTorsionBarTorque 10;
BA_ "GenSigCycleTime" SG_ 80 SRS_PassengerBuckleSwitchStatus 500;
BA_ "GenSigCycleTime" SG_ 80 SRS_WarningLampStatus 500;
BA_ "GenSigCycleTime" SG_ 80 SRS_DriverBuckleSwitchStatus 500;
BA_ "GenSigCycleTime" SG_ 80 SRS_RollingCounter_id050 500;
BA_ "GenSigCycleTime" SG_ 80 SRS_CrashOutputStatusCheckSum 500;
BA_ "GenSigCycleTime" SG_ 80 SRS_CrashOutputStatus 500;
BA_ "GenSigCycleTime" SG_ 384 SAS_CRCCheck 10;
BA_ "GenSigCycleTime" SG_ 384 SAS_RollingCounter 10;
BA_ "GenSigInvalidValue" SG_ 384 SAS_SteeringAngleSpeed "255";
BA_ "GenSigCycleTime" SG_ 384 SAS_SteeringAngleSpeed 10;
BA_ "GenSigInvalidValue" SG_ 384 SAS_SteeringAngle "32767";
BA_ "GenSigStartValue" SG_ 384 SAS_SteeringAngle 32767;
BA_ "GenSigCycleTime" SG_ 384 SAS_SteeringAngle 10;
BA_ "GenSigInvalidValue" SG_ 384 SAS_SASFailure "1";
BA_ "GenSigCycleTime" SG_ 384 SAS_SASFailure 10;
BA_ "GenSigCycleTime" SG_ 384 SAS_Calibrated 10;
BA_ "GenSigInvalidValue" SG_ 384 SAS_SteeringAngleValid "1";
BA_ "GenSigCycleTime" SG_ 384 SAS_SteeringAngleValid 10;
BA_ "GenSigCycleTime" SG_ 391 ESP_ABSFailStatus 10;
BA_ "GenSigStartValue" SG_ 391 ESP_ESPFunctionStatus 1;
BA_ "GenSigCycleTime" SG_ 391 ESP_ESPFunctionStatus 10;
BA_ "GenSigCycleTime" SG_ 391 ESP_TCSFailStatus 10;
BA_ "GenSigInvalidValue" SG_ 391 ESP_VehicleSpeed "8191";
BA_ "GenSigCycleTime" SG_ 391 ESP_VehicleSpeed 10;
BA_ "GenSigInvalidValue" SG_ 391 ESP_VehicleSpeedValid "1";
BA_ "GenSigCycleTime" SG_ 391 ESP_VehicleSpeedValid 10;
BA_ "GenSigCycleTime" SG_ 391 ESP_ESPActiveStatus 10;
BA_ "GenSigCycleTime" SG_ 391 ESP_CRCCheck_187 10;
BA_ "GenSigCycleTime" SG_ 391 ESP_RollingCounter_187 10;
BA_ "GenSigInvalidValue" SG_ 392 TCU_ShiftinProgressValid "1";
BA_ "GenSigCycleTime" SG_ 392 TCU_ShiftinProgressValid 10;
BA_ "GenSigCycleTime" SG_ 392 TCU_ShiftinProgress 10;
BA_ "GenSigCycleTime" SG_ 392 TCU_CRCCheck_188 10;
BA_ "GenSigCycleTime" SG_ 392 TCU_RollingCounter_188 10;
BA_ "GenSigCycleTime" SG_ 406 EMS_RollingCounter_196 10;
BA_ "GenSigCycleTime" SG_ 406 EMS_CRCCheck_196 10;
BA_ "GenSigInvalidValue" SG_ 406 EMS_BrakePedalStatus "3";
BA_ "GenSigCycleTime" SG_ 406 EMS_BrakePedalStatus 10;
BA_ "GenSigInvalidValue" SG_ 406 EMS_RealAccPedal "255";
BA_ "GenSigCycleTime" SG_ 406 EMS_RealAccPedal 10;
BA_ "GenSigInvalidValue" SG_ 406 EMS_AccPedal "255";
BA_ "GenSigCycleTime" SG_ 406 EMS_AccPedal 10;
BA_ "GenSigInvalidValue" SG_ 406 EMS_EngineSpeed "65535";
BA_ "GenSigCycleTime" SG_ 406 EMS_EngineSpeed 10;
BA_ "GenSigInvalidValue" SG_ 518 Wheel_Speed_FL_Data "8191";
BA_ "GenSigCycleTime" SG_ 518 Wheel_Speed_FL_Data 20;
BA_ "GenSigInvalidValue" SG_ 518 Wheel_Speed_FR_Data "8191";
BA_ "GenSigCycleTime" SG_ 518 Wheel_Speed_FR_Data 20;
BA_ "GenSigInvalidValue" SG_ 518 Wheel_Speed_FL_Valid_Data "1";
BA_ "GenSigCycleTime" SG_ 518 Wheel_Speed_FL_Valid_Data 20;
BA_ "GenSigInvalidValue" SG_ 518 Wheel_Speed_FR_Valid_Data "1";
BA_ "GenSigCycleTime" SG_ 518 Wheel_Speed_FR_Valid_Data 20;
BA_ "GenSigInvalidValue" SG_ 518 Wheel_Speed_FL_Direction "3";
BA_ "GenSigCycleTime" SG_ 518 Wheel_Speed_FL_Direction 20;
BA_ "GenSigInvalidValue" SG_ 518 Wheel_Speed_FR_Direction "3";
BA_ "GenSigCycleTime" SG_ 518 Wheel_Speed_FR_Direction 20;
BA_ "GenSigCycleTime" SG_ 518 ESP_CRCCheck_206 20;
BA_ "GenSigCycleTime" SG_ 518 ESP_RollingCounter_206 20;
BA_ "GenSigInvalidValue" SG_ 520 Wheel_Speed_RL_Data "8191";
BA_ "GenSigCycleTime" SG_ 520 Wheel_Speed_RL_Data 20;
BA_ "GenSigInvalidValue" SG_ 520 Wheel_Speed_RR_Data "8191";
BA_ "GenSigCycleTime" SG_ 520 Wheel_Speed_RR_Data 20;
BA_ "GenSigInvalidValue" SG_ 520 Wheel_Speed_RL_Valid_Data "1";
BA_ "GenSigCycleTime" SG_ 520 Wheel_Speed_RL_Valid_Data 20;
BA_ "GenSigInvalidValue" SG_ 520 Wheel_Speed_RR_Valid_Data "1";
BA_ "GenSigCycleTime" SG_ 520 Wheel_Speed_RR_Valid_Data 20;
BA_ "GenSigInvalidValue" SG_ 520 Wheel_Speed_RL_Direction "3";
BA_ "GenSigCycleTime" SG_ 520 Wheel_Speed_RL_Direction 20;
BA_ "GenSigCycleTime" SG_ 520 Wheel_Speed_RR_Direction 20;
BA_ "GenSigCycleTime" SG_ 520 ESP_CRCCheck_208 20;
BA_ "GenSigCycleTime" SG_ 520 ESP_RollingCounter_208 20;
BA_ "GenSigInvalidValue" SG_ 600 ESP_MasCylBrakePressure "4095";
BA_ "GenSigCycleTime" SG_ 600 ESP_MasCylBrakePressure 20;
BA_ "GenSigCycleTime" SG_ 600 ESP_MasCylBrakePressureValid 20;
BA_ "GenSigInvalidValue" SG_ 600 Wheel_Speed_FL_Pulse "255";
BA_ "GenSigCycleTime" SG_ 600 Wheel_Speed_FL_Pulse 20;
BA_ "GenSigInvalidValue" SG_ 600 Wheel_Speed_FR_Pulse "255";
BA_ "GenSigCycleTime" SG_ 600 Wheel_Speed_FR_Pulse 20;
BA_ "GenSigInvalidValue" SG_ 600 Wheel_Speed_RL_Pulse "255";
BA_ "GenSigCycleTime" SG_ 600 Wheel_Speed_RL_Pulse 20;
BA_ "GenSigInvalidValue" SG_ 600 Wheel_Speed_RR_Pulse "255";
BA_ "GenSigCycleTime" SG_ 600 Wheel_Speed_RR_Pulse 20;
BA_ "GenSigCycleTime" SG_ 600 ESP_RollingCounter_258 20;
BA_ "GenSigCycleTime" SG_ 600 ESP_CRCCheck_258 20;
BA_ "GenSigInvalidValue" SG_ 631 ESP_VDCActive "0";
BA_ "GenSigCycleTime" SG_ 631 ESP_VDCActive 20;
BA_ "GenSigInvalidValue" SG_ 631 ESP_TCSActive "0";
BA_ "GenSigCycleTime" SG_ 631 ESP_TCSActive 20;
BA_ "GenSigInvalidValue" SG_ 631 ESP_OnlyABSActive "0";
BA_ "GenSigCycleTime" SG_ 631 ESP_OnlyABSActive 20;
BA_ "GenSigCycleTime" SG_ 631 ESP_CRCCheck_277 20;
BA_ "GenSigCycleTime" SG_ 631 ESP_RollingCounter_277 20;
BA_ "GenSigCycleTime" SG_ 631 ESP_VehicleStandstill 20;
BA_ "GenSigCycleTime" SG_ 631 ESP_BrakeForce 20;
BA_ "GenSigCycleTime" SG_ 632 ESP_YawRateValid 20;
BA_ "GenSigInvalidValue" SG_ 632 ESP_YawRate "16383";
BA_ "GenSigCycleTime" SG_ 632 ESP_YawRate 20;
BA_ "GenSigCycleTime" SG_ 632 ESP_CRCCheck_278 20;
BA_ "GenSigCycleTime" SG_ 632 ESP_RollingCounter_278 20;
BA_ "GenSigInvalidValue" SG_ 632 ESP_LongAccel "1023";
BA_ "GenSigCycleTime" SG_ 632 ESP_LongAccel 20;
BA_ "GenSigInvalidValue" SG_ 632 ESP_LatAccel "255";
BA_ "GenSigCycleTime" SG_ 632 ESP_LatAccel 20;
BA_ "GenSigInvalidValue" SG_ 832 AC_FrBlowType "7";
BA_ "GenSigCycleTime" SG_ 832 AC_FrBlowType 100;
BA_ "GenSigInvalidValue" SG_ 870 AC_EnvironmentalTemp "255";
BA_ "GenSigStartValue" SG_ 870 AC_EnvironmentalTemp 255;
BA_ "GenSigCycleTime" SG_ 870 AC_EnvironmentalTemp 100;
BA_ "GenSigInvalidValue" SG_ 870 AC_EnvironmentalTempVD "1";
BA_ "GenSigCycleTime" SG_ 870 AC_EnvironmentalTempVD 100;
BA_ "GenSigInvalidValue" SG_ 903 BCM_RainfallLevel "15";
BA_ "GenSigStartValue" SG_ 903 BCM_RainfallLevel 14;
BA_ "GenSigCycleTime" SG_ 903 BCM_RainfallLevel 100;
BA_ "GenSigInvalidValue" SG_ 903 BCM_FrontWiperStatus "3";
BA_ "GenSigCycleTime" SG_ 903 BCM_FrontWiperStatus 100;
BA_ "GenSigInvalidValue" SG_ 912 BCM_SOH_LifePercent "255";
BA_ "GenSigStartValue" SG_ 912 BCM_SOH_LifePercent 255;
BA_ "GenSigCycleTime" SG_ 912 BCM_SOH_LifePercent 500;
BA_ "GenSigCycleTime" SG_ 912 BCM_PMSLevel 500;
BA_ "GenSigInvalidValue" SG_ 1280 HU_CurrentLocationLatitude "268435455";
BA_ "GenSigCycleTime" SG_ 1280 HU_CurrentLocationLatitude 1000;
BA_ "GenSigInvalidValue" SG_ 1280 HU_CurrentLocationLongitude "536870911";
BA_ "GenSigCycleTime" SG_ 1280 HU_CurrentLocationLongitude 1000;
BA_ "GenSigInvalidValue" SG_ 1280 HU_CurrentLocationValid "1";
BA_ "GenSigCycleTime" SG_ 1280 HU_CurrentLocationValid 1000;
BA_ "GenSigInvalidValue" SG_ 1281 HU_LocalTimeSecond "0";
BA_ "GenSigCycleTime" SG_ 1281 HU_LocalTimeSecond 1000;
BA_ "GenSigInvalidValue" SG_ 1281 HU_LocalTimeMinute "0";
BA_ "GenSigCycleTime" SG_ 1281 HU_LocalTimeMinute 1000;
BA_ "GenSigInvalidValue" SG_ 1281 HU_LocalTimeHour "0";
BA_ "GenSigCycleTime" SG_ 1281 HU_LocalTimeHour 1000;
BA_ "GenSigInvalidValue" SG_ 1281 HU_LocalTimeDate "1";
BA_ "GenSigStartValue" SG_ 1281 HU_LocalTimeDate 1;
BA_ "GenSigCycleTime" SG_ 1281 HU_LocalTimeDate 1000;
BA_ "GenSigInvalidValue" SG_ 1281 HU_LocalTimeYear "0";
BA_ "GenSigCycleTime" SG_ 1281 HU_LocalTimeYear 1000;
BA_ "GenSigInvalidValue" SG_ 1281 HU_LocalTimeMonth "1";
BA_ "GenSigStartValue" SG_ 1281 HU_LocalTimeMonth 1;
BA_ "GenSigCycleTime" SG_ 1281 HU_LocalTimeMonth 1000;
BA_ "GenSigInvalidValue" SG_ 1281 HU_LocalTimeValid "1";
BA_ "GenSigCycleTime" SG_ 1281 HU_LocalTimeValid 1000;
BA_ "GenSigInvalidValue" SG_ 1328 IP_TotalOdometer "16777215";
BA_ "GenSigCycleTime" SG_ 1328 IP_TotalOdometer 500;
BA_ "GenSigCycleTime" SG_ 422 EMS_CRCCheck_1A6 10;
BA_ "GenSigCycleTime" SG_ 422 EMS_RollingCounter_1A6 10;
BA_ "GenSigCycleTime" SG_ 422 EMS_EngineStatus 10;
BA_ "GenSigInvalidValue" SG_ 424 TCU_ActualGear "15";
BA_ "GenSigCycleTime" SG_ 424 TCU_ActualGear 10;
BA_ "GenSigInvalidValue" SG_ 424 TCU_ActualGearValid "1";
BA_ "GenSigCycleTime" SG_ 424 TCU_ActualGearValid 10;
BA_ "GenSigInvalidValue" SG_ 424 TCU_GearShiftPosition "15";
BA_ "GenSigStartValue" SG_ 424 TCU_GearShiftPosition 14;
BA_ "GenSigCycleTime" SG_ 424 TCU_GearShiftPosition 10;
BA_ "GenSigInvalidValue" SG_ 424 TCU_ShiftPostionValid "1";
BA_ "GenSigCycleTime" SG_ 424 TCU_ShiftPostionValid 10;
BA_ "GenSigCycleTime" SG_ 424 TCU_CRCCheck_1A8 10;
BA_ "GenSigCycleTime" SG_ 424 TCU_RollingCounter_1A8 10;
BA_ "GenSigInvalidValue" SG_ 591 EPS_ConcussAvailabilityStatus "2";
BA_ "GenSigCycleTime" SG_ 591 EPS_ConcussAvailabilityStatus 20;
BA_ "GenSigStartValue" SG_ 591 EPS_TorqueAssistMode 3;
BA_ "GenSigCycleTime" SG_ 591 EPS_TorqueAssistMode 20;
BA_ "GenSigCycleTime" SG_ 591 EPS_IACC_abortreason 20;
BA_ "GenSigCycleTime" SG_ 591 EPS_CRCCheck_24F 20;
BA_ "GenSigCycleTime" SG_ 591 EPS_RollingCounter_24F 20;
BA_ "GenSigInvalidValue" SG_ 651 LCM_LASSwitch "3";
BA_ "GenSigCycleTime" SG_ 651 LCM_LASSwitch 40;
BA_ "GenSigInvalidValue" SG_ 651 BCM_TurnIndicatorLeft "3";
BA_ "GenSigCycleTime" SG_ 651 BCM_TurnIndicatorLeft 40;
BA_ "GenSigInvalidValue" SG_ 651 BCM_TurnIndicatorRight "3";
BA_ "GenSigCycleTime" SG_ 651 BCM_TurnIndicatorRight 40;
BA_ "GenSigInvalidValue" SG_ 651 BCM_emergencylightstatus "3";
BA_ "GenSigCycleTime" SG_ 651 BCM_emergencylightstatus 40;
BA_ "GenSigInvalidValue" SG_ 651 BCM_LowBeamStatus "3";
BA_ "GenSigCycleTime" SG_ 651 BCM_LowBeamStatus 40;
BA_ "GenSigInvalidValue" SG_ 651 BCM_HighBeamStatus "3";
BA_ "GenSigCycleTime" SG_ 651 BCM_HighBeamStatus 40;
BA_ "GenSigInvalidValue" SG_ 651 BCM_TurnLightSwitchSts "3";
BA_ "GenSigCycleTime" SG_ 651 BCM_TurnLightSwitchSts 40;
BA_ "GenSigCycleTime" SG_ 943 HU_CRCCheck_3AF 100;
BA_ "GenSigCycleTime" SG_ 943 HU_RollingCounter_3AF 100;
BA_ "GenSigInvalidValue" SG_ 943 HU_RampDistance "63";
BA_ "GenSigStartValue" SG_ 943 HU_RampDistance 63;
BA_ "GenSigCycleTime" SG_ 943 HU_RampDistance 100;
BA_ "GenSigInvalidValue" SG_ 943 HU_NavCurrentRoadType "0";
BA_ "GenSigCycleTime" SG_ 943 HU_NavCurrentRoadType 100;
BA_ "GenSigInvalidValue" SG_ 943 HU_RampInfo "0";
BA_ "GenSigCycleTime" SG_ 943 HU_RampInfo 100;
BA_ "GenSigInvalidValue" SG_ 943 HU_NavStatus "1";
BA_ "GenSigCycleTime" SG_ 943 HU_NavStatus 100;
BA_ "GenSigInvalidValue" SG_ 943 HU_NavSpeedLimitStatus "1";
BA_ "GenSigCycleTime" SG_ 943 HU_NavSpeedLimitStatus 100;
BA_ "GenSigInvalidValue" SG_ 943 HU_NavSpeedLimit "255";
BA_ "GenSigStartValue" SG_ 943 HU_NavSpeedLimit 254;
BA_ "GenSigCycleTime" SG_ 943 HU_NavSpeedLimit 100;
BA_ "GenSigCycleTime" SG_ 952 HU_CRCCheck_3B8 100;
BA_ "GenSigCycleTime" SG_ 952 HU_RollingCounter_3B8 100;
BA_ "GenSigInvalidValue" SG_ 952 HU_NavGuiganceStatus "3";
BA_ "GenSigCycleTime" SG_ 952 HU_NavGuiganceStatus 100;
BA_ "GenSigInvalidValue" SG_ 952 HU_TunnelLength "63";
BA_ "GenSigStartValue" SG_ 952 HU_TunnelLength 63;
BA_ "GenSigCycleTime" SG_ 952 HU_TunnelLength 100;
BA_ "GenSigInvalidValue" SG_ 952 HU_TunnelDistance "63";
BA_ "GenSigStartValue" SG_ 952 HU_TunnelDistance 63;
BA_ "GenSigCycleTime" SG_ 952 HU_TunnelDistance 100;
BA_ "GenSigInvalidValue" SG_ 952 HU_EnterTunnelInfo "0";
BA_ "GenSigCycleTime" SG_ 952 HU_EnterTunnelInfo 100;
BA_ "GenSigInvalidValue" SG_ 1023 BCM_AutoHeadlightSts "0";
BA_ "GenSigCycleTime" SG_ 1023 BCM_AutoHeadlightSts 100;
BA_ "GenSigInvalidValue" SG_ 1023 BCM_FrontFoglampStatus "3";
BA_ "GenSigCycleTime" SG_ 1023 BCM_FrontFoglampStatus 100;
BA_ "GenSigInvalidValue" SG_ 1023 BCM_RearFoglampStatus "3";
BA_ "GenSigCycleTime" SG_ 1023 BCM_RearFoglampStatus 100;
BA_ "GenSigCycleTime" SG_ 583 APA_APAOnOff 20;
BA_ "GenSigCycleTime" SG_ 676 LCDAR_CRCCheck_2AF 50;
BA_ "GenSigCycleTime" SG_ 676 LCDAR_RollingCounter_2AF 50;
BA_ "GenSigCycleTime" SG_ 676 LCDAR_ELK_oAlert 50;
BA_ "GenSigInvalidValue" SG_ 676 LCDAR_ELK_oStatus "3";
BA_ "GenSigCycleTime" SG_ 676 LCDAR_ELK_oStatus 50;
BA_ "GenSigCycleTime" SG_ 676 LCDAR_Left_ELK_oAlert 50;
BA_ "GenSigInvalidValue" SG_ 676 LCDAR_BSD_LCAStatus "3";
BA_ "GenSigCycleTime" SG_ 676 LCDAR_BSD_LCAStatus 50;
BA_ "GenSigCycleTime" SG_ 922 LAS_TLAObjectType_HostLane 100;
BA_ "GenSigInvalidValue" SG_ 922 LAS_TSRRightLaneStatus "7";
BA_ "GenSigCycleTime" SG_ 922 LAS_TSRRightLaneStatus 100;
BA_ "GenSigInvalidValue" SG_ 922 LAS_TSRLeftLaneStatus "7";
BA_ "GenSigCycleTime" SG_ 922 LAS_TSRLeftLaneStatus 100;
BA_ "GenSigCycleTime" SG_ 922 LAS_CRCCheck_3C0 100;
BA_ "GenSigCycleTime" SG_ 922 LAS_RollingCounter_3C0 100;
BA_ "GenSigInvalidValue" SG_ 922 LAS_TSRRightLaneSpdLimit "254";
BA_ "GenSigCycleTime" SG_ 922 LAS_TSRRightLaneSpdLimit 100;
BA_ "GenSigInvalidValue" SG_ 922 LAS_TSRLeftLaneSpdLimit "254";
BA_ "GenSigCycleTime" SG_ 922 LAS_TSRLeftLaneSpdLimit 100;
BA_ "GenSigCycleTime" SG_ 922 LAS_CRCCheck_3D4 100;
BA_ "GenSigCycleTime" SG_ 922 LAS_RollingCounter_3D4 100;
BA_ "GenSigStartValue" SG_ 922 LAS_TLAStopLine_HostLane 255;
BA_ "GenSigCycleTime" SG_ 922 LAS_TLAStopLine_HostLane 100;
BA_ "GenSigStartValue" SG_ 922 LAS_TLADistance_HostLane 255;
BA_ "GenSigCycleTime" SG_ 922 LAS_TLADistance_HostLane 100;
BA_ "GenSigCycleTime" SG_ 922 LAS_TLACountDownTime_HostLane 100;
BA_ "GenSigCycleTime" SG_ 922 LAS_TSRMandatorySign 100;
BA_ "GenSigCycleTime" SG_ 922 LAS_TSRWarningSign 100;
BA_ "GenSigCycleTime" SG_ 922 LAS_TSRProhibitionSign 100;
BA_ "GenSigCycleTime" SG_ 922 LAS_CRCCheck_332 100;
BA_ "GenSigCycleTime" SG_ 922 LAS_RollingCounter_332 100;
BA_ "GenSigCycleTime" SG_ 922 LAS_OverspeedSoundWarningEnSt 100;
BA_ "GenSigCycleTime" SG_ 922 LAS_TSREnable 100;
BA_ "GenSigCycleTime" SG_ 922 LAS_HMAEnableStatus 100;
BA_ "GenSigCycleTime" SG_ 922 LAS_HMALightDistribution 100;
BA_ "GenSigInvalidValue" SG_ 922 LAS_HMAStatus "3";
BA_ "GenSigCycleTime" SG_ 922 LAS_HMAStatus 100;
BA_ "GenSigInvalidValue" SG_ 922 LAS_TSRHostSpdLimitUnits "0";
BA_ "GenSigCycleTime" SG_ 922 LAS_TSRHostSpdLimitUnits 100;
BA_ "GenSigInvalidValue" SG_ 922 LAS_TSRHostSpdLimit "254";
BA_ "GenSigCycleTime" SG_ 922 LAS_TSRHostSpdLimit 100;
BA_ "GenSigInvalidValue" SG_ 922 LAS_TSRStatus "7";
BA_ "GenSigCycleTime" SG_ 922 LAS_TSRStatus 100;
BA_ "GenSigInvalidValue" SG_ 922 LAS_FrontCameraCalibrationStatus "3";
BA_ "GenSigCycleTime" SG_ 922 LAS_FrontCameraCalibrationStatus 100;
BA_ "GenSigInvalidValue" SG_ 922 LAS_FrontCameraFailureStatus "3";
BA_ "GenSigCycleTime" SG_ 922 LAS_FrontCameraFailureStatus 100;
BA_ "GenSigStartValue" SG_ 922 LAS_OverspeedWarningOffset 10;
BA_ "GenSigCycleTime" SG_ 922 LAS_OverspeedWarningOffset 100;
BA_ "GenSigCycleTime" SG_ 922 LAS_OverspeedWarningEnableStatus 100;
BA_ "GenSigCycleTime" SG_ 922 LAS_OverspeedSoundWarning 100;
BA_ "GenSigCycleTime" SG_ 922 LAS_OverspeedVisualWarning 100;
BA_ "GenSigCycleTime" SG_ 922 LAS_CRCCheck_37D 100;
BA_ "GenSigCycleTime" SG_ 922 LAS_RollingCounter_37D 100;
BA_ "GenSigCycleTime" SG_ 922 LAS_TLAArrowDirection_RightLane 100;
BA_ "GenSigCycleTime" SG_ 922 LAS_TLAObjectType_RightLane 100;
BA_ "GenSigCycleTime" SG_ 922 LAS_TLAObjectStatus_RightLane 100;
BA_ "GenSigCycleTime" SG_ 922 LAS_TLAObjectColour_RightLane 100;
BA_ "GenSigCycleTime" SG_ 922 LAS_TLAObjectDetection_RightLane 100;
BA_ "GenSigCycleTime" SG_ 922 LAS_TLAArrowDirection_LeftLane 100;
BA_ "GenSigCycleTime" SG_ 922 LAS_TLAObjectType_LeftLane 100;
BA_ "GenSigCycleTime" SG_ 922 LAS_TLAObjectStatus_LeftLane 100;
BA_ "GenSigCycleTime" SG_ 922 LAS_TLAObjectColour_LeftLane 100;
BA_ "GenSigCycleTime" SG_ 922 LAS_TLAObjectDetection_LeftLane 100;
BA_ "GenSigCycleTime" SG_ 922 LAS_TLAArrowDirection_HostLane 100;
BA_ "GenSigCycleTime" SG_ 922 LAS_TLAObjectStatus_HostLane 100;
BA_ "GenSigCycleTime" SG_ 922 LAS_TLAObjectColour_HostLane 100;
BA_ "GenSigCycleTime" SG_ 922 LAS_TLAObjectDetection_HostLane 100;
BA_ "GenSigCycleTime" SG_ 922 LAS_TLAWarninglevel 100;
BA_ "GenSigInvalidValue" SG_ 922 LAS_TLAStatus "3";
BA_ "GenSigCycleTime" SG_ 922 LAS_TLAStatus 100;
BA_ "GenSigCycleTime" SG_ 922 LAS_TLAEnable 100;
BA_ "GenSigCycleTime" SG_ 1684 LAS_DTC2_Status 500;
BA_ "GenSigCycleTime" SG_ 1684 LAS_DTC2_LowByte 500;
BA_ "GenSigCycleTime" SG_ 1684 LAS_DTC2_MiddByte 500;
BA_ "GenSigCycleTime" SG_ 1684 LAS_DTC2_HighByte 500;
BA_ "GenSigCycleTime" SG_ 1684 LAS_DTC1_Status 500;
BA_ "GenSigCycleTime" SG_ 1684 LAS_DTC1_LowByte 500;
BA_ "GenSigCycleTime" SG_ 1684 LAS_DTC1_MiddByte 500;
BA_ "GenSigCycleTime" SG_ 1684 LAS_DTC1_HighByte 500;
BA_ "GenSigInvalidValue" SG_ 999 BCM_Status_Temp "0";
BA_ "GenSigCycleTime" SG_ 999 BCM_Status_Temp 100;
BA_ "GenSigInvalidValue" SG_ 999 BCM_T_BATT "255";
BA_ "GenSigStartValue" SG_ 999 BCM_T_BATT 255;
BA_ "GenSigCycleTime" SG_ 999 BCM_T_BATT 100;
BA_ "GenSigInvalidValue" SG_ 1000 BCM_SOF_Q_STATE "3";
BA_ "GenSigStartValue" SG_ 1000 BCM_SOF_Q_STATE 3;
BA_ "GenSigCycleTime" SG_ 1000 BCM_SOF_Q_STATE 100;
BA_ "GenSigInvalidValue" SG_ 1000 BCM_SOF_Q "255";
BA_ "GenSigStartValue" SG_ 1000 BCM_SOF_Q 255;
BA_ "GenSigCycleTime" SG_ 1000 BCM_SOF_Q 100;
BA_ "GenSigCycleTime" SG_ 790 LAS_RollingCounter_316 100;
BA_ "GenSigCycleTime" SG_ 790 LAS_CRCCheck_316 100;
BA_ "GenSigCycleTime" SG_ 790 LAS_Line_03_MeasureType 100;
BA_ "GenSigStartValue" SG_ 790 LAS_Line_03_curvature_alteration 2048;
BA_ "GenSigCycleTime" SG_ 790 LAS_Line_03_curvature_alteration 100;
BA_ "GenSigStartValue" SG_ 790 LAS_Line_03__curve 4096;
BA_ "GenSigCycleTime" SG_ 790 LAS_Line_03__curve 100;
BA_ "GenSigStartValue" SG_ 790 LAS_Line_03_HeadingAngle 3277;
BA_ "GenSigCycleTime" SG_ 790 LAS_Line_03_HeadingAngle 100;
BA_ "GenSigCycleTime" SG_ 790 LAS_Line_03_dy 100;
BA_ "GenSigCycleTime" SG_ 790 LAS_Line_03_dx_End_std 100;
BA_ "GenSigCycleTime" SG_ 790 LAS_Line_03__dx_End 100;
BA_ "GenSigCycleTime" SG_ 790 LAS_Line_03_dx_Start_std 100;
BA_ "GenSigCycleTime" SG_ 790 LAS_Line_03_dx_Start 100;
BA_ "GenSigCycleTime" SG_ 790 LAS_Line_03_Width 100;
BA_ "GenSigCycleTime" SG_ 790 LAS_Line_03_color 100;
BA_ "GenSigStartValue" SG_ 790 LAS_Line_03_Id 1;
BA_ "GenSigCycleTime" SG_ 790 LAS_Line_03_Id 100;
BA_ "GenSigCycleTime" SG_ 790 LAS_Line_03_TypeConfidence 100;
BA_ "GenSigCycleTime" SG_ 790 LAS_Line_03_Type 100;
BA_ "GenSigCycleTime" SG_ 790 LAS_Line_02__exist_prob 100;
BA_ "GenSigCycleTime" SG_ 790 LAS_Line_02_MeasureType 100;
BA_ "GenSigStartValue" SG_ 790 LAS_Line_02_curvature_alteration 2048;
BA_ "GenSigCycleTime" SG_ 790 LAS_Line_02_curvature_alteration 100;
BA_ "GenSigStartValue" SG_ 790 LAS_Line_02__curve 4096;
BA_ "GenSigCycleTime" SG_ 790 LAS_Line_02__curve 100;
BA_ "GenSigStartValue" SG_ 790 LAS_Line_02_HeadingAngle 3277;
BA_ "GenSigCycleTime" SG_ 790 LAS_Line_02_HeadingAngle 100;
BA_ "GenSigCycleTime" SG_ 790 LAS_Line_02_dy 100;
BA_ "GenSigCycleTime" SG_ 790 LAS_Line_02_dx_End_std 100;
BA_ "GenSigCycleTime" SG_ 790 LAS_Line_02__dx_End 100;
BA_ "GenSigCycleTime" SG_ 790 LAS_Line_02_dx_Start_std 100;
BA_ "GenSigCycleTime" SG_ 790 LAS_Line_02_dx_Start 100;
BA_ "GenSigCycleTime" SG_ 790 LAS_Line_02_Width 100;
BA_ "GenSigCycleTime" SG_ 790 LAS_Line_02_color 100;
BA_ "GenSigStartValue" SG_ 790 LAS_Line_02_Id 1;
BA_ "GenSigCycleTime" SG_ 790 LAS_Line_02_Id 100;
BA_ "GenSigCycleTime" SG_ 790 LAS_Line_02_TypeConfidence 100;
BA_ "GenSigCycleTime" SG_ 790 LAS_Line_02_Type 100;
BA_ "GenSigCycleTime" SG_ 790 LAS_Line_01__exist_prob 100;
BA_ "GenSigCycleTime" SG_ 790 LAS_Line_01_MeasureType 100;
BA_ "GenSigStartValue" SG_ 790 LAS_Line_01_curvature_alteration 2048;
BA_ "GenSigCycleTime" SG_ 790 LAS_Line_01_curvature_alteration 100;
BA_ "GenSigStartValue" SG_ 790 LAS_Line_01__curve 4096;
BA_ "GenSigCycleTime" SG_ 790 LAS_Line_01__curve 100;
BA_ "GenSigStartValue" SG_ 790 LAS_Line_01_HeadingAngle 3277;
BA_ "GenSigCycleTime" SG_ 790 LAS_Line_01_HeadingAngle 100;
BA_ "GenSigCycleTime" SG_ 790 LAS_Line_01_dy 100;
BA_ "GenSigCycleTime" SG_ 790 LAS_Line_01_dx_End_std 100;
BA_ "GenSigCycleTime" SG_ 790 LAS_Line_01__dx_End 100;
BA_ "GenSigCycleTime" SG_ 790 LAS_Line_01_dx_Start_std 100;
BA_ "GenSigCycleTime" SG_ 790 LAS_Line_01_dx_Start 100;
BA_ "GenSigCycleTime" SG_ 790 LAS_Line_01_Width 100;
BA_ "GenSigCycleTime" SG_ 790 LAS_Line_01_color 100;
BA_ "GenSigStartValue" SG_ 790 LAS_Line_01_Id 1;
BA_ "GenSigCycleTime" SG_ 790 LAS_Line_01_Id 100;
BA_ "GenSigCycleTime" SG_ 790 LAS_Line_01_TypeConfidence 100;
BA_ "GenSigCycleTime" SG_ 790 LAS_Line_01_Type 100;
BA_ "GenSigCycleTime" SG_ 822 LAS_RollingCounter_336 100;
BA_ "GenSigCycleTime" SG_ 822 LAS_CRCCheck_336 100;
BA_ "GenSigCycleTime" SG_ 822 LAS_Line_06__exist_prob 100;
BA_ "GenSigCycleTime" SG_ 822 LAS_Line_06_MeasureType 100;
BA_ "GenSigStartValue" SG_ 822 LAS_Line_06_curvature_alteration 2048;
BA_ "GenSigCycleTime" SG_ 822 LAS_Line_06_curvature_alteration 100;
BA_ "GenSigStartValue" SG_ 822 LAS_Line_06__curve 4096;
BA_ "GenSigCycleTime" SG_ 822 LAS_Line_06__curve 100;
BA_ "GenSigStartValue" SG_ 822 LAS_Line_06_HeadingAngle 3277;
BA_ "GenSigCycleTime" SG_ 822 LAS_Line_06_HeadingAngle 100;
BA_ "GenSigCycleTime" SG_ 822 LAS_Line_06_dy 100;
BA_ "GenSigCycleTime" SG_ 822 LAS_Line_06_dx_End_std 100;
BA_ "GenSigCycleTime" SG_ 822 LAS_Line_06__dx_End 100;
BA_ "GenSigCycleTime" SG_ 822 LAS_Line_06_dx_Start_std 100;
BA_ "GenSigCycleTime" SG_ 822 LAS_Line_06_dx_Start 100;
BA_ "GenSigCycleTime" SG_ 822 LAS_Line_06_Width 100;
BA_ "GenSigCycleTime" SG_ 822 LAS_Line_06_color 100;
BA_ "GenSigStartValue" SG_ 822 LAS_Line_06_Id 1;
BA_ "GenSigCycleTime" SG_ 822 LAS_Line_06_Id 100;
BA_ "GenSigCycleTime" SG_ 822 LAS_Line_06_TypeConfidence 100;
BA_ "GenSigCycleTime" SG_ 822 LAS_Line_06_Type 100;
BA_ "GenSigCycleTime" SG_ 822 LAS_Line_05__exist_prob 100;
BA_ "GenSigCycleTime" SG_ 822 LAS_Line_05_MeasureType 100;
BA_ "GenSigStartValue" SG_ 822 LAS_Line_05_curvature_alteration 2048;
BA_ "GenSigCycleTime" SG_ 822 LAS_Line_05_curvature_alteration 100;
BA_ "GenSigStartValue" SG_ 822 LAS_Line_05__curve 4096;
BA_ "GenSigCycleTime" SG_ 822 LAS_Line_05__curve 100;
BA_ "GenSigStartValue" SG_ 822 LAS_Line_05_HeadingAngle 3277;
BA_ "GenSigCycleTime" SG_ 822 LAS_Line_05_HeadingAngle 100;
BA_ "GenSigCycleTime" SG_ 822 LAS_Line_05_dy 100;
BA_ "GenSigCycleTime" SG_ 822 LAS_Line_05_dx_End_std 100;
BA_ "GenSigCycleTime" SG_ 822 LAS_Line_05__dx_End 100;
BA_ "GenSigCycleTime" SG_ 822 LAS_Line_05_dx_Start_std 100;
BA_ "GenSigCycleTime" SG_ 822 LAS_Line_05_dx_Start 100;
BA_ "GenSigCycleTime" SG_ 822 LAS_Line_05_Width 100;
BA_ "GenSigCycleTime" SG_ 822 LAS_Line_05_color 100;
BA_ "GenSigStartValue" SG_ 822 LAS_Line_05_Id 1;
BA_ "GenSigCycleTime" SG_ 822 LAS_Line_05_Id 100;
BA_ "GenSigCycleTime" SG_ 822 LAS_Line_05_TypeConfidence 100;
BA_ "GenSigCycleTime" SG_ 822 LAS_Line_05_Type 100;
BA_ "GenSigCycleTime" SG_ 822 LAS_Line_04__exist_prob 100;
BA_ "GenSigCycleTime" SG_ 822 LAS_Line_04_MeasureType 100;
BA_ "GenSigStartValue" SG_ 822 LAS_Line_04_curvature_alteration 2048;
BA_ "GenSigCycleTime" SG_ 822 LAS_Line_04_curvature_alteration 100;
BA_ "GenSigStartValue" SG_ 822 LAS_Line_04__curve 4096;
BA_ "GenSigCycleTime" SG_ 822 LAS_Line_04__curve 100;
BA_ "GenSigStartValue" SG_ 822 LAS_Line_04_HeadingAngle 3277;
BA_ "GenSigCycleTime" SG_ 822 LAS_Line_04_HeadingAngle 100;
BA_ "GenSigCycleTime" SG_ 822 LAS_Line_04_dy 100;
BA_ "GenSigCycleTime" SG_ 822 LAS_Line_04_dx_End_std 100;
BA_ "GenSigCycleTime" SG_ 822 LAS_Line_04__dx_End 100;
BA_ "GenSigCycleTime" SG_ 822 LAS_Line_04_dx_Start_std 100;
BA_ "GenSigCycleTime" SG_ 822 LAS_Line_04_dx_Start 100;
BA_ "GenSigCycleTime" SG_ 822 LAS_Line_04_Width 100;
BA_ "GenSigCycleTime" SG_ 822 LAS_Line_04_color 100;
BA_ "GenSigStartValue" SG_ 822 LAS_Line_04_Id 1;
BA_ "GenSigCycleTime" SG_ 822 LAS_Line_04_Id 100;
BA_ "GenSigCycleTime" SG_ 822 LAS_Line_04_TypeConfidence 100;
BA_ "GenSigCycleTime" SG_ 822 LAS_Line_04_Type 100;
BA_ "GenSigCycleTime" SG_ 822 LAS_Line_03__exist_prob 100;
BA_ "GenSigInvalidValue" SG_ 962 HU_TollDis "63";
BA_ "GenSigStartValue" SG_ 962 HU_TollDis 63;
BA_ "GenSigCycleTime" SG_ 962 HU_TollDis 100;
BA_ "GenSigInvalidValue" SG_ 962 HU_TollInfo "3";
BA_ "GenSigStartValue" SG_ 962 HU_TollInfo 3;
BA_ "GenSigCycleTime" SG_ 962 HU_TollInfo 100;
BA_ "GenSigSendType" SG_ 1874 Phys_Diag_Rx 7;
BA_ "GenSigSendType" SG_ 1882 Diag_Response 7;
BA_ "GenSigSendType" SG_ 1891 Phys_Diag_Rx_CAN 7;
BA_ "GenSigSendType" SG_ 1899 Diag_Response_CAN 7;
VAL_ 3221225472 HU_RoadCurvature_40m 0 " -0.16192 ~ -0.00001,negative number represents curve to left" 8191 " 0,represents straight" 512 " 0.00001 ~ 0.16192,positive number represents curve to right" 1791 " unknown" ;
VAL_ 3221225472 HU_RoadCurvature_30m 0 " -0.16192 ~ -0.00001,negative number represents curve to left" 8191 " 0,represents straight" 512 " 0.00001 ~ 0.16192,positive number represents curve to right" 1535 " unknown" ;
VAL_ 3221225472 HU_RoadCurvature_20m 0 " -0.16192 ~ -0.00001,negative number represents curve to left" 8191 " 0,represents straight" 512 " 0.00001 ~ 0.16192,positive number represents curve to right" 1279 " unknown" ;
VAL_ 3221225472 HU_RoadCurvature_10m 0 " -0.16192 ~ -0.00001,negative number represents curve to left" 8191 " 0,represents straight" 512 " 0.00001 ~ 0.16192,positive number represents curve to right" 1023 " unknown" ;
VAL_ 3221225472 HU_Lane_Changtype 0 "NO change" 1 "Merge" 2 "Separate" 3 "invalid" ;
VAL_ 3221225472 HU_To_NumchangeOfLanes_Dist 0 " 0~600m" 61 "Out of Range" 62 "reserved" 63 "unknown" ;
VAL_ 3221225472 HU_RoadCurvature_90m 0 " -0.16192 ~ -0.00001,negative number represents curve to left" 8191 " 0,represents straight" 512 " 0.00001 ~ 0.16192,positive number represents curve to right" 4607 " unknown" ;
VAL_ 3221225472 HU_RoadCurvature_80m 0 " -0.16192 ~ -0.00001,negative number represents curve to left" 8191 " 0,represents straight" 512 " 0.00001 ~ 0.16192,positive number represents curve to right" 4351 " unknown" ;
VAL_ 3221225472 HU_RoadCurvature_70m 0 " -0.16192 ~ -0.00001,negative number represents curve to left" 8191 " 0,represents straight" 512 " 0.00001 ~ 0.16192,positive number represents curve to right" 2559 " unknown" ;
VAL_ 3221225472 HU_RoadCurvature_60m 0 " -0.16192 ~ -0.00001,negative number represents curve to left" 8191 " 0,represents straight" 512 " 0.00001 ~ 0.16192,positive number represents curve to right" 2303 " unknown" ;
VAL_ 3221225472 HU_RoadCurvature_50m 0 " -0.16192 ~ -0.00001,negative number represents curve to left" 8191 " 0,represents straight" 512 " 0.00001 ~ 0.16192,positive number represents curve to right" 2047 " unknown" ;
VAL_ 3221225472 HU_BranchInfo 0 "unknown" 1 "There is a branch, but car does not pass through" 2 "There is a branch, and car passes through" 3 "Reserved" ;
VAL_ 3221225472 GW_MFS_HODCalibratedStatus 0 "Not Calibrated" 1 "Calibrated" ;
VAL_ 3221225472 GW_MFS_HODLinStatus 0 "no fault" 1 "fault" ;
VAL_ 3221225472 GW_MFS_HODAppStatus 0 "no fault" 1 "fault" ;
VAL_ 3221225472 GW_MFS_HODSenserStatus 0 "no fault" 1 "fault" ;
VAL_ 3221225472 GW_MFS_HODSystemStatus 0 "no fault" 1 "fault" 2 "block" 3 "reserved" ;
VAL_ 3221225472 GW_MFS_handsoffAbilityDetect 0 " hands off" 1 " hands on without takeover ability" 2 " hands on with takeover ability" 3 " unkown" 4 "reserved" ;
VAL_ 3221225472 GW_MFS_handsoffDetectResult 0 "no Touch" 1 "Left Wheel Touch" 2 "Right Wheel Touch" 3 "Rear Wheel Touch" 4 "Left Wheel Grip" 5 "Right Wheel Grip" 6 "Both side touch" 7 " Both side Grip" ;
VAL_ 3221225472 GW_MFS_DiagInfoSW_28C 0 "Reset" 1 "Variant information error" 2 "Power supply is higher than 16V" 3 "Power supply is lower than 9V" 4 "reversed" 7 "invalid" ;
VAL_ 3221225472 HU_MapMatchStatus 0 "Successl" 1 "Fail" 2 "Reserved" 3 "Invalid" ;
VAL_ 3221225472 HU_SlopeGradient_300m 1023 " unknown" ;
VAL_ 3221225472 HU_RoadCurvature_600m 0 " -0.16192 ~ -0.00001,negative number represents curve to left" 8191 " 0,represents straight" 512 " 0.00001 ~ 0.16192,positive number represents curve to right" 5631 " unknown" ;
VAL_ 3221225472 HU_RoadCurvature_400m 0 " -0.16192 ~ -0.00001,negative number represents curve to left" 8191 " 0,represents straight" 512 " 0.00001 ~ 0.16192,positive number represents curve to right" 5375 " unknown" ;
VAL_ 3221225472 HU_RoadCurvature_300m 0 " -0.16192 ~ -0.00001,negative number represents curve to left" 8191 " 0,represents straight" 512 " 0.00001 ~ 0.16192,positive number represents curve to right" 5119 " unknown" ;
VAL_ 3221225472 HU_RoadCurvature_100m 0 " -0.16192 ~ -0.00001,negative number represents curve to left" 8191 " 0,represents straight" 512 " 0.00001 ~ 0.16192,positive number represents curve to right" 4863 " unknown" ;
VAL_ 3221225472 IMS_JawOffsetValue 0 " 0cm" 1 "1cm~15cm" ;
VAL_ 3221225472 IMS_BrowOffsetValue 0 " 0cm" 1 "1cm~15cm" ;
VAL_ 3221225472 IMS_HeadDetectSts_Yaw 0 "-75~75" 152 "Reserved" 255 "invalid" ;
VAL_ 3221225472 IMS_HeadDetectSts_Roll 0 "-45~45" 92 "Reserved" 255 "invalid" ;
VAL_ 3221225472 IMS_HeadDetectSts_Pitch 0 "-25~45" 72 "Reserved" 255 "invalid" ;
VAL_ 3221225472 IMS_PhoneCallSts 0 " Not In Phone Call" 1 " In Phone Call" ;
VAL_ 3221225472 IMS_DriverEyesFovArea 0 "driver forward" 1 "left outside mirror" 2 "right outside mirror" 3 " inside mirror" 4 " front passenger forward" 5 " HU area " 6 "IP area" 7 " gear area" 8 " below IP" 9 " driver door" 10 " front passenger" 11 " driver door window" 12 "up forward" 13 " front passenger door window" 14 " other" 15 "invalid" ;
VAL_ 3221225472 IMS_DriverEyeClosestatus 0 " both eyes close" 1 "left eye close" 2 " right ?eye close" 3 "both eyes open" 4 " Reserved" 7 " Invalid" ;
VAL_ 3221225472 IMS_DriverEyeConfidence 0 "0~100%" 101 "Reserved" 255 "invalid" ;
VAL_ 3221225472 IMS_DriverEyeDetect 0 "Invalid" 1 "Not detected" 2 "detected" 3 "Reserved" ;
VAL_ 3221225472 IMS_IMSStatus 0 " Off" 1 " Standby" 2 " Active" 3 " Camera Blocked" 4 " Failure" 5 " Reserved" 7 " Invalid" ;
VAL_ 3221225472 IMS_EyeGazeStatus 0 "-75~75" 152 "Reserved" 255 "invalid" ;
VAL_ 3221225472 IMS_EyeDetectSatus 0 "0~100%" 101 "Reserved" 255 "invalid   " ;
VAL_ 3221225472 IMS_DrowsinessStatus 0 " Awake" 1 " Slightly Drowsy" 2 " Drowsy" 3 "Microsleep" 4 " Reserved" 5 " Unavailable" 6 "Unknown" 7 " Invalid" ;
VAL_ 3221225472 IMS_DriverHeadDetect 0 "Invalid" 1 "Not detected" 2 "detected" 3 "Reserved" ;
VAL_ 3221225472 IMS_DistractionStatus 0 " Not Distracted" 1 " Distracted" 2 "Unknown" 3 " Invalid" ;
VAL_ 3221225472 HU_NavSpeedLimitType 0 "Unknown" 1 "Speed-Limit Sign" 2 "Road Camera" 3 "Interval Velocity" ;
VAL_ 3221225472 HU_CurveDistance 0 " 0~600m" 61 "Out of Range" 62 "reserved" 63 "unknown" ;
VAL_ 3221225472 HU_EnterCurveInfo 0 " unknown" 1 "Curved entrance" 2 "In a curve" 3 "Corner exit" ;
VAL_ 3221225472 HU_EnterRampInfo 0 "Unknown" 1 "Ramp entrance" 2 "On the ramp" 3 "Ramp exit" ;
VAL_ 3221225472 HU_NavSpeedLimitUnits 3 "reserved" 2 "unit mph" 1 "unit kph" 0 "unknown." ;
VAL_ 3221225472 HU_SlopeDistance 0 " 0~600m" 61 "Out of Range" 62 "reserved" 63 "unknown" ;
VAL_ 3221225472 HU_Byroad 0 "unknown" 1 "There is a byroad" 2 "No byroad" 3 "reserved" ;
VAL_ 3221225472 HU_RoadCurvatureFar 0 " -0.16192 ~ -0.00001, negative number represents curve to left" 8191 " 0,0 represents straight" 512 " 0.00001 ~ 0.16192,positive number represents curve to right" 1023 " unknown" ;
VAL_ 3221225472 HU_RoadCurvature 0 " -0.16192 ~ -0.00001,negative number represents curve to left" 8191 " 0,0 represents straight" 512 " 0.00001 ~ 0.16192,positive number represents curve to right" 1023 " unknown" ;
VAL_ 3221225472 HU_EnterSlopeInfo 0 "unknown" 1 "Ramp entrance" 2 "In the ramp" 3 "Ramp exit" ;
VAL_ 3221225472 HU_SpeedLimitDistance 0 " 0~600m" 61 "Out of Range" 62 "reserved" 63 "unknown" ;
VAL_ 3221225472 HU_MapDataUpdateStatus 0 "Not updated" 1 "Updated within 1 month" 2 "Updated within 3 months" 3 "Updated within 6 months" 4 "Updated within 1 year" 5 " reserved" 7 "Invalid" ;
VAL_ 3221225472 HU_Road_TrafficFlow 0 "unknown" 1 "Unblocked" 2 "go slowly" 3 " congestion" 4 "severe congestion" 5 "no traffic flow" 6 "reserved" 7 "invalid" ;
VAL_ 3221225472 HU_To_Branch_Dis 0 " 0~600m" 61 "Out of Range" 62 "reserved" 63 "unknown" ;
VAL_ 3221225472 HU_To_TrafficAccident_Dis 0 " 0~600m" 61 "Out of Range" 62 "reserved" 63 "unknown" ;
VAL_ 3221225472 HU_TrafficAccident_Info 0 "No traffic accident" 1 "There is a traffic accident" 2 "Reserved" 3 "invalid" ;
VAL_ 3221225472 HU_To_Construction_Dis 0 " 0~600m" 61 "Out of Range" 62 "reserved" 63 "unknown" ;
VAL_ 3221225472 HU_Construction_Info 0 "No construction" 1 "There is construction" 2 "Reserved" 3 "invalid" ;
VAL_ 3221225472 HU_FallingRockDi 0 " 0~600m" 61 "Out of Range" 62 "reserved" 63 "unknown" ;
VAL_ 3221225472 HU_FallingRockInfo 0 "Path without rocks" 1 "Path has rocks" 2 "Reserved" 3 "invalid" ;
VAL_ 3221225472 HU_LaneCnt 0 "unknown" 1 "0x1-0x5=Number of current road lanes" 6 "Greater than or equal to 6" 7 "Single-way driving in reverse direction" ;
VAL_ 3221225472 HU_ForwardRoadType 0 "Road Type Unknown: Small road, Walking Street" 1 "Road Type Class 1: Secondary Roads" 2 "Road Type Class 2: Mainly Road in City" 3 "Road Type Class 3: Mainly Road in City, Normal Province Road, Mainly street" 4 "Road Type Class 4: Province Road, Mainly Road " 5 "Road Type Class 5: Highway, National Road, Speed road" 6 "Reserved" ;
VAL_ 3221225472 HU_RampSide 0 "Unknown" 1 "Left Road" 2 "Right Road" 3 "Invalid" ;
VAL_ 775 ACC_CSLAEnableStatus 3 "invalid" 2 "Road Camera" 1 "All Speed-Limit" 0 "OFF" ;
VAL_ 801 GW_OTAmode 15 "Reserved" 14 "Reserved" 13 "Reserved" 12 "Reserved" 11 "Reserved" 10 "Reserved" 9 "Reserved" 8 "Reserved" 7 "OTA mode 7" 6 "OTA mode 6" 5 "OTA mode 5" 4 "OTA mode 4" 3 "OTA mode 3" 2 "OTA mode 2" 1 "OTA mode 1" 0 "OTA inactive" ;
VAL_ 664 BCM_PassengerDoorStatus 1 "Open" 0 "Close" ;
VAL_ 664 BCM_LeftRearDoorStatus 1 "Open" 0 "Close" ;
VAL_ 664 BCM_DriverDoorLockStatus 3 "Error" 2 "Not used" 1 "Unlock" 0 "Lock" ;
VAL_ 664 BCM_RightRearDoorStatus 1 "Open" 0 "Close" ;
VAL_ 664 BCM_TrunkDoorStatus 1 "Open" 0 "Close" ;
VAL_ 652 GW_FIS_IACCenable_switch_signal 0 "Button not pressed" 1 "Key press" 2 "Fake button" 3 "Error" ;
VAL_ 368 EPS_ActualTorsionBarTorq 2047 "" ;
VAL_ 368 EPS_MinSafetyTorsionBarTorq 2047 "" ;
VAL_ 368 EPS_MaxSafetyTorsionBarTorq 2047 "" ;
VAL_ 916 HU_ELKEnable 0 "Inactive" 1 "OFF" 2 "ON" 3 "Reserved" ;
VAL_ 916 HU_TLAEnable 0 "Inactive" 1 "OFF" 2 "ON" 3 "Reserved" ;
VAL_ 1300 HU_LDWShakeLev 0 "inactive" 1 "low" 2 "normal" 3 "high" ;
VAL_ 1300 HU_LASWarningModeSelection 0 "inactive" 1 "visual" 2 "sound" 3 "vibration" 4 "sound and vibration" 5 "Reserved" ;
VAL_ 1300 HU_IACCEnable 0 "Inactive" 1 "Off" 2 "On" 3 "Reserved" ;
VAL_ 1300 HU_HMAEnable 0 "off" 1 "on" ;
VAL_ 1300 HU_TSRSwitch 0 "off" 1 "on" ;
VAL_ 1300 HU_LASModeSelection 0 "Inactive" 1 "LDW" 2 "LKA" 3 "LCS" 4 "Reserved" 7 "OFF" ;
VAL_ 1300 HU_OverspeedWarningOffset 0 "" 21 "Reserved" 31 "Invalid." ;
VAL_ 1300 HU_OverspeedWarningEnable 0 "Inactive" 1 "OFF" 2 "ON" 3 "Reserved" ;
VAL_ 1300 HU_OverspeedSoundWarEnable 0 "Inactive" 1 "Off" 2 "On" 3 " Reserved" ;
VAL_ 382 EPS_LatCtrlActive 0 "Not Actived" 1 "Actived" ;
VAL_ 382 EPS_LatCtrlAvailabilityStatus 0 "not Availability " 1 "Availability" 2 "failure" 3 "reserved" ;
VAL_ 382 EPS_MeasuredTorsionBarTorqValid 0 "Available" 1 "unavailable" ;
VAL_ 382 EPS_MeasuredTorsionBarTorque 1023 "" ;
VAL_ 80 SRS_PassengerBuckleSwitchStatus 0 "Buckled" 1 "Unbuckle" 2 "Not Used" 3 "Not Used" ;
VAL_ 80 SRS_WarningLampStatus 0 "Lamp off" 1 "Lamp on" 2 "Lamp Flashing" 3 "Not Used" ;
VAL_ 80 SRS_DriverBuckleSwitchStatus 0 "Buckled" 1 "Unbuckle" 2 "Not Used" 3 "Not Used" ;
VAL_ 80 SRS_CrashOutputStatusCheckSum 0 "(SRS_CrashOutputStatus) XOR 0xF" ;
VAL_ 80 SRS_CrashOutputStatus 0 "No Crash" 1 "crash " 2 "Not Used" ;
VAL_ 384 SAS_SASFailure 0 "No Failure" 1 "Failure" ;
VAL_ 384 SAS_Calibrated 0 "Calibrated" 1 " Not Calibrated" ;
VAL_ 384 SAS_SteeringAngleValid 0 "Valid " 1 "Invalid" ;
VAL_ 391 ESP_ABSFailStatus 0 "Noerror" 1 "Error" ;
VAL_ 391 ESP_ESPFunctionStatus 0 "OFF" 1 "ON" ;
VAL_ 391 ESP_TCSFailStatus 0 "Noerror" 1 "Error" ;
VAL_ 391 ESP_VehicleSpeed 0 "0~360km/h" 6401 "Reserved" 8191 "Invalid APA2.0 receive" ;
VAL_ 391 ESP_VehicleSpeedValid 0 "Valid" 1 "NotValid" ;
VAL_ 391 ESP_ESPActiveStatus 0 "NotActive" 1 "Active" ;
VAL_ 392 TCU_ShiftinProgressValid 0 "Valid" 1 "Invalid" ;
VAL_ 392 TCU_ShiftinProgress 0 "Noshift" 1 "Shift" ;
VAL_ 406 EMS_BrakePedalStatus 0 "NotPressed" 1 "Pressed" 2 "Reserved" 3 "Error" ;
VAL_ 406 EMS_EngineSpeed 0 "0~16383.5Rmp" 65535 "Invalid" ;
VAL_ 518 Wheel_Speed_FL_Valid_Data 0 "Valid" 1 "NotValid" ;
VAL_ 518 Wheel_Speed_FR_Valid_Data 0 "Valid" 1 "NotValid" ;
VAL_ 518 Wheel_Speed_FL_Direction 0 "Forward" 1 "backward" 2 "Standstill" 3 "Invalid" ;
VAL_ 518 Wheel_Speed_FR_Direction 0 "Forward" 1 "backward" 2 "Standstill" 3 "Invalid" ;
VAL_ 520 Wheel_Speed_RL_Valid_Data 0 "Valid" 1 "NotValid" ;
VAL_ 520 Wheel_Speed_RR_Valid_Data 0 "Valid" 1 "NotValid" ;
VAL_ 520 Wheel_Speed_RL_Direction 0 "Forward" 1 "backward" 2 "Standstill" 3 "Invalid" ;
VAL_ 520 Wheel_Speed_RR_Direction 0 "Forward" 1 "" 2 "Standstill" 3 "Invalid" ;
VAL_ 600 ESP_MasCylBrakePressureValid 0 "Valid" 1 "Invalid" ;
VAL_ 631 ESP_VDCActive 0 "NotActive" 1 "Active" ;
VAL_ 631 ESP_TCSActive 0 "NotActive" 1 "Active" ;
VAL_ 631 ESP_OnlyABSActive 0 "NotActive" 1 "Active" ;
VAL_ 631 ESP_VehicleStandstill 0 "notstandstill" 1 "standstill" ;
VAL_ 631 ESP_BrakeForce 0 "nobrakeforce" 1 "havebrakeforce" ;
VAL_ 632 ESP_YawRateValid 0 "Valid" 1 "Invalid" ;
VAL_ 832 AC_FrBlowType 0 "blow face" 1 "blow face/blow feet" 2 "blow feet" 3 "blow fee/defroster" 4 "defroster" 5 "Reserved" 7 "Invalid." ;
VAL_ 870 AC_EnvironmentalTemp 0 "-40~87" 255 "Invalid" ;
VAL_ 870 AC_EnvironmentalTempVD 0 "Valid" 1 "Invalid" ;
VAL_ 903 BCM_RainfallLevel 0 "No rain" 1 "Level 1" 2 "Level 2" 3 "Level 3" 4 "Level 4" 5 "Level 5?" 6 "Level 6" 7 "Level 7" 8 "Level 8" 9 "Level 9" 10 "Level 10" 11 "Level 11" 12 "Level 12" 13 "level 13" 14 "init value" 15 "Invalid value" ;
VAL_ 903 BCM_FrontWiperStatus 0 "OFF" 1 "Low" 2 "High" 3 "Error" ;
VAL_ 912 BCM_SOH_LifePercent 0 "%0-100%" 101 "Reserved" 255 "invalid" ;
VAL_ 912 BCM_PMSLevel 0 "Normal battery" 1 "Low battery" 2 "Too much power consumption" 3 "Reserved" ;
VAL_ 1280 HU_CurrentLocationLatitude 134217727 "" ;
VAL_ 1280 HU_CurrentLocationLongitude 268435455 "" ;
VAL_ 1280 HU_CurrentLocationValid 0 "Valid" 1 "Not Valid" ;
VAL_ 1281 HU_LocalTimeValid 0 "Valid" 1 "Not Valid" ;
VAL_ 422 EMS_EngineStatus 0 "Stop" 1 "Crank" 2 "Running" 3 "Reserved" ;
VAL_ 424 TCU_ActualGear 0 "Neutral" 1 "1stgear" 2 "2ndgear" 3 "3rdgear" 4 "4tgear" 5 "5tgear" 6 "6tgear" 7 "7tgear" 8 "8tgear" 9 "Reverse" 10 "Parking" 11 "Reserved" 12 "Reserved" 13 "Reserved" 14 "Reserved" 15 "Invalid" ;
VAL_ 424 TCU_ActualGearValid 0 "Valid" 1 "Invalid" ;
VAL_ 424 TCU_GearShiftPosition 0 "Parking" 1 "Reverse" 2 "Neutral" 3 "D" 4 "D3" 5 "D2" 6 "L" 7 "M_or_S" 8 "Reserved" 9 "Reserved" 10 "Reserved" 11 "Reserved" 12 "Reserved" 13 "Reserved" 14 "Unreliable" 15 "Invalid" ;
VAL_ 424 TCU_ShiftPostionValid 0 "Valid" 1 "Invalid" ;
VAL_ 591 EPS_ConcussAvailabilityStatus 0 "Concuss Availability" 1 "Concuss Active " 2 "EPS Concuss failure " 3 "reserved" ;
VAL_ 591 EPS_TorqueAssistMode 0 "Normal" 1 "light" 2 "heavy" 3 "unknow" ;
VAL_ 591 EPS_IACC_abortreason 0 "NO_DRIVING_INTERUPTION" 1 "DRIVER_RECOVERY(Over ride)" 2 "VEHICLE_SPEED ERROR" 3 "REQUEST ERROR" 4 "DAE_THERMAL_SECURITY" 5 "OTHER_DEFAULT" 6 "ADAS message Error (CD569 project 0x6=Reserved)" ;
VAL_ 651 BCM_HoodStatus 1 "Open" 0 "Close" ;
VAL_ 651 BCM_DriverDoorStatus 1 "Open" 0 "Close" ;
VAL_ 651 LCM_LASSwitch 0 "Not Push" 1 "Push" 2 "Reserved" 3 "Fault" ;
VAL_ 651 BCM_TurnIndicatorLeft 0 "OFF" 1 "ON" 2 "Not used" 3 "Error" ;
VAL_ 651 BCM_TurnIndicatorRight 0 "OFF" 1 "ON" 2 "Not used" 3 "Error" ;
VAL_ 651 BCM_emergencylightstatus 0 "OFF" 1 "ON" 2 "Not used" 3 "Error" ;
VAL_ 651 BCM_LowBeamStatus 0 "OFF" 1 "ON" 2 "Not used" 3 "Reserved" ;
VAL_ 651 BCM_HighBeamStatus 0 "OFF" 1 "ON" 2 "Not used" 3 "Reserved" ;
VAL_ 651 BCM_TurnLightSwitchSts 0 "Not Actived" 1 "Left Actived" 2 "Right Actived" 3 "Invalid" ;
VAL_ 943 HU_RampDistance 0 " 0~3000m" 301 "reserved" 1022 "Out of Range" 1023 "unknown" ;
VAL_ 943 HU_NavCurrentRoadType 0 "Road Type Unknown: Small road, Walking Street" 1 "Road Type Class 1: Secondary Roads" 2 "Road Type Class 2: Mainly Road in City" 3 "Road Type Class 3: Mainly Road in City, Normal Province Road, Mainly street" 4 "Road Type Class 4: Province Road, Mainly Road " 5 "Road Type Class 5: Highway, National Road, Speed road" 6 "Reserved" ;
VAL_ 943 HU_RampInfo 0 "Unknown" 1 "There is a ramp, but the car does not leave the high speed" 2 "The car enters the high speed through the ramp" 3 "The car exits the highway through the ramp" ;
VAL_ 943 HU_NavStatus 0 "Normal" 1 "Error" ;
VAL_ 943 HU_NavSpeedLimitStatus 3 "reserved" 2 "reserved" 1 "invalid" 0 "valid" ;
VAL_ 943 HU_NavSpeedLimit 0 "Unlimited" 1 "SL 5" 2 "SL 10" 32 "SL 160" 254 "Unknown" 255 "Invalid" ;
VAL_ 952 HU_NavGuiganceStatus 0 "No navigation guidance path" 1 "With navigation guide path" 2 "Reserved" 3 "Reserved" ;
VAL_ 952 HU_TunnelLength 0 " 0~600m" 61 "Out of Range" 62 "reserved" 63 "unknown" ;
VAL_ 952 HU_TunnelDistance 0 " 0~600m" 61 "Out of Range" 62 "reserved" 63 "unknown" ;
VAL_ 952 HU_EnterTunnelInfo 0 " unknown" 1 "Tunnel entrance" 2 "In the tunnel" 3 "Tunnel exit" ;
VAL_ 1023 BCM_AutoHeadlightSts 0 "Not Actived" 1 "Actived" ;
VAL_ 1023 BCM_FrontFoglampStatus 0 "OFF" 1 "ON" 2 "Not used" 3 "Reserved" ;
VAL_ 1023 BCM_RearFoglampStatus 0 "OFF" 1 "ON" 2 "Not used" 3 "Error" ;
VAL_ 583 APA_APAOnOff 0 "OFF" 1 "ON" ;
VAL_ 676 LCDAR_ELK_oAlert 0 "No warning" 1 "level 1" 2 "level 2" 3 "Reserved" ;
VAL_ 676 LCDAR_ELK_oStatus 0 "OFF" 1 "Inactive" 2 "Active" 3 "Failure" ;
VAL_ 676 LCDAR_Left_ELK_oAlert 0 "No warning" 1 "level 1" 2 "level 2" 3 "Reserved" ;
VAL_ 676 LCDAR_BSD_LCAStatus 0 "OFF" 1 "Inactive" 2 "Active" 3 "Failure" ;
VAL_ 922 LAS_TLAObjectType_HostLane 7 "Reserved" 6 "Reserved" 0 "no display" 1 "Round" 2 "Arrow" 3 "Turn Round" 4 "X-type" 5 "Arrow+Trun" ;
VAL_ 922 LAS_TSRRightLaneStatus 0 " off" 1 " fusion mode" 2 " vision only mode" 3 " navigation only mode" 4 " reserved" 5 " reserved" 6 " reserved" 7 " Invalid" ;
VAL_ 922 LAS_TSRLeftLaneStatus 0 " off" 1 " fusion mode" 2 " vision only mode" 3 " navigation only mode" 4 " reserved" 5 " reserved" 6 " reserved" 7 " Invalid" ;
VAL_ 922 LAS_TSRRightLaneSpdLimit 0 "no speed limit detected" 1 "SL5" 2 "SL10" 3 "SL15" 4 "SL20" 5 "SL25" 6 "SL30" 7 "SL35" 8 "SL40" 9 "SL45" 10 "SL50" 11 "SL55" 12 "SL60" 13 "SL65" 14 "SL70" 15 "SL75" 16 "SL80" 17 "SL85" 18 "SL90" 19 "SL95" 20 "SL100" 21 "SL105" 22 "SL110" 23 "SL115" 24 "SL120" 25 "SL125" 26 "SL130" 27 "SL135" 28 "SL140" 29 "SL145" 30 "SL150" 31 "SL155" 32 "SL160" 33 " Reserved" 254 " Unlimited" 255 " SLEND" ;
VAL_ 922 LAS_TSRLeftLaneSpdLimit 0 "no speed limit detected" 1 "SL5" 2 "SL10" 3 "SL15" 4 "SL20" 5 "SL25" 6 "SL30" 7 "SL35" 8 "SL40" 9 "SL45" 10 "SL50" 11 "SL55" 12 "SL60" 13 "SL65" 14 "SL70" 15 "SL75" 16 "SL80" 17 "SL85" 18 "SL90" 19 "SL95" 20 "SL100" 21 "SL105" 22 "SL110" 23 "SL115" 24 "SL120" 25 "SL125" 26 "SL130" 27 "SL135" 28 "SL140" 29 "SL145" 30 "SL150" 31 "SL155" 32 "SL160" 33 " Reserved" 254 " Unlimited" 255 " SLEND" ;
VAL_ 922 LAS_TLAStopLine_HostLane 0 "0-250m" 251 "Reserved" 255 "Out of Range" ;
VAL_ 922 LAS_TLADistance_HostLane 0 "0-250m" 251 "Reserved" 255 "Out of Range" ;
VAL_ 922 LAS_TLACountDownTime_HostLane 0 "no display" 1 "1-120s countdown" 121 "reserved" 127 "out of range" ;
VAL_ 922 LAS_TSRMandatorySign 0 "no display" 1 "One way (straight)" 2 "walk" 3 "Trunk first" 4 "Car first" 5 "Crosswalk" 6 "Bus lane" 7 "reserved" ;
VAL_ 922 LAS_TSRWarningSign 0 "no display" 1 "Reverse detour" 2 "Continuous detour" 3 "Beware of pedestrians" 4 "Attention children" 5 "Slippery" 6 "tunnel" 7 "stroll" 8 "construction" 9 "reserved" ;
VAL_ 922 LAS_TSRProhibitionSign 0 "no display" 1 "No access" 2 "No entry" 3 "Prohibition of motor vehicles" 4 "No left turn" 5 "No right turn" 6 " No Straight" 7 "o U-turn" 8 "Overtaking is prohibited" 9 "Overtaking is prohibited" 10 "Temporary or long-term parking is prohibited" 11 "Long-term parking is prohibited Parking " 12 " No honking" 13 "Parking yield" 14 "Slow down yield" 15 "Traffic yield" 16 "reserved" ;
VAL_ 922 LAS_OverspeedSoundWarningEnSt 0 "Off" 1 "On" ;
VAL_ 922 LAS_TSREnable 0 "off" 1 "on" ;
VAL_ 922 LAS_HMAEnableStatus 0 "off" 1 "on" ;
VAL_ 922 LAS_HMALightDistribution 0 " High beam not recommended" 1 " High beam recommended" ;
VAL_ 922 LAS_HMAStatus 0 " Off" 1 " Standby" 2 " Active" 3 " Failure" ;
VAL_ 922 LAS_TSRHostSpdLimitUnits 0 "no display" 1 "unit kph" 2 "unit mph" 3 "reserved" ;
VAL_ 922 LAS_TSRHostSpdLimit 0 "no speed limit detected" 1 "SL5" 2 "SL10" 3 "SL15" 4 "SL20" 5 "SL25" 6 "SL30" 7 "SL35" 8 "SL40" 9 "SL45" 10 "SL50" 11 "SL55" 12 "SL60" 13 "SL65" 14 "SL70" 15 "SL75" 16 "SL80" 17 "SL85" 18 "SL90" 19 "SL95" 20 "SL100" 21 "SL105" 22 "SL110" 23 "SL115" 24 "SL120" 25 "SL125" 26 "SL130" 27 "SL135" 28 "SL140" 29 "SL145" 30 "SL150" 31 "SL155" 32 "SL160" 33 " Reserved" 254 " Unlimited" 255 " SLEND" ;
VAL_ 922 LAS_TSRStatus 0 " off" 1 " fusion mode" 2 " vision only mode" 3 " navigation only mode" 4 " reserved" 5 " reserved" 6 " reserved" 7 " Invalid" ;
VAL_ 922 LAS_FrontCameraCalibrationStatus 0 " Calibration is ok" 1 " Calibration In Process" 2 " Calibration never done" 3 "  Calibration Failed" ;
VAL_ 922 LAS_FrontCameraFailureStatus 0 "No Error" 1 "camera blocked" 2 "temporary failure" 3 "permanent failure" ;
VAL_ 922 LAS_OverspeedWarningOffset 0 "" 21 "Reserved" 31 "Invalid." ;
VAL_ 922 LAS_OverspeedWarningEnableStatus 0 "OFF" 1 "ON" ;
VAL_ 922 LAS_OverspeedSoundWarning 0 " No Warning" 1 " Warning" ;
VAL_ 922 LAS_OverspeedVisualWarning 0 " No Warning" 1 " Warning" ;
VAL_ 922 LAS_TLAArrowDirection_RightLane 0 "no display" 1 "Forward" 2 "Left" 3 " Forward +Left" 4 "Right" 5 " Forward +Right" 6 "Right+Left" 7 "Left+ Forward +Right" ;
VAL_ 922 LAS_TLAObjectType_RightLane 7 "reserved" 6 "reserved" 0 "No Display" 1 "Round" 2 "Arrow" 3 "Turn Round" 4 "X type" 5 "Arrow Trun" ;
VAL_ 922 LAS_TLAObjectStatus_RightLane 0 "no display" 1 "Lighting" 2 "Flashing" 3 " Disappear" ;
VAL_ 922 LAS_TLAObjectColour_RightLane 0 "no display" 1 "Red" 2 "Yellow" 3 "Green" ;
VAL_ 922 LAS_TLAObjectDetection_RightLane 0 "Not Detected" 1 "Detected" ;
VAL_ 922 LAS_TLAArrowDirection_LeftLane 0 "no display" 1 "Forward" 2 "Left" 3 " Forward +Left" 4 "Right" 5 " Forward +Right" 6 "Right+Left" 7 "Left+ Forward +Right" ;
VAL_ 922 LAS_TLAObjectType_LeftLane 7 "reserved" 6 "reserved" 0 "no display" 1 "Round" 2 "Arrow" 3 "Turn Round" 4 "X-type" 5 "Arrow_Trun" ;
VAL_ 922 LAS_TLAObjectStatus_LeftLane 0 "no display" 1 "Lighting" 2 "Flashing" 3 " Disappear" ;
VAL_ 922 LAS_TLAObjectColour_LeftLane 0 "no display" 1 "Red" 2 "Yellow" 3 "Green" ;
VAL_ 922 LAS_TLAObjectDetection_LeftLane 0 "Not Detected" 1 "Detected" ;
VAL_ 922 LAS_TLAArrowDirection_HostLane 0 "no display" 1 "Forward" 2 "Left" 3 " Forward +Left" 4 "Right" 5 " Forward +Right" 6 "Right+Left" 7 "Left+ Forward +Right" ;
VAL_ 922 LAS_TLAObjectStatus_HostLane 0 "no display" 1 "Lighting" 2 "Flashing" 3 " Disappear" ;
VAL_ 922 LAS_TLAObjectColour_HostLane 0 "no display" 1 "Red" 2 "Yellow" 3 "Green" ;
VAL_ 922 LAS_TLAObjectDetection_HostLane 0 "Not Detected" 1 "Detected" ;
VAL_ 922 LAS_TLAWarninglevel 0 " no warning" 1 " warning level 1" 2 " warning level 2" 3 " warning level 3." ;
VAL_ 922 LAS_TLAStatus 0 "OFF" 1 "Standby" 2 "Active" 3 "Failure" ;
VAL_ 922 LAS_TLAEnable 0 "OFF" 1 "ON" ;
VAL_ 999 BCM_Status_Temp 0 "No error" 1 "not used" 2 "HW defect (ADC defect)" 3 "LIN saturation (no HW  defect)" ;
VAL_ 999 BCM_T_BATT 146 "reserved" 255 "Invalid" ;
VAL_ 1000 BCM_SOF_Q_STATE 0 "deviation > 15%" 1 "deviation <15%" 2 "deviation < 10%" 3 "invalid" ;
VAL_ 1000 BCM_SOF_Q 255 "Invalid" ;
VAL_ 790 LAS_Line_03_MeasureType 0 "unknown" 1 "Virtual" 2 "Measured" ;
VAL_ 790 LAS_Line_03_color 0 "Not Detected" 1 "white" 2 "yellow" 3 "white plus yellow" 4 "unknown" 5 "reserved" 7 "Invalid" ;
VAL_ 790 LAS_Line_03_Type 0 " solid" 1 "dashed" 2 "double_dashed_dashed" 3 "double_dashed_solid" 4 "double_ solid_ dashed" 5 "double_ solid_ solid" 6 " multiple(Eu&USA)" 7 "multiple_warning(Eu&USA)" 8 "car_pool" 9 "asphalt_joint(USA)" 10 "Bot-Dott(USA)" 11 " road_edge" 12 "guardrail" 13 "curbstone" 14 "wall" 15 "traffic_cone" 16 "delineator_post" 17 "parking_car" 18 "unknown_raised" 19 "fishbone" 20 "unknown" 21 "reserved" ;
VAL_ 790 LAS_Line_02_MeasureType 0 "unknown" 1 "Virtual" 2 "Measured" ;
VAL_ 790 LAS_Line_02_color 0 "Not Detected" 1 "white" 2 "yellow" 3 "white plus yellow" 4 "unknown" 5 "reserved" 7 "Invalid" ;
VAL_ 790 LAS_Line_02_Type 0 " solid" 1 "dashed" 2 "double_dashed_dashed" 3 "double_dashed_solid" 4 "double_ solid_ dashed" 5 "double_ solid_ solid" 6 " multiple(Eu&USA)" 7 "multiple_warning(Eu&USA)" 8 "car_pool" 9 "asphalt_joint(USA)" 10 "Bot-Dott(USA)" 11 " road_edge" 12 "guardrail" 13 "curbstone" 14 "wall" 15 "traffic_cone" 16 "delineator_post" 17 "parking_car" 18 "unknown_raised" 19 "fishbone" 20 "unknown" 21 "reserved" ;
VAL_ 790 LAS_Line_01_MeasureType 0 "unknown" 1 "Virtual" 2 "Measured" ;
VAL_ 790 LAS_Line_01_color 0 "Not Detected" 1 "white" 2 "yellow" 3 "white plus yellow" 4 "unknown" 5 "reserved" 7 "Invalid" ;
VAL_ 790 LAS_Line_01_Type 0 " solid" 1 "dashed" 2 "double_dashed_dashed" 3 "double_dashed_solid" 4 "double_ solid_ dashed" 5 "double_ solid_ solid" 6 " multiple(Eu&USA)" 7 "multiple_warning(Eu&USA)" 8 "car_pool" 9 "asphalt_joint(USA)" 10 "Bot-Dott(USA)" 11 " road_edge" 12 "guardrail" 13 "curbstone" 14 "wall" 15 "traffic_cone" 16 "delineator_post" 17 "parking_car" 18 "unknown_raised" 19 "fishbone" 20 "unknown" 21 "reserved" ;
VAL_ 822 LAS_Line_06_MeasureType 0 "unknown" 1 "Virtual" 2 "Measured" ;
VAL_ 822 LAS_Line_06_color 0 "Not Detected" 1 "white" 2 "yellow" 3 "white plus yellow" 4 "unknown" 5 "reserved" 7 "Invalid" ;
VAL_ 822 LAS_Line_06_Type 0 " solid" 1 "dashed" 2 "double_dashed_dashed" 3 "double_dashed_solid" 4 "double_ solid_ dashed" 5 "double_ solid_ solid" 6 " multiple(Eu&USA)" 7 "multiple_warning(Eu&USA)" 8 "car_pool" 9 "asphalt_joint(USA)" 10 "Bot-Dott(USA)" 11 " road_edge" 12 "guardrail" 13 "curbstone" 14 "wall" 15 "traffic_cone" 16 "delineator_post" 17 "parking_car" 18 "unknown_raised" 19 "fishbone" 20 "unknown" 21 "reserved" ;
VAL_ 822 LAS_Line_05_MeasureType 0 "unknown" 1 "Virtual" 2 "Measured" ;
VAL_ 822 LAS_Line_05_color 0 "Not Detected" 1 "white" 2 "yellow" 3 "white plus yellow" 4 "unknown" 5 "reserved" 7 "Invalid" ;
VAL_ 822 LAS_Line_05_Type 0 " solid" 1 "dashed" 2 "double_dashed_dashed" 3 "double_dashed_solid" 4 "double_ solid_ dashed" 5 "double_ solid_ solid" 6 " multiple(Eu&USA)" 7 "multiple_warning(Eu&USA)" 8 "car_pool" 9 "asphalt_joint(USA)" 10 "Bot-Dott(USA)" 11 " road_edge" 12 "guardrail" 13 "curbstone" 14 "wall" 15 "traffic_cone" 16 "delineator_post" 17 "parking_car" 18 "unknown_raised" 19 "fishbone" 20 "unknown" 21 "reserved" ;
VAL_ 822 LAS_Line_04_MeasureType 0 "unknown" 1 "Virtual" 2 "Measured" ;
VAL_ 822 LAS_Line_04_color 0 "Not Detected" 1 "white" 2 "yellow" 3 "white plus yellow" 4 "unknown" 5 "reserved" 7 "Invalid" ;
VAL_ 822 LAS_Line_04_Type 0 " solid" 1 "dashed" 2 "double_dashed_dashed" 3 "double_dashed_solid" 4 "double_ solid_ dashed" 5 "double_ solid_ solid" 6 " multiple(Eu&USA)" 7 "multiple_warning(Eu&USA)" 8 "car_pool" 9 "asphalt_joint(USA)" 10 "Bot-Dott(USA)" 11 " road_edge" 12 "guardrail" 13 "curbstone" 14 "wall" 15 "traffic_cone" 16 "delineator_post" 17 "parking_car" 18 "unknown_raised" 19 "fishbone" 20 "unknown" 21 "reserved" ;
VAL_ 962 HU_TollDis 0 " 0~600m" 61 "Out of Range" 62 "reserved" 63 "unknown" ;
VAL_ 962 HU_TollInfo 0 "=No toll station" 1 "There is a toll station" 2 "Reserved" 3 "invalid" ;
